VERSION "HNNBNNNYNNNNNNNNNNNNNNNNNNNNNNNNNNNNNNNNNN/4/%%%/4/'%**4NNN///"

NS_ :

BS_:

BU_: BAP_Tester Booster_AMP DSP_SKODA Gateway_PQ35 Gateway_PQ46 GSM_Pager Kompassmodul MDI Radio_2DIN Radio_Modul Radio_SKODA Rearview RNS_300_NF RNS_MFD2 RNS_midline SDARS_Tuner Sprachbedienung Standheizung Tastatur Telematik_Basis TV_hybrid UHV_High UHV_low UHV_NAR UHV_Premium UHV_UMTS

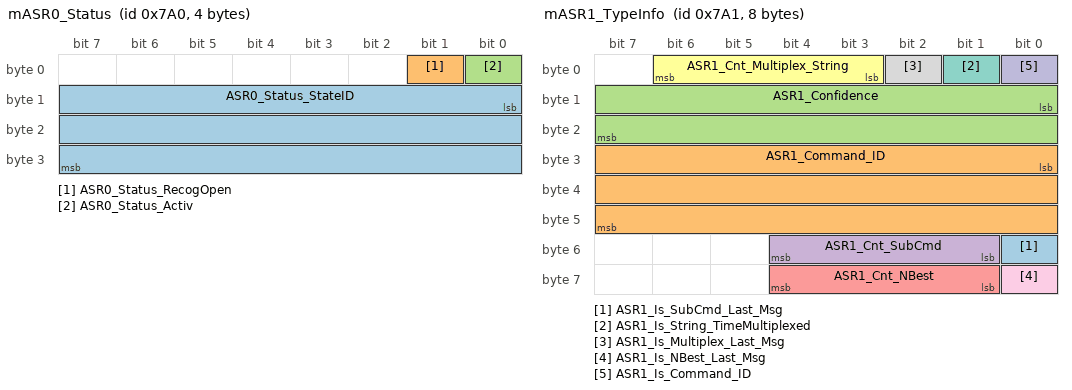
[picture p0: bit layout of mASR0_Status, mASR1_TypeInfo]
BO_ 1952 mASR0_Status: 4 UHV_NAR
 SG_ ASR0_Status_StateID : 8|24@1+ (1,8) [0|0] "" Vector__XXX
 SG_ ASR0_Status_RecogOpen : 1|1@1+ (1,0) [0|1] "" Vector__XXX
 SG_ ASR0_Status_Activ : 0|1@1+ (1,0) [0|1] "" Vector__XXX

BO_ 1953 mASR1_TypeInfo: 8 UHV_NAR
 SG_ ASR1_Is_SubCmd_Last_Msg : 48|1@1+ (1,0) [0|0] "" Vector__XXX
 SG_ ASR1_Command_ID : 24|24@1+ (1,0) [0|0] "" Vector__XXX
 SG_ ASR1_Confidence : 8|16@1+ (1,0) [0|10000] "" Vector__XXX
 SG_ ASR1_Cnt_SubCmd : 49|4@1+ (1,0) [0|15] "" Vector__XXX
 SG_ ASR1_Cnt_NBest : 57|4@1+ (1,0) [0|15] "" Vector__XXX
 SG_ ASR1_Cnt_Multiplex_String : 3|4@1+ (1,0) [0|1] "" Vector__XXX
 SG_ ASR1_Is_String_TimeMultiplexed : 1|1@1+ (1,0) [0|1] "" Vector__XXX
 SG_ ASR1_Is_Multiplex_Last_Msg : 2|1@1+ (1,0) [0|1] "" Vector__XXX
 SG_ ASR1_Is_NBest_Last_Msg : 56|1@1+ (1,0) [0|1] "" Vector__XXX
 SG_ ASR1_Is_Command_ID : 0|1@1+ (1,0) [0|1] "" Vector__XXX

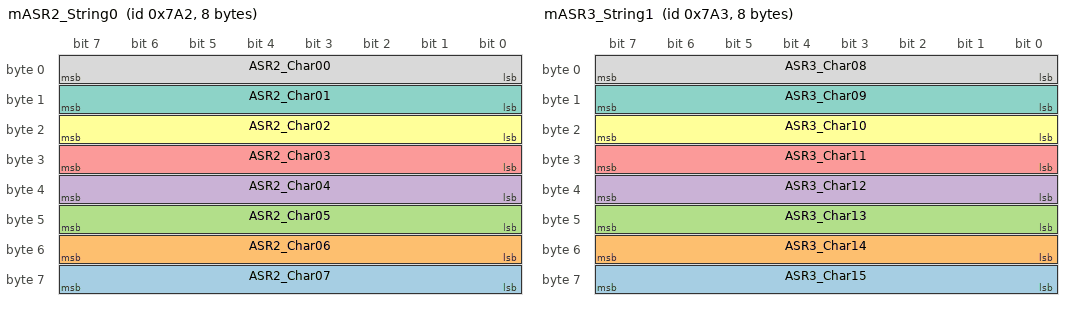
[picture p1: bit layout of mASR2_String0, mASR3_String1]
BO_ 1954 mASR2_String0: 8 UHV_NAR
 SG_ ASR2_Char07 : 56|8@1+ (1,0) [0|0] "" Vector__XXX
 SG_ ASR2_Char06 : 48|8@1+ (1,0) [0|0] "" Vector__XXX
 SG_ ASR2_Char05 : 40|8@1+ (1,0) [0|0] "" Vector__XXX
 SG_ ASR2_Char04 : 32|8@1+ (1,0) [0|0] "" Vector__XXX
 SG_ ASR2_Char03 : 24|8@1+ (1,0) [0|0] "" Vector__XXX
 SG_ ASR2_Char02 : 16|8@1+ (1,0) [0|0] "" Vector__XXX
 SG_ ASR2_Char01 : 8|8@1+ (1,0) [0|0] "" Vector__XXX
 SG_ ASR2_Char00 : 0|8@1+ (1,0) [0|0] "" Vector__XXX

BO_ 1955 mASR3_String1: 8 UHV_NAR
 SG_ ASR3_Char15 : 56|8@1+ (1,0) [0|0] "" Vector__XXX
 SG_ ASR3_Char14 : 48|8@1+ (1,0) [0|0] "" Vector__XXX
 SG_ ASR3_Char13 : 40|8@1+ (1,0) [0|0] "" Vector__XXX
 SG_ ASR3_Char12 : 32|8@1+ (1,0) [0|0] "" Vector__XXX
 SG_ ASR3_Char11 : 24|8@1+ (1,0) [0|0] "" Vector__XXX
 SG_ ASR3_Char10 : 16|8@1+ (1,0) [0|0] "" Vector__XXX
 SG_ ASR3_Char09 : 8|8@1+ (1,0) [0|0] "" Vector__XXX
 SG_ ASR3_Char08 : 0|8@1+ (1,0) [0|0] "" Vector__XXX

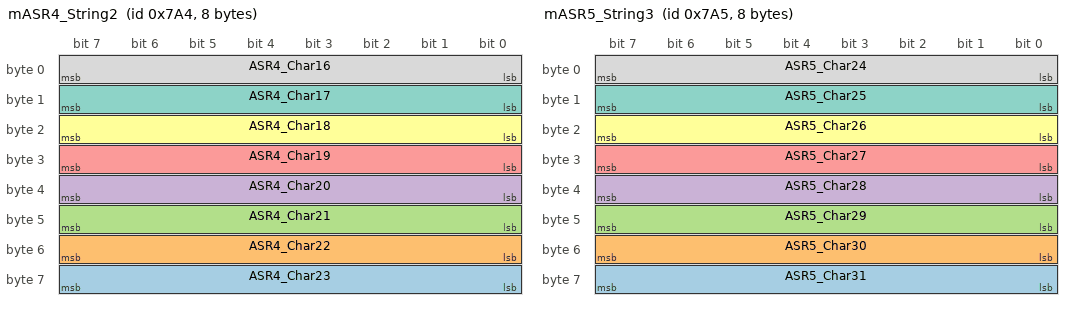
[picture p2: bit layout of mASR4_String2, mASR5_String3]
BO_ 1956 mASR4_String2: 8 UHV_NAR
 SG_ ASR4_Char23 : 56|8@1+ (1,0) [0|0] "" Vector__XXX
 SG_ ASR4_Char22 : 48|8@1+ (1,0) [0|0] "" Vector__XXX
 SG_ ASR4_Char21 : 40|8@1+ (1,0) [0|0] "" Vector__XXX
 SG_ ASR4_Char20 : 32|8@1+ (1,0) [0|0] "" Vector__XXX
 SG_ ASR4_Char19 : 24|8@1+ (1,0) [0|0] "" Vector__XXX
 SG_ ASR4_Char18 : 16|8@1+ (1,0) [0|0] "" Vector__XXX
 SG_ ASR4_Char17 : 8|8@1+ (1,0) [0|0] "" Vector__XXX
 SG_ ASR4_Char16 : 0|8@1+ (1,0) [0|0] "" Vector__XXX

BO_ 1957 mASR5_String3: 8 UHV_NAR
 SG_ ASR5_Char31 : 56|8@1+ (1,0) [0|0] "" Vector__XXX
 SG_ ASR5_Char30 : 48|8@1+ (1,0) [0|0] "" Vector__XXX
 SG_ ASR5_Char29 : 40|8@1+ (1,0) [0|0] "" Vector__XXX
 SG_ ASR5_Char28 : 32|8@1+ (1,0) [0|0] "" Vector__XXX
 SG_ ASR5_Char27 : 24|8@1+ (1,0) [0|0] "" Vector__XXX
 SG_ ASR5_Char26 : 16|8@1+ (1,0) [0|0] "" Vector__XXX
 SG_ ASR5_Char25 : 8|8@1+ (1,0) [0|0] "" Vector__XXX
 SG_ ASR5_Char24 : 0|8@1+ (1,0) [0|0] "" Vector__XXX

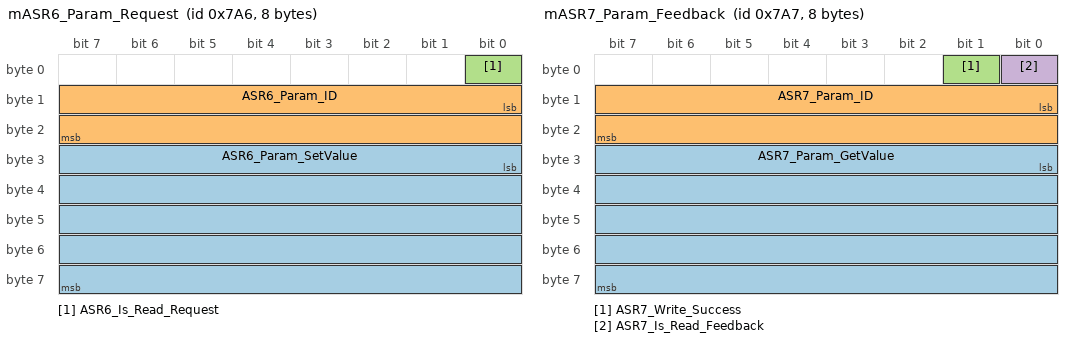
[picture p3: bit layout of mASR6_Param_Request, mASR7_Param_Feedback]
BO_ 1958 mASR6_Param_Request: 8 Vector__XXX
 SG_ ASR6_Param_SetValue : 24|40@1+ (1,0) [0|0] ""  UHV_NAR
 SG_ ASR6_Param_ID : 8|16@1+ (1,0) [0|0] ""  UHV_NAR
 SG_ ASR6_Is_Read_Request : 0|1@1+ (1,0) [0|1] ""  UHV_NAR

BO_ 1959 mASR7_Param_Feedback: 8 Vector__XXX
 SG_ ASR7_Param_GetValue : 24|40@1+ (1,0) [0|0] ""  UHV_NAR
 SG_ ASR7_Param_ID : 8|16@1+ (1,0) [0|0] ""  UHV_NAR
 SG_ ASR7_Write_Success : 1|1@1+ (1,0) [0|1] ""  UHV_NAR
 SG_ ASR7_Is_Read_Feedback : 0|1@1+ (1,0) [0|1] ""  UHV_NAR

BO_ 1658 BAP_Anzeige_02: 8 Radio_Modul
 SG_ BAP_Data_Anzeige_02 : 0|16@1+ (1,0) [0|65535] ""  Gateway_PQ35,Gateway_PQ46

BO_ 1753 BAP_Anzeige_RV: 8 Vector__XXX
 SG_ BAP_Data_Anzeige_RV : 0|16@1+ (1,0) [0|65535] ""  Gateway_PQ35,Gateway_PQ46

BO_ 1737 BAP_ASG_02: 8 Gateway_PQ35
 SG_ BAP_Data_ASG_02 : 0|16@1+ (1,0) [0|65535] ""  Standheizung

BO_ 1735 BAP_ASG_03: 8 Radio_Modul
 SG_ BAP_Data_ASG_03 : 0|16@1+ (1,0) [0|65535] ""  Booster_AMP,TV_hybrid,UHV_High,UHV_NAR,UHV_Premium,UHV_UMTS

BO_ 1738 BAP_ASG_04: 8 Radio_Modul
 SG_ BAP_Data_ASG_04 : 0|16@1+ (1,0) [0|65535] ""  Rearview

BO_ 1739 BAP_ASG_05: 8 Radio_Modul
 SG_ BAP_Data_ASG_05 : 0|16@1+ (1,0) [0|65535] ""  Gateway_PQ35,Gateway_PQ46

BO_ 1734 BAP_ASG_06: 8 Radio_Modul
 SG_ BAP_Data_ASG_06 : 0|16@1+ (1,0) [0|65535] ""  MDI,UHV_High,UHV_NAR,UHV_Premium,UHV_UMTS

BO_ 1660 BAP_ASG_07: 8 Gateway_PQ35
 SG_ BAP_Data_ASG_07 : 0|16@1+ (1,0) [0|65535] ""  Kompassmodul,Radio_2DIN,Radio_Modul,RNS_300_NF,RNS_midline,UHV_High,UHV_NAR,UHV_Premium,UHV_UMTS

BO_ 1733 BAP_ASG_08: 8 Radio_Modul
 SG_ BAP_Data_ASG_08 : 0|16@1+ (1,0) [0|65535] ""  Booster_AMP

BO_ 1774 BAP_ASG_09: 8 RNS_midline
 SG_ BAP_Data_ASG_09 : 0|16@1+ (1,0) [0|65535] ""  Gateway_PQ35,Gateway_PQ46

BO_ 1644 BAP_AUDIO: 8 Radio_2DIN
 SG_ BAP_Data_AUDIO : 0|16@1+ (1,0) [0|65535] ""  Gateway_PQ35,Gateway_PQ46

BO_ 1768 BAP_BC: 8 Gateway_PQ35
 SG_ BAP_Data_BC : 0|16@1+ (1,0) [0|65535] ""  RNS_midline

BO_ 1755 BAP_Clima: 8 Gateway_PQ35
 SG_ BAP_Data_Clima : 0|16@1+ (1,0) [0|65535] ""  Radio_Modul,RNS_300_NF,RNS_midline

BO_ 1750 BAP_Debug_Cmd: 8 BAP_Tester
 SG_ BAP_Data_Debug_Cmd : 0|16@1+ (1,0) [0|65535] ""  Booster_AMP,Kompassmodul,MDI,Radio_2DIN,Radio_Modul,Rearview,RNS_300_NF,RNS_midline,Standheizung,TV_hybrid,UHV_High,UHV_NAR,UHV_Premium,UHV_UMTS

BO_ 1751 BAP_Debug_Data: 7 Booster_AMP
 SG_ BAP_Debug_Data : 0|56@1+ (1,0) [0|4294967295] ""  BAP_Tester

BO_ 1752 BAP_DSP: 8 Booster_AMP
 SG_ BAP_Data_DSP : 0|16@1+ (1,0) [0|65535] ""  Radio_Modul,RNS_300_NF,RNS_midline

BO_ 1657 BAP_HYB: 8 Gateway_PQ35
 SG_ BAP_Data_HYB : 0|16@1+ (1,0) [0|65535] ""  RNS_midline

BO_ 1596 BAP_MDI: 8 MDI
 SG_ BAP_Data_MDI : 0|16@1+ (1,0) [0|65535] ""  Radio_Modul,RNS_300_NF,RNS_midline

BO_ 1580 BAP_MDI_02: 8 UHV_NAR
 SG_ BAP_Data_MDI_02 : 0|16@1+ (1,0) [0|65535] ""  Radio_Modul,RNS_300_NF,RNS_midline

BO_ 1661 BAP_NAVI: 8 Kompassmodul
 SG_ BAP_Data_NAVI : 0|16@1+ (1,0) [0|65535] ""  Gateway_PQ35,Gateway_PQ46

BO_ 1754 BAP_OPS: 8 Gateway_PQ35
 SG_ BAP_Data_OPS : 0|16@1+ (1,0) [0|65535] ""  Radio_Modul,RNS_300_NF,RNS_midline

BO_ 1756 BAP_RV: 8 Gateway_PQ35
 SG_ BAP_Data_Rearview : 0|16@1+ (1,0) [0|65535] ""  Radio_Modul,RNS_300_NF,RNS_midline

BO_ 1646 BAP_SHZ: 8 Standheizung
 SG_ BAP_Data_SHZ : 0|16@1+ (1,0) [0|65535] ""  Gateway_PQ35,Gateway_PQ46

BO_ 1746 BAP_Telefon_01: 8 UHV_High
 SG_ BAP_Data_Telefon_1 : 0|16@1+ (1,0) [0|65535] ""  Radio_Modul,RNS_300_NF,RNS_midline

BO_ 1749 BAP_Telefon_02: 8 UHV_High
 SG_ BAP_Data_Telefon_2 : 0|16@1+ (1,0) [0|65535] ""  Radio_Modul,RNS_300_NF,RNS_midline

BO_ 1595 BAP_Telefon_03: 8 UHV_High
 SG_ BAP_Data_Telefon_3 : 0|16@1+ (1,0) [0|65535] ""  Radio_Modul,RNS_300_NF,RNS_midline

BO_ 1647 BAP_Telefon_04: 8 UHV_High
 SG_ BAP_Data_Telefon_4 : 0|16@1+ (1,0) [0|65535] ""  Gateway_PQ35,Gateway_PQ46

BO_ 1747 BAP_TV_Tuner: 8 TV_hybrid
 SG_ BAP_Data_TV_Tuner : 0|16@1+ (1,0) [0|65535] ""  RNS_midline

BO_ 1903 ISO_AMP_Req: 8 Gateway_PQ35
 SG_ ISO_AMP_Req_Data : 0|64@1+ (1,0) [0|4294967295] ""  Booster_AMP

BO_ 2009 ISO_AMP_Resp: 8 Booster_AMP
 SG_ ISO_AMP_Resp_Data : 0|64@1+ (1,0) [0|4294967295] ""  Gateway_PQ35,Gateway_PQ46

BO_ 1792 ISO_Funktionaler_Req_All: 8 Gateway_PQ35
 SG_ ISO_ALL_01_Req_Data : 0|64@1+ (1,0) [0|4294967295] ""  Booster_AMP,Radio_Modul,RNS_300_NF,UHV_NAR,UHV_UMTS

BO_ 1907 ISO_Info_El_Req: 8 Gateway_PQ35
 SG_ ISO_Info_El_Req_Data : 0|64@1+ (1,0) [0|4294967295] "" Vector__XXX

BO_ 2013 ISO_Info_El_Resp: 8 Vector__XXX
 SG_ ISO_Info_El_Resp_Data : 0|64@1+ (1,0) [0|4294967295] ""  Gateway_PQ35,Gateway_PQ46

BO_ 1902 ISO_MDI_Req: 8 Gateway_PQ35
 SG_ ISO_MDI_Req_Data : 0|64@1+ (1,0) [0|4294967295] "" Vector__XXX

BO_ 2008 ISO_MDI_Resp: 8 Vector__XXX
 SG_ ISO_MDI_Resp_Data : 0|64@1+ (1,0) [0|4294967295] ""  Gateway_PQ35,Gateway_PQ46

BO_ 1900 ISO_Navi_Req: 8 Gateway_PQ35
 SG_ ISO_Navi_Req_Data : 0|64@1+ (1,0) [0|4294967295] ""  RNS_300_NF

BO_ 2006 ISO_Navi_Resp: 8 RNS_300_NF
 SG_ ISO_Navi_Resp_Data : 0|64@1+ (1,0) [0|4294967295] ""  Gateway_PQ35,Gateway_PQ46

BO_ 1816 ISO_Radio_Req: 8 Gateway_PQ35
 SG_ ISO_Radio_Req_Data : 0|64@1+ (1,0) [0|4294967295] ""  Radio_Modul

BO_ 1922 ISO_Radio_Resp: 8 Radio_Modul
 SG_ ISO_Radio_Resp_Data : 0|64@1+ (1,0) [0|4294967295] ""  Gateway_PQ35,Gateway_PQ46

BO_ 1899 ISO_Telefon_Req: 8 Gateway_PQ35
 SG_ ISO_Telefon_Req_Data : 0|64@1+ (1,0) [0|4294967295] ""  UHV_NAR,UHV_UMTS

BO_ 2005 ISO_Telefon_Resp: 8 UHV_NAR
 SG_ ISO_Telefon_Resp_Data : 0|64@1+ (1,0) [0|4294967295] ""  Gateway_PQ35,Gateway_PQ46

BO_ 1901 ISO_TV_Tuner_Req: 8 Gateway_PQ35
 SG_ ISO_TV_Tuner_Req_Data : 0|64@1+ (1,0) [0|4294967295] "" Vector__XXX

BO_ 2007 ISO_TV_Tuner_Resp: 8 Vector__XXX
 SG_ ISO_TV_Tuner_Resp_Data : 0|64@1+ (1,0) [0|4294967295] ""  Gateway_PQ35,Gateway_PQ46

BO_ 337 mAirbag_1: 4 Gateway_PQ35
 SG_ AB1_FrontCrash : 0|1@1+ (1,0) [0|1] ""  Telematik_Basis,UHV_NAR,UHV_UMTS
 SG_ AB1_HeckCrash : 1|1@1+ (1,0) [0|1] ""  Telematik_Basis,UHV_NAR,UHV_UMTS
 SG_ AB1_Crash_FT : 2|1@1+ (1,0) [0|1] ""  Telematik_Basis,UHV_NAR,UHV_UMTS
 SG_ AB1_Crash_BT : 3|1@1+ (1,0) [0|1] ""  Telematik_Basis,UHV_NAR,UHV_UMTS
 SG_ AB1_Rollover : 4|1@1+ (1,0) [0|1] ""  Telematik_Basis,UHV_NAR,UHV_UMTS
 SG_ AB1_CrashStaerke : 5|3@1+ (1,0) [0|7] ""  Standheizung,Telematik_Basis,UHV_NAR,UHV_UMTS
 SG_ AB1_AirbagLampe_ein : 8|1@1+ (1,0) [0|1] "" Vector__XXX
 SG_ AB1_Airbag_deaktiviert : 9|1@1+ (1,0) [0|1] "" Vector__XXX
 SG_ AB1_Beif_Airbag_deaktiviert : 10|1@1+ (1,0) [0|1] "" Vector__XXX
 SG_ AB1_Systemfehler : 11|1@1+ (1,0) [0|1] "" Vector__XXX
 SG_ AB1_Fa_Gurt : 12|2@1+ (1,0) [0|3] "" Vector__XXX
 SG_ AB1_Bf_Gurt : 14|2@1+ (1,0) [0|3] "" Vector__XXX
 SG_ AB1_Diagnose : 16|1@1+ (1,0) [0|1] "" Vector__XXX
 SG_ AB1_Stellglied : 17|1@1+ (1,0) [0|1] "" Vector__XXX
 SG_ AB1_BF_Anschnall : 18|1@1+ (1,0) [0|1] "" Vector__XXX
 SG_ AB1_KD_Fehler : 19|1@1+ (1,0) [0|1] "" Vector__XXX
 SG_ AB1_MessageZaehler : 20|4@1+ (1,0) [0|15] ""  Telematik_Basis
 SG_ AB1_Pruefsumme : 24|8@1+ (1,0) [0|255] ""  Telematik_Basis

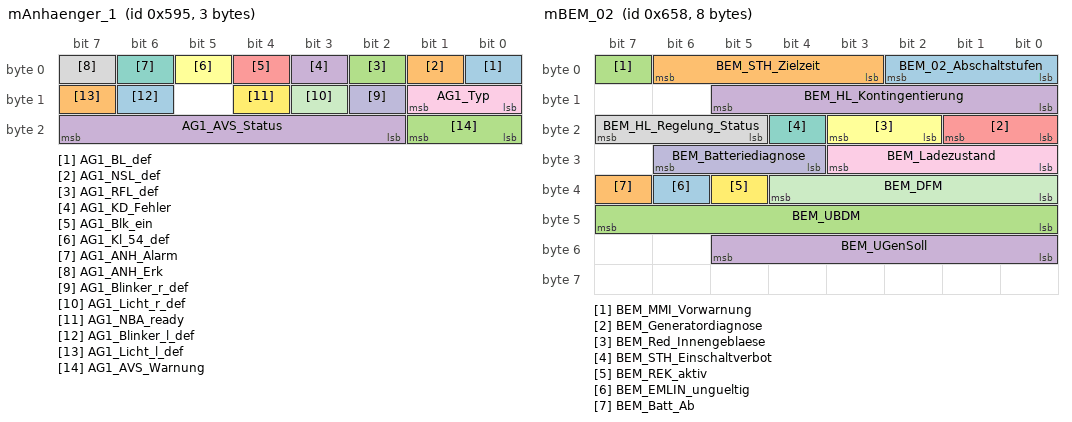
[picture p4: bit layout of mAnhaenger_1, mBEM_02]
BO_ 1429 mAnhaenger_1: 3 Gateway_PQ35
 SG_ AG1_BL_def : 0|1@1+ (1,0) [0|1] "" Vector__XXX
 SG_ AG1_NSL_def : 1|1@1+ (1,0) [0|1] "" Vector__XXX
 SG_ AG1_RFL_def : 2|1@1+ (1,0) [0|1] "" Vector__XXX
 SG_ AG1_KD_Fehler : 3|1@1+ (1,0) [0|1] "" Vector__XXX
 SG_ AG1_Blk_ein : 4|1@1+ (1,0) [0|1] "" Vector__XXX
 SG_ AG1_Kl_54_def : 5|1@1+ (1,0) [0|1] "" Vector__XXX
 SG_ AG1_ANH_Alarm : 6|1@1+ (1,0) [0|1] "" Vector__XXX
 SG_ AG1_ANH_Erk : 7|1@1+ (1,0) [0|1] ""  Rearview
 SG_ AG1_Typ : 8|2@1+ (1,0) [0|3] "" Vector__XXX
 SG_ AG1_Blinker_r_def : 10|1@1+ (1,0) [0|1] "" Vector__XXX
 SG_ AG1_Licht_r_def : 11|1@1+ (1,0) [0|1] "" Vector__XXX
 SG_ AG1_NBA_ready : 12|1@1+ (1,0) [0|1] "" Vector__XXX
 SG_ AG1_Blinker_l_def : 14|1@1+ (1,0) [0|1] "" Vector__XXX
 SG_ AG1_Licht_l_def : 15|1@1+ (1,0) [0|1] "" Vector__XXX
 SG_ AG1_AVS_Warnung : 16|2@1+ (1,0) [0|3] "" Vector__XXX
 SG_ AG1_AVS_Status : 18|6@1+ (1,0) [0|63] "" Vector__XXX

BO_ 1624 mBEM_02: 8 Gateway_PQ35
 SG_ BEM_02_Abschaltstufen : 0|3@1+ (1,0) [0|7] "" Vector__XXX
 SG_ BEM_STH_Zielzeit : 3|4@1+ (5,0) [0|60] "Unit_Minut" Vector__XXX
 SG_ BEM_MMI_Vorwarnung : 7|1@1+ (1,0) [0|1] "" Vector__XXX
 SG_ BEM_HL_Kontingentierung : 8|6@1+ (50,-1000) [-1000|1000] "Unit_Watt" Vector__XXX
 SG_ BEM_Generatordiagnose : 16|2@1+ (1,0) [0|3] "" Vector__XXX
 SG_ BEM_Red_Innengeblaese : 18|2@1+ (1,0) [0|3] "" Vector__XXX
 SG_ BEM_STH_Einschaltverbot : 20|1@1+ (1,0) [0|1] "" Vector__XXX
 SG_ BEM_HL_Regelung_Status : 21|3@1+ (1,0) [0|7] "" Vector__XXX
 SG_ BEM_Ladezustand : 24|4@1+ (10,0) [0|100] "Unit_PerCent" Vector__XXX
 SG_ BEM_Batteriediagnose : 28|3@1+ (1,0) [0|7] "" Vector__XXX
 SG_ BEM_DFM : 32|5@1+ (3.225,0.025) [0.025|100] "Unit_PerCent" Vector__XXX
 SG_ BEM_REK_aktiv : 37|1@1+ (1,0) [0|1] "" Vector__XXX
 SG_ BEM_EMLIN_ungueltig : 38|1@1+ (1,0) [0|1] "" Vector__XXX
 SG_ BEM_Batt_Ab : 39|1@1+ (1,0) [0|1] "" Vector__XXX
 SG_ BEM_UBDM : 40|8@1+ (0.05,5) [5|17.7] "Unit_Volt" Vector__XXX
 SG_ BEM_UGenSoll : 48|6@1+ (0.1,10.6) [10.6|16.8] "Unit_Volt" Vector__XXX

BO_ 1461 mBremse_10: 8 Gateway_PQ35
 SG_ B10_Checksumme : 0|8@1+ (1,0) [0|255] ""  RNS_300_NF
 SG_ B10_Zaehler : 8|4@1+ (1,0) [0|15] ""  RNS_300_NF
 SG_ B10_QB_Wegimp_VL : 12|1@1+ (1,0) [0|1] ""  RNS_300_NF
 SG_ B10_QB_Wegimp_VR : 13|1@1+ (1,0) [0|1] ""  RNS_300_NF
 SG_ B10_QB_Wegimp_HL : 14|1@1+ (1,0) [0|1] ""  RNS_300_NF
 SG_ B10_QB_Wegimp_HR : 15|1@1+ (1,0) [0|1] ""  RNS_300_NF
 SG_ B10_Wegimp_VL : 16|10@1+ (1,0) [0|1000] ""  RNS_300_NF
 SG_ B10_Wegimp_VR : 26|10@1+ (1,0) [0|1000] ""  RNS_300_NF
 SG_ B10_Wegimp_HL : 36|10@1+ (1,0) [0|1000] ""  RNS_300_NF
 SG_ B10_Wegimp_HR : 46|10@1+ (1,0) [0|1000] ""  RNS_300_NF
 SG_ B10_QB_Fahrtr_VL : 56|1@1+ (1,0) [0|1] ""  RNS_300_NF
 SG_ B10_QB_Fahrtr_VR : 57|1@1+ (1,0) [0|1] ""  RNS_300_NF
 SG_ B10_QB_Fahrtr_HL : 58|1@1+ (1,0) [0|1] ""  RNS_300_NF
 SG_ B10_QB_Fahrtr_HR : 59|1@1+ (1,0) [0|1] ""  RNS_300_NF
 SG_ B10_Fahrtr_VL : 60|1@1+ (1,0) [0|1] ""  RNS_300_NF
 SG_ B10_Fahrtr_VR : 61|1@1+ (1,0) [0|1] ""  RNS_300_NF
 SG_ B10_Fahrtr_HL : 62|1@1+ (1,0) [0|1] ""  RNS_300_NF
 SG_ B10_Fahrtr_HR : 63|1@1+ (1,0) [0|1] ""  RNS_300_NF

BO_ 1393 mBSG_2: 6 Gateway_PQ35
 SG_ BS2_U_BATT : 0|8@1+ (0.05,5) [5|17.7] "Unit_Volt"  GSM_Pager,Telematik_Basis
 SG_ BS2_Heckscheibe_aus : 8|1@1+ (1,0) [0|1] "" Vector__XXX
 SG_ BS2_Frontscheibe_aus : 9|1@1+ (1,0) [0|1] "" Vector__XXX
 SG_ BS2_Aussenspiegel_aus : 10|1@1+ (1,0) [0|1] "" Vector__XXX
 SG_ BS2_Sitzheizung_aus : 11|1@1+ (1,0) [0|1] "" Vector__XXX
 SG_ BS2_aus_Lenkradheizung : 12|1@1+ (1,0) [0|1] "" Vector__XXX
 SG_ BS2_aus_Wischwasserhzg : 13|1@1+ (1,0) [0|1] "" Vector__XXX
 SG_ BS2_aus_Sitzlueftung : 14|1@1+ (1,0) [0|1] "" Vector__XXX
 SG_ BS2_Klimaanlage_aus : 15|1@1+ (1,0) [0|1] "" Vector__XXX
 SG_ BS2_U_Start_BATT : 16|8@1+ (0.05,5) [5|17.7] "Unit_Volt" Vector__XXX
 SG_ BS2_Lastman_aktiv : 24|1@1+ (1,0) [0|1] "" Vector__XXX
 SG_ BS2_Verbr_ab_aktiv : 25|1@1+ (1,0) [0|1] "" Vector__XXX
 SG_ BS2_Notstart : 26|1@1+ (1,0) [0|1] "" Vector__XXX
 SG_ BS2_aus_Sitzhzg_H : 27|1@1+ (1,0) [0|1] "" Vector__XXX
 SG_ BS2_aus_Steckdosen : 28|1@1+ (1,0) [0|1] "" Vector__XXX
 SG_ BS2_aus_Zusatz_Verbr : 29|1@1+ (1,0) [0|1] "" Vector__XXX
 SG_ BS2_aus_Infotainment : 30|1@1+ (1,0) [0|1] ""  Booster_AMP,DSP_SKODA,Radio_2DIN,Radio_Modul,Radio_SKODA,RNS_300_NF,RNS_midline,UHV_low,UHV_NAR,UHV_Premium,UHV_UMTS
 SG_ BS2_Wake_Up_ACAN : 31|1@1+ (1,0) [0|1] "" Vector__XXX
 SG_ BS2_aus_PTC_Clima : 32|3@1+ (25,0) [0|100] "Unit_PerCent" Vector__XXX
 SG_ BS2_KlimaLeistRed : 35|2@1+ (1,0) [0|3] ""  Standheizung
 SG_ BS2_red_Heckscheibe : 37|1@1+ (1,0) [0|1] "" Vector__XXX
 SG_ BS2_aus_Ablage_Wischer : 38|1@1+ (1,0) [0|1] "" Vector__XXX
 SG_ BS2_aus_Innen_Bel : 39|1@1+ (1,0) [0|1] "" Vector__XXX
 SG_ BS2_Warn_Steckdosen : 40|1@1+ (1,0) [0|1] "" Vector__XXX
 SG_ BS2_Warn_Infotainment : 41|1@1+ (1,0) [0|1] ""  Booster_AMP,DSP_SKODA,Radio_2DIN,Radio_Modul,Radio_SKODA,RNS_300_NF,RNS_midline,Telematik_Basis,UHV_low,UHV_NAR,UHV_Premium,UHV_UMTS
 SG_ BS2_Warn_Zusatz : 42|1@1+ (1,0) [0|1] ""  Telematik_Basis
 SG_ BS2_Weckursache_ACAN : 43|2@1+ (1,0) [0|3] "" Vector__XXX
 SG_ BS2_VB_2_Battarie : 45|1@1+ (1,0) [0|1] ""  Standheizung
 SG_ BS2_Zust_Start_Ltg : 46|1@1+ (1,0) [0|1] "" Vector__XXX
 SG_ BS2_Mess_Start_Ltg : 47|1@1+ (1,0) [0|1] "" Vector__XXX

BO_ 1397 mBSG_3: 4 Gateway_PQ35
 SG_ BS3_Klemme_S : 0|1@1+ (1,0) [0|1] ""  Booster_AMP,DSP_SKODA,GSM_Pager,Kompassmodul,MDI,Radio_2DIN,Radio_Modul,Radio_SKODA,Rearview,RNS_300_NF,RNS_MFD2,RNS_midline,SDARS_Tuner,Sprachbedienung,Standheizung,Tastatur,Telematik_Basis,TV_hybrid,UHV_High,UHV_low,UHV_NAR,UHV_Premium,UHV_UMTS
 SG_ BS3_Klemme_15 : 1|1@1+ (1,0) [0|1] ""  Booster_AMP,DSP_SKODA,GSM_Pager,Kompassmodul,MDI,Radio_2DIN,Radio_Modul,Radio_SKODA,Rearview,RNS_300_NF,RNS_MFD2,RNS_midline,SDARS_Tuner,Sprachbedienung,Standheizung,Tastatur,Telematik_Basis,TV_hybrid,UHV_High,UHV_low,UHV_NAR,UHV_Premium,UHV_UMTS
 SG_ BS3_Klemme_X : 2|1@1+ (1,0) [0|1] ""  Radio_Modul,Standheizung,Telematik_Basis
 SG_ BS3_Klemme_50 : 3|1@1+ (1,0) [0|1] ""  Radio_2DIN,Radio_Modul,Standheizung,Telematik_Basis
 SG_ BS3_Klemme_P : 4|1@1+ (1,0) [0|1] ""  Telematik_Basis
 SG_ BS3_2_Drehzahl : 5|1@1+ (1,0) [0|1] "" Vector__XXX
 SG_ BS3_Klemme_15_Motorraum : 6|1@1+ (1,0) [0|1] "" Vector__XXX
 SG_ BS3_Ladekontrollampe : 7|1@1+ (1,0) [0|1] ""  GSM_Pager
 SG_ BS3_Drehzahlanhebung : 8|1@1+ (1,0) [0|1] "" Vector__XXX
 SG_ BS3_Bordnetzbatt : 9|2@1+ (1,0) [0|3] ""  Standheizung,Telematik_Basis
 SG_ BS3_Starterbatt : 11|2@1+ (1,0) [0|3] "" Vector__XXX
 SG_ BS3_KD_Fehler : 13|1@1+ (1,0) [0|1] "" Vector__XXX
 SG_ BS3_LWR_Fehler : 14|1@1+ (1,0) [0|1] "" Vector__XXX
 SG_ BS3_Haubenkontakt : 15|1@1+ (1,0) [0|1] "" Vector__XXX
 SG_ BS3_Coming_Home : 16|1@1+ (1,0) [0|1] "" Vector__XXX
 SG_ BS3_Leaving_Home : 17|1@1+ (1,0) [0|1] "" Vector__XXX
 SG_ BS3_K_Luefter_ein : 18|1@1+ (1,0) [0|1] "" Vector__XXX
 SG_ BS3_Ab_Batterie : 19|1@1+ (1,0) [0|1] "" Vector__XXX
 SG_ BS3_VP_Taste : 20|1@1+ (1,0) [0|1] "" Vector__XXX
 SG_ BS3_Verglasung_zu : 21|1@1+ (1,0) [0|1] "" Vector__XXX
 SG_ BS3_PDC_Taster : 22|1@1+ (1,0) [0|1] "" Vector__XXX
 SG_ BS3_IRUE_Taster : 23|1@1+ (1,0) [0|1] "" Vector__XXX
 SG_ BS3_VB_Coming_Home : 24|1@1+ (1,0) [0|1] "" Vector__XXX
 SG_ BS3_VB_Tagesfahrlicht : 25|1@1+ (1,0) [0|1] "" Vector__XXX
 SG_ BS3_VB_Fussraumleuchten : 26|1@1+ (1,0) [0|1] "" Vector__XXX
 SG_ BS3_LED_Heckscheibe : 27|1@1+ (1,0) [0|1] ""  Kompassmodul,Radio_SKODA
 SG_ BS3_LED_Frontscheibe : 28|1@1+ (1,0) [0|1] ""  Kompassmodul,Radio_SKODA
 SG_ BS3_LED_Sitze : 29|1@1+ (1,0) [0|1] "" Vector__XXX
 SG_ BS3_LED_Aussenspiegel : 30|1@1+ (1,0) [0|1] "" Vector__XXX
 SG_ BS3_Starterlaubnis : 31|1@1+ (1,0) [0|1] "" Vector__XXX

BO_ 1136 mBSG_Kombi: 8 Gateway_PQ35
 SG_ BSK_Blk_links : 0|1@1+ (1,0) [0|1] "" Vector__XXX
 SG_ BSK_Blk_rechts : 1|1@1+ (1,0) [0|1] "" Vector__XXX
 SG_ BSK_Anhaenger : 2|1@1+ (1,0) [0|1] "" Vector__XXX
 SG_ BSK_Warnblinker : 3|1@1+ (1,0) [0|1] "" Vector__XXX
 SG_ BSK_DWA_Akku : 4|1@1+ (1,0) [0|1] "" Vector__XXX
 SG_ BSK_Rueckfahrlicht : 5|1@1+ (1,0) [0|1] ""  Radio_Modul,RNS_300_NF,RNS_MFD2
 SG_ BSK_Sammelfehler_AKI : 6|1@1+ (1,0) [0|1] "" Vector__XXX
 SG_ BSK_Ladekontrollampe : 7|1@1+ (1,0) [0|1] "" Vector__XXX
 SG_ BSK_FT_geoeffnet : 8|1@1+ (1,0) [0|1] ""  Radio_Modul,RNS_300_NF,RNS_MFD2,RNS_midline
 SG_ BSK_BT_geoeffnet : 9|1@1+ (1,0) [0|1] ""  Radio_Modul
 SG_ BSK_HL_geoeffnet : 10|1@1+ (1,0) [0|1] ""  Radio_Modul
 SG_ BSK_HR_geoeffnet : 11|1@1+ (1,0) [0|1] ""  Radio_Modul
 SG_ BSK_MH_geoeffnet : 12|1@1+ (1,0) [0|1] "" Vector__XXX
 SG_ BSK_HD_Hauptraste : 13|1@1+ (1,0) [0|1] ""  Rearview
 SG_ BSK_HD_Vorraste : 14|1@1+ (1,0) [0|1] "" Vector__XXX
 SG_ BSK_Unterspannung : 15|1@1+ (1,0) [0|1] "" Vector__XXX
 SG_ BSK_Display : 16|7@1+ (1,0) [0|100] "Unit_PerCent" Vector__XXX
 SG_ BSK_Display_def : 23|1@1+ (1,0) [0|1] "" Vector__XXX
 SG_ BSK_Klemme_58t : 24|7@1+ (1,0) [0|100] "Unit_PerCent" Vector__XXX
 SG_ BSK_Klemme_58t_def : 31|1@1+ (1,0) [0|1] "" Vector__XXX
 SG_ BSK_Interlock : 32|1@1+ (1,0) [0|1] "" Vector__XXX
 SG_ BSK_Buzzer : 33|1@1+ (1,0) [0|1] "" Vector__XXX
 SG_ BSK_Ruecks_HL_verriegelt : 34|1@1+ (1,0) [0|1] "" Vector__XXX
 SG_ BSK_Ruecks_HR_verriegelt : 35|1@1+ (1,0) [0|1] "" Vector__XXX
 SG_ BSK_Def_Lampe : 36|1@1+ (1,0) [0|1] "" Vector__XXX
 SG_ BSK_NSL_LED_Pfad : 37|1@1+ (1,0) [0|1] "" Vector__XXX
 SG_ BSK_AFL_defekt : 38|1@1+ (1,0) [0|1] "" Vector__XXX
 SG_ BSK_BSG_defekt : 39|1@1+ (1,0) [0|1] "" Vector__XXX
 SG_ BSK_Standlicht : 40|1@1+ (1,0) [0|1] "" Vector__XXX
 SG_ BSK_Parklicht_links : 41|1@1+ (1,0) [0|1] "" Vector__XXX
 SG_ BSK_Parklicht_rechts : 42|1@1+ (1,0) [0|1] "" Vector__XXX
 SG_ BSK_Abblendlicht : 43|1@1+ (1,0) [0|1] "" Vector__XXX
 SG_ BSK_Nebellicht : 44|1@1+ (1,0) [0|1] "" Vector__XXX
 SG_ BSK_Heckscheibenhzg : 45|1@1+ (1,0) [0|1] "" Vector__XXX
 SG_ BSK_Tankklappe : 46|1@1+ (1,0) [0|1] "" Vector__XXX
 SG_ BSK_FFB_Bat : 47|1@1+ (1,0) [0|1] "" Vector__XXX
 SG_ BSK_FLA_Soft_LED : 48|1@1+ (1,0) [0|1] "" Vector__XXX
 SG_ BSK_FLA_Sensor_blockiert : 49|1@1+ (1,0) [0|1] "" Vector__XXX
 SG_ BSK_FLA_Defekt : 50|1@1+ (1,0) [0|1] "" Vector__XXX
 SG_ BCM_Remotestart_Betrieb : 55|1@1+ (1,0) [0|1] ""  MDI,RNS_300_NF,RNS_midline,UHV_NAR
 SG_ BSK_Ruhespannung : 56|5@1+ (0.1,10.5) [10.6|13.5] "Unit_Volt" Vector__XXX
 SG_ BSK_Nebelschlusslicht : 61|1@1+ (1,0) [0|1] "" Vector__XXX
 SG_ BSK_Fernlicht : 62|1@1+ (1,0) [0|1] "" Vector__XXX
 SG_ BSK_Tagfahrlicht : 63|1@1+ (1,0) [0|1] "" Vector__XXX

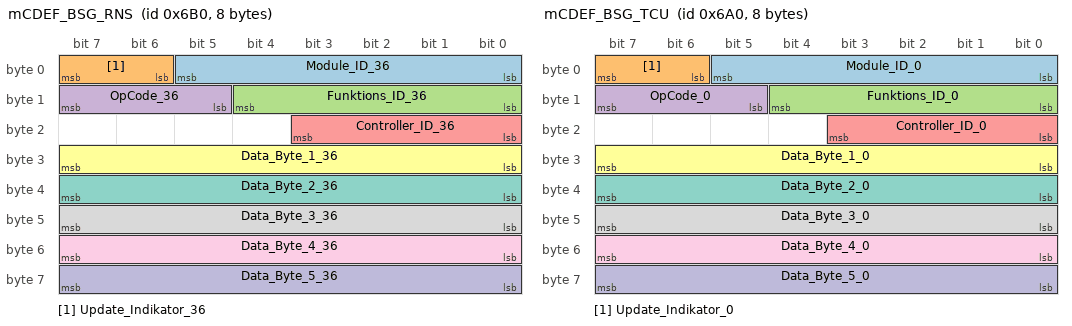
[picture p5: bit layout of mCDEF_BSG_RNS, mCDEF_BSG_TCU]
BO_ 1712 mCDEF_BSG_RNS: 8 Gateway_PQ35
 SG_ Module_ID_36 : 0|6@1+ (1,0) [0|63] "" Vector__XXX
 SG_ Update_Indikator_36 : 6|2@1+ (1,0) [0|3] "" Vector__XXX
 SG_ Funktions_ID_36 : 8|5@1+ (1,0) [0|31] "" Vector__XXX
 SG_ OpCode_36 : 13|3@1+ (1,0) [0|7] "" Vector__XXX
 SG_ Controller_ID_36 : 16|4@1+ (1,0) [0|15] "" Vector__XXX
 SG_ Data_Byte_1_36 : 24|8@1+ (1,0) [0|255] "" Vector__XXX
 SG_ Data_Byte_2_36 : 32|8@1+ (1,0) [0|255] "" Vector__XXX
 SG_ Data_Byte_3_36 : 40|8@1+ (1,0) [0|255] "" Vector__XXX
 SG_ Data_Byte_4_36 : 48|8@1+ (1,0) [0|255] "" Vector__XXX
 SG_ Data_Byte_5_36 : 56|8@1+ (1,0) [0|255] "" Vector__XXX

BO_ 1696 mCDEF_BSG_TCU: 8 Gateway_PQ35
 SG_ Module_ID_0 : 0|6@1+ (1,0) [0|63] "" Vector__XXX
 SG_ Update_Indikator_0 : 6|2@1+ (1,0) [0|3] "" Vector__XXX
 SG_ Funktions_ID_0 : 8|5@1+ (1,0) [0|31] "" Vector__XXX
 SG_ OpCode_0 : 13|3@1+ (1,0) [0|7] "" Vector__XXX
 SG_ Controller_ID_0 : 16|4@1+ (1,0) [0|15] "" Vector__XXX
 SG_ Data_Byte_1_0 : 24|8@1+ (1,0) [0|255] "" Vector__XXX
 SG_ Data_Byte_2_0 : 32|8@1+ (1,0) [0|255] "" Vector__XXX
 SG_ Data_Byte_3_0 : 40|8@1+ (1,0) [0|255] "" Vector__XXX
 SG_ Data_Byte_4_0 : 48|8@1+ (1,0) [0|255] "" Vector__XXX
 SG_ Data_Byte_5_0 : 56|8@1+ (1,0) [0|255] "" Vector__XXX

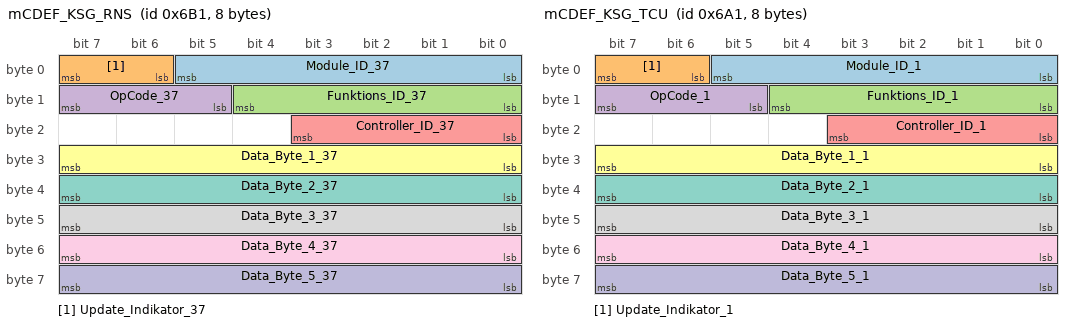
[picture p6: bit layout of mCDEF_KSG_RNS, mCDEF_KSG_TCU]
BO_ 1713 mCDEF_KSG_RNS: 8 Gateway_PQ35
 SG_ Module_ID_37 : 0|6@1+ (1,0) [0|63] "" Vector__XXX
 SG_ Update_Indikator_37 : 6|2@1+ (1,0) [0|3] "" Vector__XXX
 SG_ Funktions_ID_37 : 8|5@1+ (1,0) [0|31] "" Vector__XXX
 SG_ OpCode_37 : 13|3@1+ (1,0) [0|7] "" Vector__XXX
 SG_ Controller_ID_37 : 16|4@1+ (1,0) [0|15] "" Vector__XXX
 SG_ Data_Byte_1_37 : 24|8@1+ (1,0) [0|255] "" Vector__XXX
 SG_ Data_Byte_2_37 : 32|8@1+ (1,0) [0|255] "" Vector__XXX
 SG_ Data_Byte_3_37 : 40|8@1+ (1,0) [0|255] "" Vector__XXX
 SG_ Data_Byte_4_37 : 48|8@1+ (1,0) [0|255] "" Vector__XXX
 SG_ Data_Byte_5_37 : 56|8@1+ (1,0) [0|255] "" Vector__XXX

BO_ 1697 mCDEF_KSG_TCU: 8 Gateway_PQ35
 SG_ Module_ID_1 : 0|6@1+ (1,0) [0|63] "" Vector__XXX
 SG_ Update_Indikator_1 : 6|2@1+ (1,0) [0|3] "" Vector__XXX
 SG_ Funktions_ID_1 : 8|5@1+ (1,0) [0|31] "" Vector__XXX
 SG_ OpCode_1 : 13|3@1+ (1,0) [0|7] "" Vector__XXX
 SG_ Controller_ID_1 : 16|4@1+ (1,0) [0|15] "" Vector__XXX
 SG_ Data_Byte_1_1 : 24|8@1+ (1,0) [0|255] "" Vector__XXX
 SG_ Data_Byte_2_1 : 32|8@1+ (1,0) [0|255] "" Vector__XXX
 SG_ Data_Byte_3_1 : 40|8@1+ (1,0) [0|255] "" Vector__XXX
 SG_ Data_Byte_4_1 : 48|8@1+ (1,0) [0|255] "" Vector__XXX
 SG_ Data_Byte_5_1 : 56|8@1+ (1,0) [0|255] "" Vector__XXX

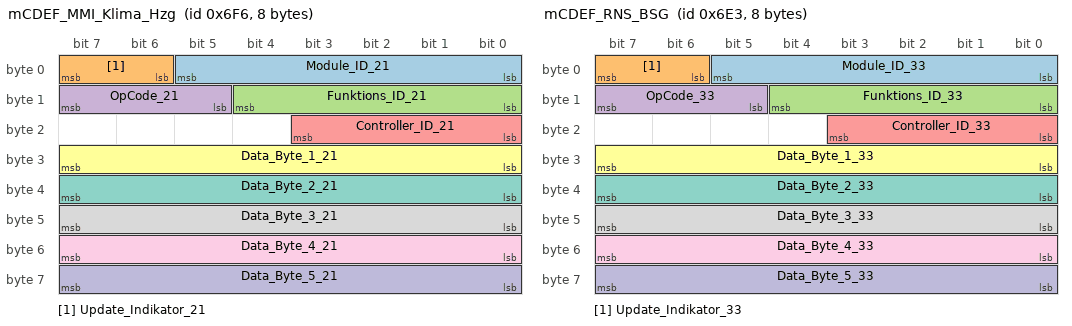
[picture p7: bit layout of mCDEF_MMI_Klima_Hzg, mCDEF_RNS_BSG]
BO_ 1782 mCDEF_MMI_Klima_Hzg: 8 Gateway_PQ35
 SG_ Module_ID_21 : 0|6@1+ (1,0) [0|63] "" Vector__XXX
 SG_ Update_Indikator_21 : 6|2@1+ (1,0) [0|3] "" Vector__XXX
 SG_ Funktions_ID_21 : 8|5@1+ (1,0) [0|31] "" Vector__XXX
 SG_ OpCode_21 : 13|3@1+ (1,0) [0|7] "" Vector__XXX
 SG_ Controller_ID_21 : 16|4@1+ (1,0) [0|15] "" Vector__XXX
 SG_ Data_Byte_1_21 : 24|8@1+ (1,0) [0|255] "" Vector__XXX
 SG_ Data_Byte_2_21 : 32|8@1+ (1,0) [0|255] "" Vector__XXX
 SG_ Data_Byte_3_21 : 40|8@1+ (1,0) [0|255] "" Vector__XXX
 SG_ Data_Byte_4_21 : 48|8@1+ (1,0) [0|255] "" Vector__XXX
 SG_ Data_Byte_5_21 : 56|8@1+ (1,0) [0|255] "" Vector__XXX

BO_ 1763 mCDEF_RNS_BSG: 8 Vector__XXX
 SG_ Module_ID_33 : 0|6@1+ (1,0) [0|63] ""  Gateway_PQ35,Gateway_PQ46
 SG_ Update_Indikator_33 : 6|2@1+ (1,0) [0|3] ""  Gateway_PQ35,Gateway_PQ46
 SG_ Funktions_ID_33 : 8|5@1+ (1,0) [0|31] ""  Gateway_PQ35,Gateway_PQ46
 SG_ OpCode_33 : 13|3@1+ (1,0) [0|7] ""  Gateway_PQ35,Gateway_PQ46
 SG_ Controller_ID_33 : 16|4@1+ (1,0) [0|15] ""  Gateway_PQ35,Gateway_PQ46
 SG_ Data_Byte_1_33 : 24|8@1+ (1,0) [0|255] ""  Gateway_PQ35,Gateway_PQ46
 SG_ Data_Byte_2_33 : 32|8@1+ (1,0) [0|255] ""  Gateway_PQ35,Gateway_PQ46
 SG_ Data_Byte_3_33 : 40|8@1+ (1,0) [0|255] ""  Gateway_PQ35,Gateway_PQ46
 SG_ Data_Byte_4_33 : 48|8@1+ (1,0) [0|255] ""  Gateway_PQ35,Gateway_PQ46
 SG_ Data_Byte_5_33 : 56|8@1+ (1,0) [0|255] ""  Gateway_PQ35,Gateway_PQ46

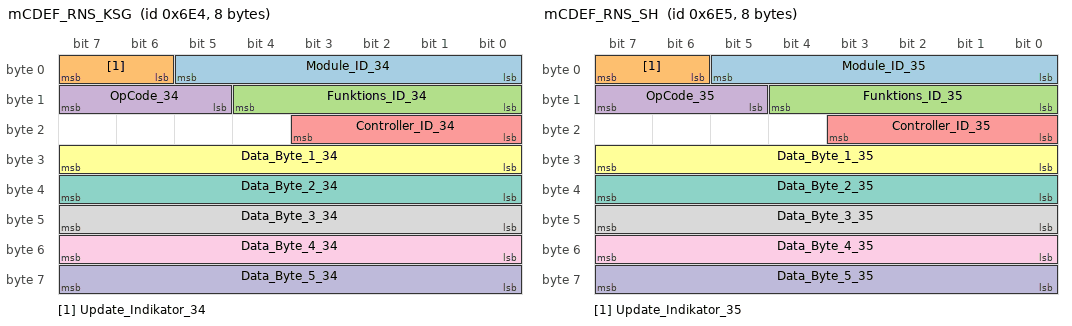
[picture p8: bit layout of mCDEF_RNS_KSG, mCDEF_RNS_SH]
BO_ 1764 mCDEF_RNS_KSG: 8 Vector__XXX
 SG_ Module_ID_34 : 0|6@1+ (1,0) [0|63] ""  Gateway_PQ35,Gateway_PQ46
 SG_ Update_Indikator_34 : 6|2@1+ (1,0) [0|3] ""  Gateway_PQ35,Gateway_PQ46
 SG_ Funktions_ID_34 : 8|5@1+ (1,0) [0|31] ""  Gateway_PQ35,Gateway_PQ46
 SG_ OpCode_34 : 13|3@1+ (1,0) [0|7] ""  Gateway_PQ35,Gateway_PQ46
 SG_ Controller_ID_34 : 16|4@1+ (1,0) [0|15] ""  Gateway_PQ35,Gateway_PQ46
 SG_ Data_Byte_1_34 : 24|8@1+ (1,0) [0|255] ""  Gateway_PQ35,Gateway_PQ46
 SG_ Data_Byte_2_34 : 32|8@1+ (1,0) [0|255] ""  Gateway_PQ35,Gateway_PQ46
 SG_ Data_Byte_3_34 : 40|8@1+ (1,0) [0|255] ""  Gateway_PQ35,Gateway_PQ46
 SG_ Data_Byte_4_34 : 48|8@1+ (1,0) [0|255] ""  Gateway_PQ35,Gateway_PQ46
 SG_ Data_Byte_5_34 : 56|8@1+ (1,0) [0|255] ""  Gateway_PQ35,Gateway_PQ46

BO_ 1765 mCDEF_RNS_SH: 8 Vector__XXX
 SG_ Module_ID_35 : 0|6@1+ (1,0) [0|63] ""  Gateway_PQ35,Gateway_PQ46,Standheizung
 SG_ Update_Indikator_35 : 6|2@1+ (1,0) [0|3] ""  Gateway_PQ35,Gateway_PQ46,Standheizung
 SG_ Funktions_ID_35 : 8|5@1+ (1,0) [0|31] ""  Gateway_PQ35,Gateway_PQ46,Standheizung
 SG_ OpCode_35 : 13|3@1+ (1,0) [0|7] ""  Gateway_PQ35,Gateway_PQ46,Standheizung
 SG_ Controller_ID_35 : 16|4@1+ (1,0) [0|15] ""  Gateway_PQ35,Gateway_PQ46,Standheizung
 SG_ Data_Byte_1_35 : 24|8@1+ (1,0) [0|255] ""  Gateway_PQ35,Gateway_PQ46,Standheizung
 SG_ Data_Byte_2_35 : 32|8@1+ (1,0) [0|255] ""  Gateway_PQ35,Gateway_PQ46,Standheizung
 SG_ Data_Byte_3_35 : 40|8@1+ (1,0) [0|255] ""  Gateway_PQ35,Gateway_PQ46,Standheizung
 SG_ Data_Byte_4_35 : 48|8@1+ (1,0) [0|255] ""  Gateway_PQ35,Gateway_PQ46,Standheizung
 SG_ Data_Byte_5_35 : 56|8@1+ (1,0) [0|255] ""  Gateway_PQ35,Gateway_PQ46,Standheizung

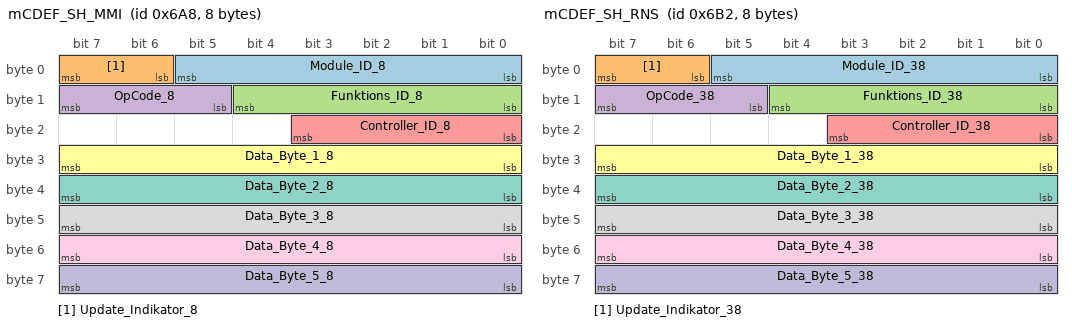
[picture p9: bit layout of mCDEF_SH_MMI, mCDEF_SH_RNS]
BO_ 1704 mCDEF_SH_MMI: 8 Standheizung
 SG_ Module_ID_8 : 0|6@1+ (1,0) [0|63] ""  Gateway_PQ35,Gateway_PQ46
 SG_ Update_Indikator_8 : 6|2@1+ (1,0) [0|3] ""  Gateway_PQ35,Gateway_PQ46
 SG_ Funktions_ID_8 : 8|5@1+ (1,0) [0|31] ""  Gateway_PQ35,Gateway_PQ46
 SG_ OpCode_8 : 13|3@1+ (1,0) [0|7] ""  Gateway_PQ35,Gateway_PQ46
 SG_ Controller_ID_8 : 16|4@1+ (1,0) [0|15] ""  Gateway_PQ35,Gateway_PQ46
 SG_ Data_Byte_1_8 : 24|8@1+ (1,0) [0|255] ""  Gateway_PQ35,Gateway_PQ46
 SG_ Data_Byte_2_8 : 32|8@1+ (1,0) [0|255] ""  Gateway_PQ35,Gateway_PQ46
 SG_ Data_Byte_3_8 : 40|8@1+ (1,0) [0|255] ""  Gateway_PQ35,Gateway_PQ46
 SG_ Data_Byte_4_8 : 48|8@1+ (1,0) [0|255] ""  Gateway_PQ35,Gateway_PQ46
 SG_ Data_Byte_5_8 : 56|8@1+ (1,0) [0|255] ""  Gateway_PQ35,Gateway_PQ46

BO_ 1714 mCDEF_SH_RNS: 8 Gateway_PQ35
 SG_ Module_ID_38 : 0|6@1+ (1,0) [0|63] "" Vector__XXX
 SG_ Update_Indikator_38 : 6|2@1+ (1,0) [0|3] "" Vector__XXX
 SG_ Funktions_ID_38 : 8|5@1+ (1,0) [0|31] "" Vector__XXX
 SG_ OpCode_38 : 13|3@1+ (1,0) [0|7] "" Vector__XXX
 SG_ Controller_ID_38 : 16|4@1+ (1,0) [0|15] "" Vector__XXX
 SG_ Data_Byte_1_38 : 24|8@1+ (1,0) [0|255] "" Vector__XXX
 SG_ Data_Byte_2_38 : 32|8@1+ (1,0) [0|255] "" Vector__XXX
 SG_ Data_Byte_3_38 : 40|8@1+ (1,0) [0|255] "" Vector__XXX
 SG_ Data_Byte_4_38 : 48|8@1+ (1,0) [0|255] "" Vector__XXX
 SG_ Data_Byte_5_38 : 56|8@1+ (1,0) [0|255] "" Vector__XXX

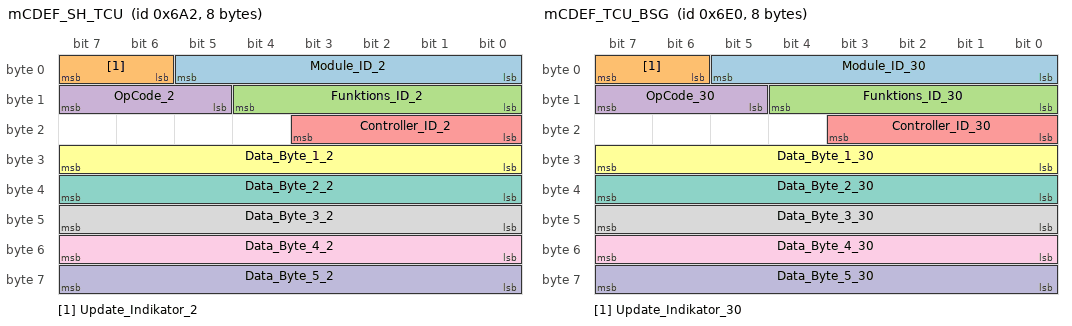
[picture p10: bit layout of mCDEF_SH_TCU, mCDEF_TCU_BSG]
BO_ 1698 mCDEF_SH_TCU: 8 Gateway_PQ35
 SG_ Module_ID_2 : 0|6@1+ (1,0) [0|63] "" Vector__XXX
 SG_ Update_Indikator_2 : 6|2@1+ (1,0) [0|3] "" Vector__XXX
 SG_ Funktions_ID_2 : 8|5@1+ (1,0) [0|31] "" Vector__XXX
 SG_ OpCode_2 : 13|3@1+ (1,0) [0|7] "" Vector__XXX
 SG_ Controller_ID_2 : 16|4@1+ (1,0) [0|15] "" Vector__XXX
 SG_ Data_Byte_1_2 : 24|8@1+ (1,0) [0|255] "" Vector__XXX
 SG_ Data_Byte_2_2 : 32|8@1+ (1,0) [0|255] "" Vector__XXX
 SG_ Data_Byte_3_2 : 40|8@1+ (1,0) [0|255] "" Vector__XXX
 SG_ Data_Byte_4_2 : 48|8@1+ (1,0) [0|255] "" Vector__XXX
 SG_ Data_Byte_5_2 : 56|8@1+ (1,0) [0|255] "" Vector__XXX

BO_ 1760 mCDEF_TCU_BSG: 8 Vector__XXX
 SG_ Module_ID_30 : 0|6@1+ (1,0) [0|63] ""  Gateway_PQ35,Gateway_PQ46
 SG_ Update_Indikator_30 : 6|2@1+ (1,0) [0|3] ""  Gateway_PQ35,Gateway_PQ46
 SG_ Funktions_ID_30 : 8|5@1+ (1,0) [0|31] ""  Gateway_PQ35,Gateway_PQ46
 SG_ OpCode_30 : 13|3@1+ (1,0) [0|7] ""  Gateway_PQ35,Gateway_PQ46
 SG_ Controller_ID_30 : 16|4@1+ (1,0) [0|15] ""  Gateway_PQ35,Gateway_PQ46
 SG_ Data_Byte_1_30 : 24|8@1+ (1,0) [0|255] ""  Gateway_PQ35,Gateway_PQ46
 SG_ Data_Byte_2_30 : 32|8@1+ (1,0) [0|255] ""  Gateway_PQ35,Gateway_PQ46
 SG_ Data_Byte_3_30 : 40|8@1+ (1,0) [0|255] ""  Gateway_PQ35,Gateway_PQ46
 SG_ Data_Byte_4_30 : 48|8@1+ (1,0) [0|255] ""  Gateway_PQ35,Gateway_PQ46
 SG_ Data_Byte_5_30 : 56|8@1+ (1,0) [0|255] ""  Gateway_PQ35,Gateway_PQ46

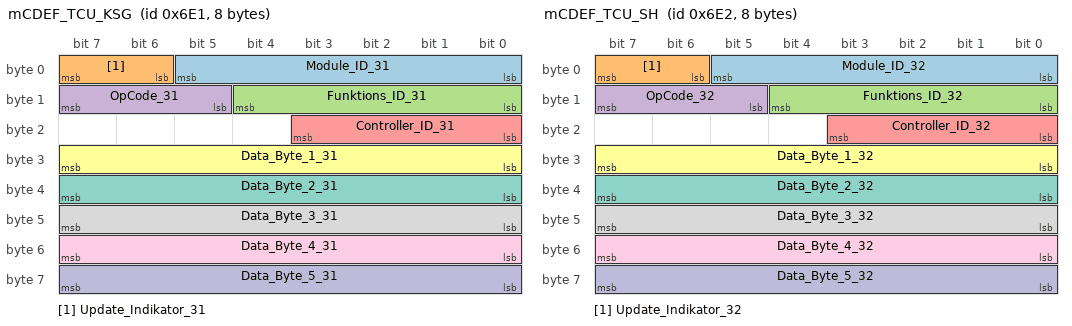
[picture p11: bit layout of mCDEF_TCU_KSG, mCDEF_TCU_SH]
BO_ 1761 mCDEF_TCU_KSG: 8 Vector__XXX
 SG_ Module_ID_31 : 0|6@1+ (1,0) [0|63] ""  Gateway_PQ35,Gateway_PQ46
 SG_ Update_Indikator_31 : 6|2@1+ (1,0) [0|3] ""  Gateway_PQ35,Gateway_PQ46
 SG_ Funktions_ID_31 : 8|5@1+ (1,0) [0|31] ""  Gateway_PQ35,Gateway_PQ46
 SG_ OpCode_31 : 13|3@1+ (1,0) [0|7] ""  Gateway_PQ35,Gateway_PQ46
 SG_ Controller_ID_31 : 16|4@1+ (1,0) [0|15] ""  Gateway_PQ35,Gateway_PQ46
 SG_ Data_Byte_1_31 : 24|8@1+ (1,0) [0|255] ""  Gateway_PQ35,Gateway_PQ46
 SG_ Data_Byte_2_31 : 32|8@1+ (1,0) [0|255] ""  Gateway_PQ35,Gateway_PQ46
 SG_ Data_Byte_3_31 : 40|8@1+ (1,0) [0|255] ""  Gateway_PQ35,Gateway_PQ46
 SG_ Data_Byte_4_31 : 48|8@1+ (1,0) [0|255] ""  Gateway_PQ35,Gateway_PQ46
 SG_ Data_Byte_5_31 : 56|8@1+ (1,0) [0|255] ""  Gateway_PQ35,Gateway_PQ46

BO_ 1762 mCDEF_TCU_SH: 8 Vector__XXX
 SG_ Module_ID_32 : 0|6@1+ (1,0) [0|63] ""  Gateway_PQ35,Gateway_PQ46,Standheizung
 SG_ Update_Indikator_32 : 6|2@1+ (1,0) [0|3] ""  Gateway_PQ35,Gateway_PQ46,Standheizung
 SG_ Funktions_ID_32 : 8|5@1+ (1,0) [0|31] ""  Gateway_PQ35,Gateway_PQ46,Standheizung
 SG_ OpCode_32 : 13|3@1+ (1,0) [0|7] ""  Gateway_PQ35,Gateway_PQ46,Standheizung
 SG_ Controller_ID_32 : 16|4@1+ (1,0) [0|15] ""  Gateway_PQ35,Gateway_PQ46,Standheizung
 SG_ Data_Byte_1_32 : 24|8@1+ (1,0) [0|255] ""  Gateway_PQ35,Gateway_PQ46,Standheizung
 SG_ Data_Byte_2_32 : 32|8@1+ (1,0) [0|255] ""  Gateway_PQ35,Gateway_PQ46,Standheizung
 SG_ Data_Byte_3_32 : 40|8@1+ (1,0) [0|255] ""  Gateway_PQ35,Gateway_PQ46,Standheizung
 SG_ Data_Byte_4_32 : 48|8@1+ (1,0) [0|255] ""  Gateway_PQ35,Gateway_PQ46,Standheizung
 SG_ Data_Byte_5_32 : 56|8@1+ (1,0) [0|255] ""  Gateway_PQ35,Gateway_PQ46,Standheizung

BO_ 993 mClima_1: 8 Gateway_PQ35
 SG_ CL1_Drehzahlanhebung : 0|1@1+ (1,0) [0|1] ""  Standheizung
 SG_ CL1_Zuheizer : 1|1@1+ (1,0) [0|1] ""  Standheizung
 SG_ CL1_HzgHeckscheibe : 2|1@1+ (1,0) [0|1] "" Vector__XXX
 SG_ CL1_HzgFrontscheibe : 3|1@1+ (1,0) [0|1] "" Vector__XXX
 SG_ CL1_Kompressor : 4|1@1+ (1,0) [0|1] "" Vector__XXX
 SG_ CL1_Heizung_aus : 5|1@1+ (1,0) [0|1] ""  Standheizung
 SG_ CL1_Kompressormoment_alt : 6|1@1+ (1,0) [0|1] "" Vector__XXX
 SG_ CL1_Kaeltemitteldruck_alt : 7|1@1+ (1,0) [0|1] "" Vector__XXX
 SG_ CL1_AussenTemp : 8|8@1+ (0.5,-50) [-50|77] "Unit_DegreCelsi"  Standheizung
 SG_ CL1_KaeltemittelDruck : 16|8@1+ (0.2,0) [0|50.8] "Unit_Bar" Vector__XXX
 SG_ CL1_Last_Kompressor : 24|8@1+ (0.25,0) [0|63.5] "Unit_NewtoMeter" Vector__XXX
 SG_ CL1_Geblaeselast : 32|8@1+ (0.4,0) [0|100] "Unit_PerCent" Vector__XXX
 SG_ CL1_Strg_Kluefter : 40|8@1+ (0.4,0) [0|100] "Unit_PerCent" Vector__XXX
 SG_ CL1_Temp_in_F : 48|1@1+ (1,0) [0|1] "" Vector__XXX
 SG_ CL1_AC_Schalter : 49|1@1+ (1,0) [0|1] "" Vector__XXX
 SG_ CL1_WAPU_Zuschaltung : 50|1@1+ (1,0) [0|1] "" Vector__XXX
 SG_ CL1_Restwaerme : 51|1@1+ (1,0) [0|1] ""  Standheizung
 SG_ CL1_PTC_Clima : 52|3@1+ (25,0) [0|100] "Unit_PerCent" Vector__XXX
 SG_ CL1_KD_Fehler : 55|1@1+ (1,0) [0|1] "" Vector__XXX
 SG_ KL_Thermomanagement : 56|2@1+ (1,0) [0|3] "" Vector__XXX

BO_TX_BU_ 1658 : Radio_Modul,RNS_300_NF,RNS_midline;
BO_TX_BU_ 1737 : Gateway_PQ35,Gateway_PQ46;
BO_TX_BU_ 1735 : Radio_Modul,RNS_300_NF,RNS_midline;
BO_TX_BU_ 1738 : Radio_Modul,RNS_300_NF,RNS_midline;
BO_TX_BU_ 1739 : Radio_Modul,RNS_300_NF,RNS_midline;
BO_TX_BU_ 1734 : Radio_Modul,RNS_300_NF,RNS_midline;
BO_TX_BU_ 1660 : Gateway_PQ35,Gateway_PQ46;
BO_TX_BU_ 1733 : Radio_Modul,RNS_300_NF;
BO_TX_BU_ 1644 : Radio_2DIN,Radio_Modul,RNS_300_NF,RNS_midline;
BO_TX_BU_ 1768 : Gateway_PQ35,Gateway_PQ46;
BO_TX_BU_ 1755 : Gateway_PQ35,Gateway_PQ46;
BO_TX_BU_ 1751 : Booster_AMP,Kompassmodul,MDI,Radio_2DIN,Radio_Modul,Rearview,RNS_300_NF,RNS_midline,Standheizung,TV_hybrid,UHV_High,UHV_NAR,UHV_Premium,UHV_UMTS;
BO_TX_BU_ 1657 : Gateway_PQ35,Gateway_PQ46;
BO_TX_BU_ 1580 : UHV_NAR,UHV_UMTS;
BO_TX_BU_ 1661 : Kompassmodul,RNS_300_NF,RNS_midline;
BO_TX_BU_ 1754 : Gateway_PQ35,Gateway_PQ46;
BO_TX_BU_ 1756 : Gateway_PQ35,Gateway_PQ46,Rearview;
BO_TX_BU_ 1746 : UHV_High,UHV_NAR,UHV_Premium,UHV_UMTS;
BO_TX_BU_ 1749 : UHV_High,UHV_NAR,UHV_Premium,UHV_UMTS;
BO_TX_BU_ 1595 : UHV_High,UHV_NAR,UHV_Premium,UHV_UMTS;
BO_TX_BU_ 1647 : UHV_High,UHV_NAR,UHV_Premium,UHV_UMTS;
BO_TX_BU_ 1903 : Gateway_PQ35,Gateway_PQ46;
BO_TX_BU_ 1792 : Gateway_PQ35,Gateway_PQ46;
BO_TX_BU_ 1907 : Gateway_PQ35,Gateway_PQ46;
BO_TX_BU_ 1902 : Gateway_PQ35,Gateway_PQ46;
BO_TX_BU_ 1900 : Gateway_PQ35,Gateway_PQ46;
BO_TX_BU_ 1816 : Gateway_PQ35,Gateway_PQ46;
BO_TX_BU_ 1899 : Gateway_PQ35,Gateway_PQ46;
BO_TX_BU_ 2005 : UHV_NAR,UHV_UMTS;
BO_TX_BU_ 1901 : Gateway_PQ35,Gateway_PQ46;
BO_TX_BU_ 337 : Gateway_PQ35,Gateway_PQ46;
BO_TX_BU_ 1429 : Gateway_PQ35,Gateway_PQ46;
BO_TX_BU_ 1624 : Gateway_PQ35,Gateway_PQ46;
BO_TX_BU_ 1461 : Gateway_PQ35,Gateway_PQ46;
BO_TX_BU_ 1393 : Gateway_PQ35,Gateway_PQ46;
BO_TX_BU_ 1397 : Gateway_PQ35,Gateway_PQ46;
BO_TX_BU_ 1136 : Gateway_PQ35,Gateway_PQ46;
BO_TX_BU_ 1712 : Gateway_PQ35,Gateway_PQ46;
BO_TX_BU_ 1696 : Gateway_PQ35,Gateway_PQ46;
BO_TX_BU_ 1713 : Gateway_PQ35,Gateway_PQ46;
BO_TX_BU_ 1697 : Gateway_PQ35,Gateway_PQ46;
BO_TX_BU_ 1782 : Gateway_PQ35,Gateway_PQ46;
BO_TX_BU_ 1714 : Gateway_PQ35,Gateway_PQ46,Standheizung;
BO_TX_BU_ 1698 : Gateway_PQ35,Gateway_PQ46,Standheizung;
BO_TX_BU_ 993 : Gateway_PQ35,Gateway_PQ46;

CM_ "Generated by BusNet PQ (Produktiv) 6.6.4  © 2008 Sulzer GmbH";
CM_ BU_ Booster_AMP "PQ35_46";
CM_ BU_ DSP_SKODA "PQ35_46";
CM_ BU_ Gateway_PQ35 "PQ35";
CM_ BU_ Gateway_PQ46 "PQ46";
CM_ BU_ GSM_Pager "PQ35_46";
CM_ BU_ Kompassmodul "PQ35_46";
CM_ BU_ MDI "PQ35_46";
CM_ BU_ Radio_2DIN "PQ35_46";
CM_ BU_ Radio_Modul "PQ35_46";
CM_ BU_ Radio_SKODA "PQ35_46";
CM_ BU_ Rearview "PQ35_46";
CM_ BU_ RNS_300_NF "PQ35_46";
CM_ BU_ RNS_MFD2 "PQ35_46";
CM_ BU_ RNS_midline "PQ35_46";
CM_ BU_ SDARS_Tuner "PQ35_46";
CM_ BU_ Sprachbedienung "PQ35_46";
CM_ BU_ Standheizung "PQ35_46";
CM_ BU_ Tastatur "PQ35_46";
CM_ BU_ Telematik_Basis "PQ35_46";
CM_ BU_ TV_hybrid "PQ35_46";
CM_ BU_ UHV_High "PQ35_46";
CM_ BU_ UHV_low "PQ35_46";
CM_ BU_ UHV_NAR "PQ35_46";
CM_ BU_ UHV_Premium "PQ35_46";
CM_ BU_ UHV_UMTS "PQ35_46";
CM_ SG_ 1952 ASR0_Status_StateID "ASR0_Status_StateID should reflect the actual state of the ASR-System";
CM_ SG_ 1952 ASR0_Status_RecogOpen "ASR0_Status_RecogOpen = 0 --> The Recognizer is not opened, i. e. no utterance will be recorded or recognized
ASR0_Status_RecogOpen = 1 --> The Recognizer is opened, i. e. the user should now speak an utterance";
CM_ SG_ 1952 ASR0_Status_Activ "ASR0_Status_Activ = 0 --> ASR-System is NOT activ at all
ASR0_Status_Activ = 1 --> ASR-System is activ, either playing a feedback, recognizing or processing";
CM_ SG_ 1953 ASR1_Command_ID "Unique Command-ID to map static utterances for recognition.
This Command-ID should be State-Dependent";
CM_ SG_ 1953 ASR1_Confidence "Recognized Confidence Value
0 -10000 = 0% - 100%
This value is set for the current Command-ID / String-ID";
CM_ SG_ 1953 ASR1_Cnt_SubCmd "Counter for current Sub-Command
# = current Sub-Command starting with 0";
CM_ SG_ 1953 ASR1_Cnt_NBest "Counter for current N-Best-List entries.
#==0 --> decided command
# > 0 --> Counter = N of the '-N-Best-List'";
CM_ SG_ 1953 ASR1_Cnt_Multiplex_String "ASR1_Cnt_Multiplex_String = 0 --> Length of String-ID < 32 Byte [UTF-8 coded]
ASR1_Cnt_Multiplex_String = 1 --> Length of String-ID > 32 Byte [UTF-8 coded],String divided into partitions of 32 Byte
Only valid, if ASR1_Is_Command_ID == 0 ";
CM_ SG_ 1953 ASR1_Is_String_TimeMultiplexed "Valid if ASR1_Command_ID == 0
ASR1_Is_String_TimeMultiplexed == 0 --> If String-ID < 32 Byte
ASR1_Is_String_TimeMultiplexed == 1 --> If String-ID > 32 Byte, String-ID should be devided into parts of 32 Bytes";
CM_ SG_ 1953 ASR1_Is_Multiplex_Last_Msg "Independet of  (ASR1_Cnt_Multiplex_String) -Value  (ASR1_Is_Multiplex_Last_Msg) should indicate that no further characters will follow.
ASR1_Is_Multiplex_Last_Msg ==1 --> UTF-8 Coding can now be done";
CM_ SG_ 1953 ASR1_Is_NBest_Last_Msg "ASR1_Is_NBest_Last_Msg == 0 --> More entries for the N-Best-List will follow
ASR1_Is_NBest_Last_Msg == 1 --> Complete N-Best-List received";
CM_ SG_ 1953 ASR1_Is_Command_ID "ASR1_Is_Command_ID == 0 --> String-ID will be used
ASR1_Is_Command_ID == 1 --> Command-ID will be used, CAN-IDs 0x7A2- 0x7A5 will not be set";
CM_ SG_ 1958 ASR6_Param_SetValue "Value to be set into the ASR-System";
CM_ SG_ 1958 ASR6_Param_ID "Param_ID depending on current project
A mapping table should be available";
CM_ SG_ 1958 ASR6_Is_Read_Request "ASR6_Is_Read_Request == 0 --> Request to write the Param_ID with Param_SetValue
ASR6_Is_Read_Request == 1 --> Request to get the Param_ID (Param_SetValue will be ignored)";
CM_ SG_ 1959 ASR7_Param_GetValue "Current value for requested Param_ID";
CM_ SG_ 1959 ASR7_Param_ID "Param_ID depending on current project
A mapping table should be available";
CM_ SG_ 1959 ASR7_Write_Success "ASR7_Write_Success == 0; Error for writing the requested value for Param_ID; not valid if ASR7_Is_Read_Feedback==1
ASR7_Write_Success == 1; Writing was successfully done (Acknowledge)";
CM_ SG_ 1959 ASR7_Is_Read_Feedback "ASR7_Is_Read_Feedback == 0 --> Request was to write a value; ASR7_Param_GetValue not valid
ASR7_Is_Read_Feedback == 1 --> Request was to read a value; ASR7_Param_GetValue should be set (ASR7_Write_Success can be ignored)";
CM_ SG_ 1658 BAP_Data_Anzeige_02 "ASG: RNS, Radio => FSG: OPS, HYB";
CM_ SG_ 1753 BAP_Data_Anzeige_RV "FSG: Rearview => ASG: RNS, Radio";
CM_ SG_ 1737 BAP_Data_ASG_02 "ASG: KBI => FSG: SHZ, Charisma";
CM_ SG_ 1735 BAP_Data_ASG_03 "ASG: RNS, Radio => FSG: Tel, TV, DSP";
CM_ SG_ 1738 BAP_Data_ASG_04 "ASG: RNS, Radio => FSG: RSE, Rearview";
CM_ SG_ 1739 BAP_Data_ASG_05 "ASG: RNS, Radio => FSG: Clima";
CM_ SG_ 1734 BAP_Data_ASG_06 "ASG: RNS, Radio => FSG: Tel., MDI";
CM_ SG_ 1660 BAP_Data_ASG_07 "ASG: KBI => FSG: Telefon, Navi, Audio";
CM_ SG_ 1733 BAP_Data_ASG_08 "ASG: RNS, Radio => FSG: DSP";
CM_ SG_ 1774 BAP_Data_ASG_09 "ASG: RMC, RNS => FSG: KBI";
CM_ SG_ 1644 BAP_Data_AUDIO "FSG: Radio, Navi => ASG: KBI";
CM_ SG_ 1768 BAP_Data_BC "FSG: KBI => ASG: RMC, RNS";
CM_ SG_ 1755 BAP_Data_Clima "FSG: Clima => ASG: RNS, Radio";
CM_ SG_ 1750 BAP_Data_Debug_Cmd "BAP Debug Cmd";
CM_ SG_ 1751 BAP_Debug_Data "BAP Debug Data";
CM_ SG_ 1752 BAP_Data_DSP "FSG: AMP => ASG: RNS, Radio";
CM_ SG_ 1596 BAP_Data_MDI "FSG: MDI => ASG: RNS, Radio";
CM_ SG_ 1580 BAP_Data_MDI_02 "FSG: UHV => ASG: RNS, Radio";
CM_ SG_ 1661 BAP_Data_NAVI "FSG: RNS, Kompass => ASG: KBI";
CM_ SG_ 1754 BAP_Data_OPS "FSG: OPS => ASG: RNS, Radio, KBI";
CM_ SG_ 1756 BAP_Data_Rearview "FSG: Rearview => ASG: RNS, Radio";
CM_ SG_ 1646 BAP_Data_SHZ "FSG: Standheizung => ASG: KBI";
CM_ SG_ 1746 BAP_Data_Telefon_1 "FSG: Tel. => ASG: Radio, Navi";
CM_ SG_ 1749 BAP_Data_Telefon_2 "FSG: Tel. => ASG: Radio, Navi";
CM_ SG_ 1595 BAP_Data_Telefon_3 "FSG: Tel. => ASG: Radio, Navi";
CM_ SG_ 1647 BAP_Data_Telefon_4 "FSG: Tel. => ASG: KBI";
CM_ SG_ 1747 BAP_Data_TV_Tuner "FSG: TV-Tuner => ASG: RNS";
CM_ SG_ 1903 ISO_AMP_Req_Data "ISO Request Kanal";
CM_ SG_ 2009 ISO_AMP_Resp_Data "ISO Response Kanal";
CM_ SG_ 1792 ISO_ALL_01_Req_Data "ISO Request Kanal";
CM_ SG_ 1907 ISO_Info_El_Req_Data "ISO Request Kanal";
CM_ SG_ 2013 ISO_Info_El_Resp_Data "ISO Response Kanal";
CM_ SG_ 1902 ISO_MDI_Req_Data "ISO Request Kanal";
CM_ SG_ 2008 ISO_MDI_Resp_Data "ISO Response Kanal";
CM_ SG_ 1900 ISO_Navi_Req_Data "ISO Request Kanal";
CM_ SG_ 2006 ISO_Navi_Resp_Data "ISO Response Kanal";
CM_ SG_ 1816 ISO_Radio_Req_Data "ISO Request Kanal";
CM_ SG_ 1922 ISO_Radio_Resp_Data "ISO Response Kanal";
CM_ SG_ 1899 ISO_Telefon_Req_Data "ISO Request Kanal";
CM_ SG_ 2005 ISO_Telefon_Resp_Data "ISO Response Kanal";
CM_ SG_ 1901 ISO_TV_Tuner_Req_Data "ISO Request Kanal";
CM_ SG_ 2007 ISO_TV_Tuner_Resp_Data "ISO Response Kanal";
CM_ BO_ 337 "CAN-Komfort CAN-Infotainment";
CM_ SG_ 337 AB1_FrontCrash "Bit wird bei Überschreitung der Gurtstraffer, US-Schwelle und RDW-Schwelle gesetzt
Front-Crash";
CM_ SG_ 337 AB1_HeckCrash "wird für neu anlaufende Projekte umgesetzt: AB8.4, Audi8/VW8
Heck-Crash";
CM_ SG_ 337 AB1_Crash_FT "z. Zt. Nur in Verbindung mit Crash-Intensität 100b (Kraftstoffpumpenabsch.) verwendet
Seiten-Crash Fahrer";
CM_ SG_ 337 AB1_Crash_BT "z. Zt. Nur in Verbindung mit Crash-Intensität 100b (Kraftstoffpumpenabsch.) verwendet
Seiten-Crash Beifahrer";
CM_ SG_ 337 AB1_Rollover "wird im B6 Cabrio und New Beetle Cabrio, Touareg GP und VW465 bedient
Rollover";
CM_ SG_ 337 AB1_CrashStaerke "Die folgende Auswertung ist bei VW geplant: ; >= 001: ZV auf, Innenlicht u. Warnblinker ein ; >= 010: Notruf ausgelöst ; >= 100: Kraftstoffabschaltung (mit RDW-Schwelle aktiviert, d.h.Bit 7 = 1); ; Information bleibt bei jeder Schwellwert-überschreitung f";
CM_ SG_ 337 AB1_AirbagLampe_ein "Sicherheitswarnlampe im Kombi wird vom Airbag-SG angesteuert; Zustand der Lampe wird auf dem CAN-Bus ausgegeben (auch Blinkinformation)
Airbag-Lampe";
CM_ SG_ 337 AB1_Airbag_deaktiviert "Airbag oder Gurtstraffer wurden per Anpassung deaktiviert: Aktualisierung erst nach Selbsttest
Airbag deaktiviert";
CM_ SG_ 337 AB1_Beif_Airbag_deaktiviert "Als Option vorgehalten, Beifahrerairbag wurden per Schlüsselschalter oder Insassenerkennung deaktiviert
Beifahrerairbag deaktiviert";
CM_ SG_ 337 AB1_Systemfehler "Warnlampe (Byte 2, Bit 0) wird dauernd angeschaltet
Airbag-Systemfehler";
CM_ SG_ 337 AB1_Fa_Gurt "über Schalter im Gurtschloss
Gurtschlossabfrage Fahrer";
CM_ SG_ 337 AB1_Bf_Gurt "über Schalter im Gurtschloss
Gurtschlossabfrage Beifahrer";
CM_ SG_ 337 AB1_Diagnose "Bei Diagnose über UDS nicht mehr bedient
Airbag in Diagnose";
CM_ SG_ 337 AB1_Stellglied "zur Unterdrückung einer Notrufauslösung
Airbag im Stellgliedtest";
CM_ SG_ 337 AB1_BF_Anschnall "im Kombi wird eine Gurtwarnung für den Beifahrer ausgelöst (z. B. Beifahrersitz belegt, Gurt nicht angelegt)
Gurtwarnung Beifahrer";
CM_ SG_ 337 AB1_KD_Fehler "Bei gesetztem Bit ist mindestens ein Kundendienstfehler eingetragen";
CM_ SG_ 337 AB1_MessageZaehler "überlaufender Botschaftszähler zur Lebenderkennung";
CM_ SG_ 337 AB1_Pruefsumme "Prüfsumme, Definition im CAN Lastenheft";
CM_ SG_ 1429 AG1_BL_def "1 = Anhaenger Bremslicht defekt
Anhaenger Bremslicht defekt (s. Gateway_Komfort_1)";
CM_ SG_ 1429 AG1_NSL_def "1 = Anhaenger Nebelschlusslicht defekt";
CM_ SG_ 1429 AG1_RFL_def "1 = Rueckfahrlicht Anhaenger defekt";
CM_ SG_ 1429 AG1_KD_Fehler "1 = mindestens ein Kundendienstfehler ist eingetragen";
CM_ SG_ 1429 AG1_Blk_ein "1 = Anhaenger Blinker ein, Blinkmodus";
CM_ SG_ 1429 AG1_Kl_54_def "Vorhalt, z. Zt. Immer 0 senden
Anhaenger Klemme 54 defekt";
CM_ SG_ 1429 AG1_ANH_Alarm "Vorhalt, z.Zt. Immer 0 senden
Anhaengerueberwachung Alarm ausgeloest";
CM_ SG_ 1429 AG1_ANH_Erk "1 = Anhaenger erkannt
Anhaenger erkannt (Gateway Komfort 1)";
CM_ SG_ 1429 AG1_Typ "0 = AAG wie B6 (D1, ...), nicht schwenkbar
1 = Anhaengevorrichtung elektrisch schwenkbar
2 = n.n.
3 = n.n.
Typ des Anhaengeranschlussgeraetes";
CM_ SG_ 1429 AG1_Blinker_r_def "1 = Anhaengerblinklicht rechts defekt";
CM_ SG_ 1429 AG1_Licht_r_def "1 = Anhaengerschlusslicht links defekt";
CM_ SG_ 1429 AG1_NBA_ready "n.n.";
CM_ SG_ 1429 AG1_Blinker_l_def "1 = Anhaengerblinklicht links defekt";
CM_ SG_ 1429 AG1_Licht_l_def "1 = Anhaengerschlusslicht links defekt";
CM_ SG_ 1429 AG1_AVS_Warnung "0 = AVS (Anhaengevorrichtung schwenkbar) i.O.
1 = AVS nicht i.O.
2 = AVS nicht i.O. sofort Anhalten und Problem beheben
3 = Zustand nicht ermittelbar, unbekannt
Warnmeldungen vor nicht nutzbarem Zustand der Schwenkbaren Anhaengervorrichtung!
Das drit";
CM_ SG_ 1429 AG1_AVS_Status "AVS-Status:
0 = Eingefahren
1 = Ausgefahren
2 = Ausfahren
3 = Einfahren
4 = Ausfahren Ueberdrueckt bzw. Manuell
5 = Einfahren Ueberdrueckt bzw. Manuell
6 = Keine Endstellung aber Stillstand und Initialisiert
7 = Keine Endstellung aber Stillstand u";
CM_ SG_ 1624 BEM_02_Abschaltstufen "Abschaltstufen des Ruhestrommanagements (Initialisierungswert aus EEprom)
0 = Stufe 0 (keine Einschraenkungen)
1 = Stufe 1
2 = Stufe 2
3 = Stufe 3";
CM_ SG_ 1624 BEM_STH_Zielzeit "Maximal mögliche Zeit für den Standheizungsbetrieb, um die Startfähigkeit nicht zu gefährden";
CM_ SG_ 1624 BEM_MMI_Vorwarnung "Anzeige Vorwarnung MMI-Abschaltung (Initialisierungswert aus EEprom)";
CM_ SG_ 1624 BEM_HL_Kontingentierung "Leistungskontingente für Heizsysteme";
CM_ SG_ 1624 BEM_Generatordiagnose "Ansteuerung Generatorwarnleuchte im Kombi
0 = keine Anzeige
1 = Ladekontrollanzeige ein (Vorhalt)
2 = rotes Batteriesymbol und Text (Generator defekt)
3 = nicht belegt";
CM_ SG_ 1624 BEM_Red_Innengeblaese "Reduzierung Innengebläse
0 = keine Reduzierung
1 = Reduzierung Stufe 1
2 = Reduzierung Stufe 2
3 = Reduzierung Stufe 2 und Abschaltung Kompressor";
CM_ SG_ 1624 BEM_STH_Einschaltverbot "Einschränkung Standheizung/-lüftung durch BEM: Setzt der BEM das Bit, dann darf die Standheizung nicht mehr einschalten
(Die Standheizung muss aber nicht abschalten, sondern darf weiterbrennen);(Initialisierungswert aus EEprom)
0 = volle Verfuegbarkeit ";
CM_ SG_ 1624 BEM_HL_Regelung_Status "Status Regelung Heizleistung
0 = HL Regelung inaktiv (vor und waehrend Motorstart)
1 = HL Regelung Stufe 1
2 = HL Regelung Stufe 2
3 = HL Regelung Stufe 3
4 = Verbrauchernotabschaltung (VNA)
7 = Default";
CM_ SG_ 1624 BEM_Ladezustand "Anzeige des SOC in Balkendarstellung";
CM_ SG_ 1624 BEM_Batteriediagnose "Anzeige von Textwarnungen
0 = keine Anzeige
1 = nicht belegt
2 = nicht belegt
3 = gelbes Batteriesymbol und Text";
CM_ SG_ 1624 BEM_DFM "Generatorauslastungsgrad, vom Generator über LIN an das Gateway gesandt. Das Motorsteuergerät regelt auf dieses Signal die PTC, das Energiemanagement im BSG/BCM kalkuliert die Bordnetzauslastung";
CM_ SG_ 1624 BEM_REK_aktiv "Rekuperationsfreigabe vom Energiemanagement
0x0 = keine Rekuperationsfreigabe
0x1 = Rekuperationsfreigabe";
CM_ SG_ 1624 BEM_EMLIN_ungueltig "Energie-Lin-Signale sind ungültig vom Slave Batteriedatenmodul oder Generator
0 = Signale gültig
1 = Signale ungültig";
CM_ SG_ 1624 BEM_Batt_Ab "Batterieverbindungskontrolle:
0 = Batterie am Bordnetz
1 = Batterie ab erkannt";
CM_ SG_ 1624 BEM_UBDM "Batteriespannung, gemessen vom Batteriedatenmodul";
CM_ SG_ 1624 BEM_UGenSoll "Sollspannungsvorgabe an den Generator, beinhaltet temperaturoptimierte Batterieladung und Rekuperation";
CM_ SG_ 1461 B10_Checksumme "Prüfsumme, Definition im CAN-Lastenheft";
CM_ SG_ 1461 B10_Zaehler "Überlaufender Botschaftszähler, zur Lebenderkennung";
CM_ SG_ 1461 B10_QB_Wegimp_VL "Definition nach CAN-Lastenheft
Qualifizierungsbit Wegimpulse VL";
CM_ SG_ 1461 B10_QB_Wegimp_VR "Definition nach CAN-Lastenheft
Qualifizierungsbit Wegimpulse VR";
CM_ SG_ 1461 B10_QB_Wegimp_HL "Definition nach CAN-Lastenheft
Qualifizierungsbit Wegimpulse HL";
CM_ SG_ 1461 B10_QB_Wegimp_HR "Definition nach CAN-Lastenheft
Qualifizierungsbit Wegimpulse HR";
CM_ SG_ 1461 B10_Wegimp_VL "Anzahl der Wegimpulse Vorderrad links (steigende und fallende Flanke)
Zähler läuft grundsätzlich vorwärts, auch bei Rückwärtsfahrt";
CM_ SG_ 1461 B10_Wegimp_VR "Anzahl der Wegimpulse Vorderrad rechts (steigende und fallende Flanke)
Zähler läuft grundsätzlich vorwärts, auch bei Rückwärtsfahrt";
CM_ SG_ 1461 B10_Wegimp_HL "Anzahl der Wegimpulse Vorderrad links (steigende und fallende Flanke)
Zähler läuft grundsätzlich vorwärts, auch bei Rückwärtsfahrt";
CM_ SG_ 1461 B10_Wegimp_HR "Anzahl der Wegimpulse Vorderrad links (steigende und fallende Flanke)
Zähler läuft grundsätzlich vorwärts, auch bei Rückwärtsfahrt";
CM_ SG_ 1461 B10_QB_Fahrtr_VL "Definition nach CAN-Lastenheft
Qualifizierungsbit Fahrtrichtung VL";
CM_ SG_ 1461 B10_QB_Fahrtr_VR "Definition nach CAN-Lastenheft
Qualifizierungsbit Fahrtrichtung VR";
CM_ SG_ 1461 B10_QB_Fahrtr_HL "Definition nach CAN-Lastenheft
Qualifizierungsbit Fahrtrichtung HL";
CM_ SG_ 1461 B10_QB_Fahrtr_HR "Definition nach CAN-Lastenheft
Qualifizierungsbit Fahrtrichtung HR";
CM_ SG_ 1461 B10_Fahrtr_VL "Fahrtrichtungserkennung Vorderrad links";
CM_ SG_ 1461 B10_Fahrtr_VR "Fahrtrichtungserkennung Vorderrad rechts";
CM_ SG_ 1461 B10_Fahrtr_HL "Fahrtrichtungserkennung Hinterrad links";
CM_ SG_ 1461 B10_Fahrtr_HR "Fahrtrichtungserkennung Hinterrad rechts";
CM_ SG_ 1393 BS2_U_BATT "FF = Fehler
Bordnetz_Batterie_Spannung (s. BSG_Last)";
CM_ SG_ 1393 BS2_Heckscheibe_aus "1 = Abschalten der Heckscheibenheizung ist gefordert
Heizbare_Heckscheibe abschalten (s. BSG_Last)";
CM_ SG_ 1393 BS2_Frontscheibe_aus "1 = Abschalten der Frontscheibenheizung ist gefordert
Heizbare_Frontscheibe abschalten (s. BSG_Last)";
CM_ SG_ 1393 BS2_Aussenspiegel_aus "1 = Abschalten der Aussenspiegelheizung ist gefordert
Heizbare_Aussenspiegel abschalten (s. BSG_Last)";
CM_ SG_ 1393 BS2_Sitzheizung_aus "1 = Abschalten der Sitzheizung ist gefordert
Heizbare_Sitze abschalten (s. BSG_Last)";
CM_ SG_ 1393 BS2_aus_Lenkradheizung "1 = Abschalten der Lenkradheizung ist gefordert
Lenkradheizung abschalten (s. BSG_Last)";
CM_ SG_ 1393 BS2_aus_Wischwasserhzg "1 = Abschalten der Wischwasserheizung ist gefordert
Wischwasserheizung abschalten (s. BSG_Last)";
CM_ SG_ 1393 BS2_aus_Sitzlueftung "1 = Abschalten der Sitzbelueftung ist gefordert";
CM_ SG_ 1393 BS2_Klimaanlage_aus "1 = Reduzierung der Klimaleistung ist gefordert
Klimaanlage abschalt. / reduzieren (s. BSG_Last)";
CM_ SG_ 1393 BS2_U_Start_BATT "FF = Fehler
Starter_Batterie_Spannung";
CM_ SG_ 1393 BS2_Lastman_aktiv "1 = Lastmanagement ist aktiv";
CM_ SG_ 1393 BS2_Verbr_ab_aktiv "1 = Forderung, dass mindestens ein Verbraucher abgeschaltet werden soll";
CM_ SG_ 1393 BS2_Notstart "1 = Notstart wird durchgefuehrt";
CM_ SG_ 1393 BS2_aus_Sitzhzg_H "1 = Abschalten der Sitzheizung an den hinteren Sitzen gefordert";
CM_ SG_ 1393 BS2_aus_Steckdosen "1 = Abschalten der Steckdosen ist gefordert";
CM_ SG_ 1393 BS2_aus_Zusatz_Verbr "1 = Abschalten eines Zusatzverbrauchers, z.B. Regenschirmtrockner, Kuehlbox, ...";
CM_ SG_ 1393 BS2_aus_Infotainment "1 = Abschalten eines reservierten Verbrauchers (Infotainment) ist gefordert
Infotainmentfunktionalitaet abschalten/reduzieren";
CM_ SG_ 1393 BS2_Wake_Up_ACAN "0 = kein Wake-Up (z.B. KL15-Normalbetrieb)
1 = Anforderung zum Wecken des Antriebs-CAN
Das BSG lernt anhand von MO7_Mot_weckfaehig, ob es das Bit setzen muss.
Wake-Up des Antriebs-CAN";
CM_ SG_ 1393 BS2_aus_PTC_Clima "Abschalten der Zusatzheizelemente PTC der Climaanlage
0 = Kein Abschalten
1= Reduzierung auf 75%
2 = Reduzierung auf 50%
3 = Reduzierung auf 25%
4 = Reduzierung auf 0%";
CM_ SG_ 1393 BS2_KlimaLeistRed "0: keine Leistungsreduzierung
1: Leistungsreduzierung Stufe 1
2: Leistungsreduzierung Stufe 2
3: Leistungsreduzierung Stufe 3
Abschaltbefehl ueber BS2_Klimaanlage_aus.
Leistungsreduzierung Klimaanlage";
CM_ SG_ 1393 BS2_red_Heckscheibe "1 = Leistungsreduzierung der Heckscheibe gefordert, Abschalten siehe BS2_Heckscheibe_aus";
CM_ SG_ 1393 BS2_aus_Ablage_Wischer "Wischerablagenheizung ausschalten";
CM_ SG_ 1393 BS2_aus_Innen_Bel "1 = Abschaltung bzw. Leistungsreduzierung der Innenraum- und Umfeldbeleuchtung";
CM_ SG_ 1393 BS2_Warn_Steckdosen "1 = Steckdosen werden in Kuerze abgeschaltet";
CM_ SG_ 1393 BS2_Warn_Infotainment "1 = Infotainmentteilnehmer werden in Kuerze abgeschaltet";
CM_ SG_ 1393 BS2_Warn_Zusatz "1 = Zusatzverbraucher werden in Kuerze abgeschaltet";
CM_ SG_ 1393 BS2_Weckursache_ACAN "00 = kein_EKP_Vorlauf
01 = reserviert
10 = Weckursache Standheizung
11 = Weckursache Türkontakt
abhaengig von der genannten Weckursache wird eine Kraftstoffpumpen-Vorfoerderung angesteuert.
Wake-Up-Anforderung durch das BSG";
CM_ SG_ 1393 BS2_VB_2_Battarie "Dieses Bit wird am Bandende im BSG codiert und zeigt an, ob eine 2. Batterie (z.B. fuer eine Standheizung) im Fahrzeug verbaut ist.";
CM_ SG_ 1393 BS2_Zust_Start_Ltg "1 = Starterleitung Masseschluss, KL 50 sperren
0 = Starterleitung i.O.
Zustand Starterleitung";
CM_ SG_ 1393 BS2_Mess_Start_Ltg "1 = Prüfung der Starterleitung laeuft, KL 50 sperren
0 = Bit Starterleitung beachten
Messung Starterleitung";
CM_ SG_ 1397 BS3_Klemme_S "1 = S-Kontakt geschlossen, Schluessel steckt
S-Kontakt (Schluessel steckt)";
CM_ SG_ 1397 BS3_Klemme_15 "1 = Klemme 15 Innenraum ist eingeschaltet";
CM_ SG_ 1397 BS3_Klemme_X "1 = Klemme X aktiv
Klemme X öffnet beim Motorstart und ist invers zu Klemme 50.
Bei Fahrzeugen mit Start/Stop-Systemen wird die Klemme X nur beim Erststart ausgeschaltet.";
CM_ SG_ 1397 BS3_Klemme_50 "1 = Klemme 50 ist eingeschaltet
Klemme 50 geschaltet (Starten)";
CM_ SG_ 1397 BS3_Klemme_P "1 = Klemme P ein (Parklicht)";
CM_ SG_ 1397 BS3_2_Drehzahl "1 = Anforderung der Drehzahlanhebung 2 Stufe
Drehzahlanhebung 2. Stufe (s. BSG_Last)";
CM_ SG_ 1397 BS3_Klemme_15_Motorraum "1 = Klemme 15 Motorraum ist eingeschaltet (Klemme 14)";
CM_ SG_ 1397 BS3_Ladekontrollampe "1 = mangelnde Batterieladung
Ladekontrollampe(Klemme L)";
CM_ SG_ 1397 BS3_Drehzahlanhebung "1 = Anforderung der Drehzahlanhebung (bei nur einer Stufe) oder Anhebung auf 1. Stufe (s. Antrieb BSG_Last)";
CM_ SG_ 1397 BS3_Bordnetzbatt "Zeigt den Zustand der Bordnetzbatterie an (00=i.O., 01=kritisch, 10=entladen, 11=Fehler)";
CM_ SG_ 1397 BS3_Starterbatt "Zeigt den Zustand der Starterbatterie an (00=i.O., 01=kritisch, 10=entladen, 11=Fehler)";
CM_ SG_ 1397 BS3_KD_Fehler "1 = mindestens ein Fehler ist im Kundendienstfehlerspeicher eingetragen";
CM_ SG_ 1397 BS3_LWR_Fehler "1 = Fehler in der Leuchtweitenregulierung
0 = i.O.";
CM_ SG_ 1397 BS3_Haubenkontakt "1 = Haube geoeffnet
0 = Haube geschlossen";
CM_ SG_ 1397 BS3_Coming_Home "1 = Coming Home Funktion aktiviert";
CM_ SG_ 1397 BS3_Leaving_Home "1 = Leaving Home Funktion aktiviert";
CM_ SG_ 1397 BS3_K_Luefter_ein "1 = Kuehlerluefer einschalten zur Glaettung der Bordnetzspannung bei defekter Batterie
Kuehlerluefter einschalten (s. BSG_Last)";
CM_ SG_ 1397 BS3_Ab_Batterie "1 = Batterie ab erkannt
0 = Batterie am Bordnetz
Batterie ab Erkennung";
CM_ SG_ 1397 BS3_VP_Taste "1 = Valet Parking Taste betaetigt, Bewertung erfolgt im Empfaenger";
CM_ SG_ 1397 BS3_Verglasung_zu "Befehl zum Verschliessen der Verglasung im Fenster, z.B. bei erkanntem Regen und offenen Fenster/Scheibedach";
CM_ SG_ 1397 BS3_PDC_Taster "1 = Taster betaetigt, Bewertung Ein/Aus erfolgt in der Einparkhilfe";
CM_ SG_ 1397 BS3_IRUE_Taster "1 = Taste IRUE gedrueckt; Bewertung ein/aus erfolgt durch ZKE";
CM_ SG_ 1397 BS3_VB_Coming_Home "1 = ComingHome Funktion im SG vorhanden";
CM_ SG_ 1397 BS3_VB_Tagesfahrlicht "1 = Tagesfahrlicht im SG vorhanden";
CM_ SG_ 1397 BS3_VB_Fussraumleuchten "1 = Dimmung Fussraumleuchten implementiert";
CM_ SG_ 1397 BS3_LED_Heckscheibe "1 = Heizbare Heckscheibe angesteuert";
CM_ SG_ 1397 BS3_LED_Frontscheibe "1 = Heizbare Frontscheibe angesteuert";
CM_ SG_ 1397 BS3_LED_Sitze "1 = Heizbare Sitze angesteuert";
CM_ SG_ 1397 BS3_LED_Aussenspiegel "1 = Heizbare Aussenspiegel angesteuert";
CM_ SG_ 1397 BS3_Starterlaubnis "Bit wird gesetzt, wenn der Start vom Bordnetz-SG bei folgenden Begebenheiten erlaubt wird:
- PN-verriegelt, - Interlock (Kupplung bei Handschalter-Fzg.) betaetigt (Kupplungschalter tief)
Als Reaktion auf deises Bit zeigt das Kessy Texte im Kombi an.
St";
CM_ SG_ 1136 BSK_Blk_links "1 = Kontrollampe Blinker links ein
0 = Kontrollampe Blinker links aus
Ansteuerung Blinkerkontrollampe links";
CM_ SG_ 1136 BSK_Blk_rechts "1 = Kontrollampe Blinker rechts ein
0 = Kontrollampe Blinker rechts aus
Ansteuerung Blinkerkontrollampe rechts";
CM_ SG_ 1136 BSK_Anhaenger "1 = Anhaengerbetrieb
dynamisch mit Blinken ein / aus (Zusatzinfo)
Anhaengerblinklampe ein";
CM_ SG_ 1136 BSK_Warnblinker "1 = solange Warnblinken aktiviert ist
0 = kein Warnblinken aktiv
Statische Anzeige Warnblinklicht ist eingeschaltet";
CM_ SG_ 1136 BSK_DWA_Akku "Kontrollampe DWA-Akku leer";
CM_ SG_ 1136 BSK_Rueckfahrlicht "1 = Rueckfahrlicht ein";
CM_ SG_ 1136 BSK_Sammelfehler_AKI "1 = Kundendienstfehlereintrag in mind. einem SG am Antriebs-, Kombi-, Komfort- oder Infotainment-CAN
0 = kein Kundendienstfehlereintrag in einem SG am Antriebs-, Kombi-, Komfort- oder Infotainment-CAN
Sammelfehlermeldung";
CM_ SG_ 1136 BSK_Ladekontrollampe "1 = mangelnde Batterieladung
Ladekontrollampe(Klemme L)";
CM_ SG_ 1136 BSK_FT_geoeffnet "Status der Drehfalle Fahrertuer";
CM_ SG_ 1136 BSK_BT_geoeffnet "Status der Drehfalle Beifahrertuer";
CM_ SG_ 1136 BSK_HL_geoeffnet "Status der Drehfalle Tuer hinten links";
CM_ SG_ 1136 BSK_HR_geoeffnet "Status der Drehfalle Tuer hinten rechts";
CM_ SG_ 1136 BSK_MH_geoeffnet "1 = Haube geoeffnet
0 = Haube geschlossen";
CM_ SG_ 1136 BSK_HD_Hauptraste "Status der Heckdeckel-Hauptraste";
CM_ SG_ 1136 BSK_HD_Vorraste "Status der Heckdeckel-Vorraste";
CM_ SG_ 1136 BSK_Unterspannung "Unterspannung, Signale nicht mehr alle o.k.";
CM_ SG_ 1136 BSK_Display "7F = Fehlerwert, kein Ersatzwert; (100 % entspricht maximaler Beleuchtungsstaerke)
Displaydimmung; Tastverhaeltnis";
CM_ SG_ 1136 BSK_Display_def "1 = Fehler, bzw. nicht verfuegbar
Klemme 58d n.i.O";
CM_ SG_ 1136 BSK_Klemme_58t "7F = Fehlerwert
Vor- & nachlaufende Suchbeleuchtung Timergesteuert";
CM_ SG_ 1136 BSK_Klemme_58t_def "1 = Fehler, bzw. nicht verfuegbar
Defekt-Bit für die vor- & nachlaufende Suchbeleuchtung Timergesteuert";
CM_ SG_ 1136 BSK_Interlock "Lampe mit der die Aufforderung an den Fahrer weitergegeben wird, dass dieser zum Start die Kupplung treten soll.
Interlock Lampe";
CM_ SG_ 1136 BSK_Buzzer "In Fahrzeugen mit separaten Tagfahrleuchten kann durch eine Bedienfolge von Blinker links (deaktivieren) / Blinker rechts (aktivieren), Lichthupe ein und Kl.15 ein das Tagfahrlicht aktiviert oder deaktiviert werden. Als Quittierung für diese Aktivierung/D";
CM_ SG_ 1136 BSK_Ruecks_HL_verriegelt "Statusmeldung, 0 = Lehne verriegelt; 1 = Lehne nicht verriegelt
Status Verriegelungszustand Ruecksitzlehne links";
CM_ SG_ 1136 BSK_Ruecks_HR_verriegelt "Statusmeldung, 0 = Lehne verriegelt; 1 = Lehne nicht verriegelt
Status Verriegelungszustand Ruecksitzlehne rechts";
CM_ SG_ 1136 BSK_Def_Lampe "1 = Ausfall mindestens einer Gluehlampe (Fehlertext im Kombi durch DDP)
Ausfall einer Gluehlampe erkannt (Anzeige im Kombi)";
CM_ SG_ 1136 BSK_NSL_LED_Pfad "0 = NSL-Kontrollampe wird ueber Draht angesteuert
1 = NSL-Kontrollampe im Kombi wird ueber CAN angesteuert
Signalpfad Kontrolllampe Nebelschlusslicht";
CM_ SG_ 1136 BSK_AFL_defekt "0 = Automatisches Fahrlicht (AFL) i.o.
1 = Fehler im Automatischen Fahrlicht";
CM_ SG_ 1136 BSK_BSG_defekt "1 = Fehler im BSG für eine sicherheitsrelevante Funktion erkannt
0 = alle sicherheitsrelevanten Funktionen im BSG o.K.
Vorhalt fuer eine Anzeige im Kombi";
CM_ SG_ 1136 BSK_Standlicht "1 = Parklicht links eingeshaltet (BCM_PQ25: Schalterinformation)
Vorsicht Sleep-Mode!
Kl58, Standlicht ein";
CM_ SG_ 1136 BSK_Parklicht_links "1 = Parklicht links eingeschaltet (BCM_PQ25: Schalterinformation)
Parklicht links ein";
CM_ SG_ 1136 BSK_Parklicht_rechts "1 = Parklicht rehts eingeschaltet (BCM_PQ25: Schalterinformation)
Parklicht rechts ein";
CM_ SG_ 1136 BSK_Abblendlicht "Statusmeldungen fuer Anzeige im Kombi
Kl56b Abblendlicht ein";
CM_ SG_ 1136 BSK_Nebellicht "1 = Nebelscheinwerfer eingeschaltet
Kl83a Nebellicht ein";
CM_ SG_ 1136 BSK_Heckscheibenhzg "Zustand der Ansteuerung Heckscheibenheizung wird zur Anzeige im Kombi gemeldet.";
CM_ SG_ 1136 BSK_Tankklappe "Es wird ein Text 'Tankklappe offen' oder das CAR-Outline Symbol im Kombi angezeigt. Die rechte Schiebetuer geht in den lokalen 'E-KiSi-Modus', solange die Tankklappe geoeffnet ist.";
CM_ SG_ 1136 BSK_FFB_Bat "Textanzeige Batteriestatus FFB";
CM_ SG_ 1136 BSK_FLA_Soft_LED "1 = FLA aktiv, Anzeige im Kombi (Soft-LED)";
CM_ SG_ 1136 BSK_FLA_Sensor_blockiert "FLA Sensor blockiert
Sichtbeeinträchtigung CMOS-Kamera";
CM_ SG_ 1136 BSK_FLA_Defekt "1 = FLA defekt";
CM_ SG_ 1136 BSK_Ruhespannung "Im Transportmodus wird die Batterieruhespannung im Kombi an der Position der Gesamtwegstrecke zur Anzeige gebracht.";
CM_ SG_ 1136 BSK_Nebelschlusslicht "1 = Nebelschlusslicht eingeschaltet
Kl83b Nebelschlussleuchte ein";
CM_ SG_ 1136 BSK_Fernlicht "1 = Licht ein
Kl56a Fernlicht ein";
CM_ SG_ 1136 BSK_Tagfahrlicht "1 = Tagesfahrlicht ist eingeschaltet";
CM_ SG_ 1712 Module_ID_36 "Bordnetz-SG";
CM_ SG_ 1712 Data_Byte_1_36 "Festlegung der Datenbytes siehe CAN Data Exchange Function Datenfestlegung
Datenbyte 1";
CM_ SG_ 1712 Data_Byte_2_36 "Festlegung der Datenbytes siehe CAN Data Exchange Function Datenfestlegung
Datenbyte 2";
CM_ SG_ 1712 Data_Byte_3_36 "Festlegung der Datenbytes siehe CAN Data Exchange Function Datenfestlegung
Datenbyte 3";
CM_ SG_ 1712 Data_Byte_4_36 "Festlegung der Datenbytes siehe CAN Data Exchange Function Datenfestlegung
Datenbyte 4";
CM_ SG_ 1712 Data_Byte_5_36 "Festlegung der Datenbytes siehe CAN Data Exchange Function Datenfestlegung
Datenbyte 5";
CM_ SG_ 1696 Module_ID_0 "Regen-Lichtsensor, AFL";
CM_ SG_ 1696 Data_Byte_1_0 "Festlegung der Datenbytes siehe CAN Data Exchange Function Datenfestlegung
Datenbyte 1";
CM_ SG_ 1696 Data_Byte_2_0 "Festlegung der Datenbytes siehe CAN Data Exchange Function Datenfestlegung
Datenbyte 2";
CM_ SG_ 1696 Data_Byte_3_0 "Festlegung der Datenbytes siehe CAN Data Exchange Function Datenfestlegung
Datenbyte 3";
CM_ SG_ 1696 Data_Byte_4_0 "Festlegung der Datenbytes siehe CAN Data Exchange Function Datenfestlegung
Datenbyte 4";
CM_ SG_ 1696 Data_Byte_5_0 "Festlegung der Datenbytes siehe CAN Data Exchange Function Datenfestlegung
Datenbyte 5";
CM_ SG_ 1713 Module_ID_37 "Komfort-SG";
CM_ SG_ 1713 Data_Byte_1_37 "Festlegung der Datenbytes siehe CAN Data Exchange Function Datenfestlegung
Datenbyte 1";
CM_ SG_ 1713 Data_Byte_2_37 "Festlegung der Datenbytes siehe CAN Data Exchange Function Datenfestlegung
Datenbyte 2";
CM_ SG_ 1713 Data_Byte_3_37 "Festlegung der Datenbytes siehe CAN Data Exchange Function Datenfestlegung
Datenbyte 3";
CM_ SG_ 1713 Data_Byte_4_37 "Festlegung der Datenbytes siehe CAN Data Exchange Function Datenfestlegung
Datenbyte 4";
CM_ SG_ 1713 Data_Byte_5_37 "Festlegung der Datenbytes siehe CAN Data Exchange Function Datenfestlegung
Datenbyte 5";
CM_ SG_ 1697 Module_ID_1 "Komfort-SG";
CM_ SG_ 1697 Data_Byte_1_1 "Festlegung der Datenbytes siehe CAN Data Exchange Function Datenfestlegung
Datenbyte 1";
CM_ SG_ 1697 Data_Byte_2_1 "Festlegung der Datenbytes siehe CAN Data Exchange Function Datenfestlegung
Datenbyte 2";
CM_ SG_ 1697 Data_Byte_3_1 "Festlegung der Datenbytes siehe CAN Data Exchange Function Datenfestlegung
Datenbyte 3";
CM_ SG_ 1697 Data_Byte_4_1 "Festlegung der Datenbytes siehe CAN Data Exchange Function Datenfestlegung
Datenbyte 4";
CM_ SG_ 1697 Data_Byte_5_1 "Festlegung der Datenbytes siehe CAN Data Exchange Function Datenfestlegung
Datenbyte 5";
CM_ SG_ 1782 Module_ID_21 "Klima";
CM_ SG_ 1782 Data_Byte_1_21 "Festlegung der Datenbytes siehe CAN Data Exchange Function Datenfestlegung
Datenbyte 1";
CM_ SG_ 1782 Data_Byte_2_21 "Festlegung der Datenbytes siehe CAN Data Exchange Function Datenfestlegung
Datenbyte 2";
CM_ SG_ 1782 Data_Byte_3_21 "Festlegung der Datenbytes siehe CAN Data Exchange Function Datenfestlegung
Datenbyte 3";
CM_ SG_ 1782 Data_Byte_4_21 "Festlegung der Datenbytes siehe CAN Data Exchange Function Datenfestlegung
Datenbyte 4";
CM_ SG_ 1782 Data_Byte_5_21 "Festlegung der Datenbytes siehe CAN Data Exchange Function Datenfestlegung
Datenbyte 5";
CM_ SG_ 1763 Module_ID_33 "Bordnetz-SG";
CM_ SG_ 1763 Data_Byte_1_33 "Festlegung der Datenbytes siehe CAN Data Exchange Function Datenfestlegung
Datenbyte 1";
CM_ SG_ 1763 Data_Byte_2_33 "Festlegung der Datenbytes siehe CAN Data Exchange Function Datenfestlegung
Datenbyte 2";
CM_ SG_ 1763 Data_Byte_3_33 "Festlegung der Datenbytes siehe CAN Data Exchange Function Datenfestlegung
Datenbyte 3";
CM_ SG_ 1763 Data_Byte_4_33 "Festlegung der Datenbytes siehe CAN Data Exchange Function Datenfestlegung
Datenbyte 4";
CM_ SG_ 1763 Data_Byte_5_33 "Festlegung der Datenbytes siehe CAN Data Exchange Function Datenfestlegung
Datenbyte 5";
CM_ SG_ 1764 Module_ID_34 "Komfort-SG";
CM_ SG_ 1764 Data_Byte_1_34 "Festlegung der Datenbytes siehe CAN Data Exchange Function Datenfestlegung
Datenbyte 1";
CM_ SG_ 1764 Data_Byte_2_34 "Festlegung der Datenbytes siehe CAN Data Exchange Function Datenfestlegung
Datenbyte 2";
CM_ SG_ 1764 Data_Byte_3_34 "Festlegung der Datenbytes siehe CAN Data Exchange Function Datenfestlegung
Datenbyte 3";
CM_ SG_ 1764 Data_Byte_4_34 "Festlegung der Datenbytes siehe CAN Data Exchange Function Datenfestlegung
Datenbyte 4";
CM_ SG_ 1764 Data_Byte_5_34 "Festlegung der Datenbytes siehe CAN Data Exchange Function Datenfestlegung
Datenbyte 5";
CM_ SG_ 1765 Module_ID_35 "Standheizung-SG";
CM_ SG_ 1765 Data_Byte_1_35 "Festlegung der Datenbytes siehe CAN Data Exchange Function Datenfestlegung
Datenbyte 1";
CM_ SG_ 1765 Data_Byte_2_35 "Festlegung der Datenbytes siehe CAN Data Exchange Function Datenfestlegung
Datenbyte 2";
CM_ SG_ 1765 Data_Byte_3_35 "Festlegung der Datenbytes siehe CAN Data Exchange Function Datenfestlegung
Datenbyte 3";
CM_ SG_ 1765 Data_Byte_4_35 "Festlegung der Datenbytes siehe CAN Data Exchange Function Datenfestlegung
Datenbyte 4";
CM_ SG_ 1765 Data_Byte_5_35 "Festlegung der Datenbytes siehe CAN Data Exchange Function Datenfestlegung
Datenbyte 5";
CM_ SG_ 1704 Module_ID_8 "Standheizung";
CM_ SG_ 1704 Data_Byte_1_8 "Festlegung der Datenbytes siehe CAN Data Exchange Function Datenfestlegung
Datenbyte 1";
CM_ SG_ 1704 Data_Byte_2_8 "Festlegung der Datenbytes siehe CAN Data Exchange Function Datenfestlegung
Datenbyte 2";
CM_ SG_ 1704 Data_Byte_3_8 "Festlegung der Datenbytes siehe CAN Data Exchange Function Datenfestlegung
Datenbyte 3";
CM_ SG_ 1704 Data_Byte_4_8 "Festlegung der Datenbytes siehe CAN Data Exchange Function Datenfestlegung
Datenbyte 4";
CM_ SG_ 1704 Data_Byte_5_8 "Festlegung der Datenbytes siehe CAN Data Exchange Function Datenfestlegung
Datenbyte 5";
CM_ SG_ 1714 Module_ID_38 "Standheizung-SG";
CM_ SG_ 1714 Data_Byte_1_38 "Festlegung der Datenbytes siehe CAN Data Exchange Function Datenfestlegung
Datenbyte 1";
CM_ SG_ 1714 Data_Byte_2_38 "Festlegung der Datenbytes siehe CAN Data Exchange Function Datenfestlegung
Datenbyte 2";
CM_ SG_ 1714 Data_Byte_3_38 "Festlegung der Datenbytes siehe CAN Data Exchange Function Datenfestlegung
Datenbyte 3";
CM_ SG_ 1714 Data_Byte_4_38 "Festlegung der Datenbytes siehe CAN Data Exchange Function Datenfestlegung
Datenbyte 4";
CM_ SG_ 1714 Data_Byte_5_38 "Festlegung der Datenbytes siehe CAN Data Exchange Function Datenfestlegung
Datenbyte 5";
CM_ SG_ 1698 Module_ID_2 "Standheizung";
CM_ SG_ 1698 Data_Byte_1_2 "Festlegung der Datenbytes siehe CAN Data Exchange Function Datenfestlegung
Datenbyte 1";
CM_ SG_ 1698 Data_Byte_2_2 "Festlegung der Datenbytes siehe CAN Data Exchange Function Datenfestlegung
Datenbyte 2";
CM_ SG_ 1698 Data_Byte_3_2 "Festlegung der Datenbytes siehe CAN Data Exchange Function Datenfestlegung
Datenbyte 3";
CM_ SG_ 1698 Data_Byte_4_2 "Festlegung der Datenbytes siehe CAN Data Exchange Function Datenfestlegung
Datenbyte 4";
CM_ SG_ 1698 Data_Byte_5_2 "Festlegung der Datenbytes siehe CAN Data Exchange Function Datenfestlegung
Datenbyte 5";
CM_ SG_ 1760 Module_ID_30 "Bordnetz-SG";
CM_ SG_ 1760 Data_Byte_1_30 "Festlegung der Datenbytes siehe CAN Data Exchange Function Datenfestlegung
Datenbyte 1";
CM_ SG_ 1760 Data_Byte_2_30 "Festlegung der Datenbytes siehe CAN Data Exchange Function Datenfestlegung
Datenbyte 2";
CM_ SG_ 1760 Data_Byte_3_30 "Festlegung der Datenbytes siehe CAN Data Exchange Function Datenfestlegung
Datenbyte 3";
CM_ SG_ 1760 Data_Byte_4_30 "Festlegung der Datenbytes siehe CAN Data Exchange Function Datenfestlegung
Datenbyte 4";
CM_ SG_ 1760 Data_Byte_5_30 "Festlegung der Datenbytes siehe CAN Data Exchange Function Datenfestlegung
Datenbyte 5";
CM_ SG_ 1761 Module_ID_31 "Komfort-SG";
CM_ SG_ 1761 Data_Byte_1_31 "Festlegung der Datenbytes siehe CAN Data Exchange Function Datenfestlegung
Datenbyte 1";
CM_ SG_ 1761 Data_Byte_2_31 "Festlegung der Datenbytes siehe CAN Data Exchange Function Datenfestlegung
Datenbyte 2";
CM_ SG_ 1761 Data_Byte_3_31 "Festlegung der Datenbytes siehe CAN Data Exchange Function Datenfestlegung
Datenbyte 3";
CM_ SG_ 1761 Data_Byte_4_31 "Festlegung der Datenbytes siehe CAN Data Exchange Function Datenfestlegung
Datenbyte 4";
CM_ SG_ 1761 Data_Byte_5_31 "Festlegung der Datenbytes siehe CAN Data Exchange Function Datenfestlegung
Datenbyte 5";
CM_ SG_ 1762 Module_ID_32 "Standheizung";
CM_ SG_ 1762 Data_Byte_1_32 "Festlegung der Datenbytes siehe CAN Data Exchange Function Datenfestlegung
Datenbyte 1";
CM_ SG_ 1762 Data_Byte_2_32 "Festlegung der Datenbytes siehe CAN Data Exchange Function Datenfestlegung
Datenbyte 2";
CM_ SG_ 1762 Data_Byte_3_32 "Festlegung der Datenbytes siehe CAN Data Exchange Function Datenfestlegung
Datenbyte 3";
CM_ SG_ 1762 Data_Byte_4_32 "Festlegung der Datenbytes siehe CAN Data Exchange Function Datenfestlegung
Datenbyte 4";
CM_ SG_ 1762 Data_Byte_5_32 "Festlegung der Datenbytes siehe CAN Data Exchange Function Datenfestlegung
Datenbyte 5";
CM_ BO_ 993 "CAN-Komfort";
CM_ SG_ 993 CL1_Drehzahlanhebung "1 = Drehzahlanhebung, Forderung an den Motor bei zu geringer Kälte- / Heizleistung
Signal fuer Drehzahlanhebung";
CM_ SG_ 993 CL1_Zuheizer "1 = Zuheizerfreigabe
(im Hybrid Anforderung auf Lauf des VM zur Erhöhung der Abwärme für Heizleistung)
Fahrerwunsch Zuheizer";
CM_ SG_ 993 CL1_HzgHeckscheibe "1 = Heckscheibenheizung ein
Hzg Heckscheibe angesteuert (Power)";
CM_ SG_ 993 CL1_HzgFrontscheibe "1 = Frontscheibenheizung ein
Hzg Frontscheibe angesteuert (Power)";
CM_ SG_ 993 CL1_Kompressor "1 = Kompressor ein, Zustand incl. 140ms Vorsteuerung, Info an das MSG: Kompressor EIN, PQ34_lang: Anforderung an das MSG: Kompressor einschalten";
CM_ SG_ 993 CL1_Heizung_aus "1, wenn beide Temperaturklappen auf Kaltanschlag stehen, an MSG um hohe Kühlmitteltemp. zu fahren
Keine Heizleistung gewuenscht";
CM_ SG_ 993 CL1_Kompressormoment_alt "1 = veraltet; Ermittlung des Moments nicht moelich (z.B. keine Drehzahl, kein Kaeltemitteldruck)'
Kompressormoment veraltet";
CM_ SG_ 993 CL1_Kaeltemitteldruck_alt "1 = veraltet; bei Klemme 15 aus
Kaeltemitteldruck veraltet";
CM_ SG_ 993 CL1_AussenTemp "FF = Fehler
Ansauglufttemperatur fuer die Climaanlage
im PQ25 kein Temperatursensor im Wasserkasten
Aussentemperatur ungefiltert Wasserkasten";
CM_ SG_ 993 CL1_KaeltemittelDruck "FF = Fehler
Kaeltemitteldruck";
CM_ SG_ 993 CL1_Last_Kompressor "Verlustmoment der Klimaanlage in Nm
Lastinfo: Kompressorzustand";
CM_ SG_ 993 CL1_Geblaeselast "Lastinfo: Geblaeseansteuerung";
CM_ SG_ 993 CL1_Strg_Kluefter "Ansteuerung des Kuehlerluefters in Prozent";
CM_ SG_ 993 CL1_Temp_in_F "1 = Klimaanlage zeigt die Temperatur in Fahrenheit an, Temp auf dem Bus in °C !!";
CM_ SG_ 993 CL1_AC_Schalter "1 = AC-Schalter gedrueckt
Abbildung des AC-Schalters";
CM_ SG_ 993 CL1_WAPU_Zuschaltung "1 = Wasserpumpe ist nicht zugeschaltet
Ein/ Ausschalten der Wasserpumpe zwecks CO2 Einsparung";
CM_ SG_ 993 CL1_Restwaerme "1 = Restwaermefunktion ist aktiviert, Statusinformation, d.h. Geblaeselast ist vorhanden";
CM_ SG_ 993 CL1_PTC_Clima "0 = PTC Heizung aus
1 = Leistung PTC Heizung <= 25%
2 = Leistung PTC Heizung <= 50%
3 = Leistung PTC Heizung <= 75%
4 = Leistung PTC Heizung <= 100%
Status der Klima PTC Heizung";
CM_ SG_ 993 CL1_KD_Fehler "1 = mindestens 1 Kundendienstfehler ist im Fehlerspeicher eingetragen";
CM_ SG_ 993 KL_Thermomanagement "Stufen des Thermomanagements";
BA_DEF_  "GenNWMApBusSleep" STRING ;
BA_DEF_  "GenNWMApCanNormal" STRING ;
BA_DEF_  "GenNWMApCanOff" STRING ;
BA_DEF_  "GenNWMApCanOn" STRING ;
BA_DEF_  "GenNWMApCanSleep" STRING ;
BA_DEF_  "GenNWMApCanWakeUp" STRING ;
BA_DEF_  "GenNWMGotoMode_Awake" STRING ;
BA_DEF_  "GenNWMGotoMode_BusSleep" STRING ;
BA_DEF_  "GenNWMSleepTime" INT 0 1000000;
BA_DEF_  "GenNWMTalkNM" STRING ;
BA_DEF_  "Manufacturer" STRING ;
BA_DEF_  "NmBaseAddress" HEX 0 2047;
BA_DEF_  "NmMessageCount" INT 1 255;
BA_DEF_  "NmType" STRING ;
BA_DEF_  "VAGTP20_SetupMessageCount" INT 0 255;
BA_DEF_  "VAGTP20_SetupStartAddress" HEX 0 2047;
BA_DEF_  "VersionDay" INT 1 31;
BA_DEF_  "VersionMonth" INT 1 12;
BA_DEF_  "VersionWeek" INT 1 52;
BA_DEF_  "VersionYear" INT 0 99;
BA_DEF_  "VersionNumber" INT 0 65535;
BA_DEF_  "Baudrate" INT 0 1000000;
BA_DEF_  "SamplePointMin" INT 1 100;
BA_DEF_  "SamplePointMax" INT 1 100;
BA_DEF_  "SyncJumpWidthMin" INT 1 4;
BA_DEF_  "SyncJumpWidthMax" INT 1 4;
BA_DEF_ BU_  "GenNodAutoGenDsp" ENUM  "No","Yes";
BA_DEF_ BU_  "GenNodAutoGenSnd" ENUM  "No","Yes";
BA_DEF_ BU_  "GenNodSleepTime" INT 0 1000000;
BA_DEF_ BU_  "ILUsed" ENUM  "No","Yes";
BA_DEF_ BU_  "NmStationAddress" HEX 0 63;
BA_DEF_ BU_  "VAGTP20_TargetAddress" HEX 0 127;
BA_DEF_ BU_  "NodeLayerModules" STRING ;
BA_DEF_ BU_  "NmhNode" ENUM  "No","Yes";
BA_DEF_ BU_  "NmNode" ENUM  "No","Yes";
BA_DEF_ BO_  "GenMsgAutoGenDsp" ENUM  "No","Yes";
BA_DEF_ BO_  "GenMsgAutoGenSnd" ENUM  "No","Yes";
BA_DEF_ BO_  "GenMsgCycleTime" INT 0 65535;
BA_DEF_ BO_  "GenMsgCycleTimeFast" INT 0 65535;
BA_DEF_ BO_  "GenMsgDelayTime" INT 0 100000;
BA_DEF_ BO_  "GenMsgILSupport" ENUM  "No","Yes";
BA_DEF_ BO_  "GenMsgNrOfRepetition" INT 0 100;
BA_DEF_ BO_  "GenMsgSendType" ENUM  "Cyclic","not_used","not_used","not_used","not_used","not_used","not_used","IfActive","NoMsgSendType";
BA_DEF_ BO_  "GenMsgStartDelayTime" INT 0 100000;
BA_DEF_ BO_  "NmMessage" ENUM  "No","Yes";
BA_DEF_ BO_  "NmhMessage" ENUM  "No","Yes";
BA_DEF_ BO_  "VAGTP20_API" HEX 0 255;
BA_DEF_ BO_  "VAGTP20_DynConnection" ENUM  "No","Yes";
BA_DEF_ BO_  "VAGTP20_DynSetup" ENUM  "No","Yes";
BA_DEF_ BO_  "VAGTP20_StatConnection" ENUM  "No","Yes";
BA_DEF_ BO_  "DiagRequest" ENUM  "No","Yes";
BA_DEF_ BO_  "DiagResponse" ENUM  "No","Yes";
BA_DEF_ BO_  "DiagState" ENUM  "No","Yes";
BA_DEF_ SG_  "GenSigAutoGenDsp" ENUM  "No","Yes";
BA_DEF_ SG_  "GenSigAutoGenSnd" ENUM  "No","Yes";
BA_DEF_ SG_  "GenSigEnvVarType" ENUM  "int","float","undef";
BA_DEF_ SG_  "GenSigInactiveValue" INT -2147483648 2147483647;
BA_DEF_ SG_  "GenSigSendType" ENUM  "Cyclic","OnWrite","OnWriteWithRepetition","OnChange","OnChangeWithRepetition","IfActive","IfActiveWithRepetition","NoSigSendType","OnChangeAndIfActive","OnChangeAndIfActiveWithRepetition";
BA_DEF_ SG_  "GenSigStartValue" INT -2147483648 2147483647;
BA_DEF_ SG_  "NWM-WakeupAllowed" ENUM  "No","Yes";
BA_DEF_ SG_  "GenSigFuncType" ENUM  "NoFunction","MsgCounter","CRC-8","XOR","XOR-2","DatedBit","SW-Kl15","CHK","Constant","Protocol";
BA_DEF_ SG_  "GenSigSwitchedByIgnition" ENUM  "No","Yes";
BA_DEF_ SG_  "Fehlerwert" HEX 0 2147483647;
BA_DEF_DEF_  "GenNWMApBusSleep" "";
BA_DEF_DEF_  "GenNWMApCanNormal" "";
BA_DEF_DEF_  "GenNWMApCanOff" "";
BA_DEF_DEF_  "GenNWMApCanOn" "";
BA_DEF_DEF_  "GenNWMApCanSleep" "";
BA_DEF_DEF_  "GenNWMApCanWakeUp" "";
BA_DEF_DEF_  "GenNWMGotoMode_Awake" "";
BA_DEF_DEF_  "GenNWMGotoMode_BusSleep" "";
BA_DEF_DEF_  "GenNWMSleepTime" 0;
BA_DEF_DEF_  "GenNWMTalkNM" "";
BA_DEF_DEF_  "Manufacturer" "";
BA_DEF_DEF_  "NmBaseAddress" 0;
BA_DEF_DEF_  "NmMessageCount" 1;
BA_DEF_DEF_  "NmType" "None";
BA_DEF_DEF_  "VAGTP20_SetupMessageCount" 0;
BA_DEF_DEF_  "VAGTP20_SetupStartAddress" 0;
BA_DEF_DEF_  "VersionDay" 4;
BA_DEF_DEF_  "VersionMonth" 11;
BA_DEF_DEF_  "VersionWeek" 45;
BA_DEF_DEF_  "VersionYear" 8;
BA_DEF_DEF_  "VersionNumber" 0;
BA_DEF_DEF_  "Baudrate" 0;
BA_DEF_DEF_  "SamplePointMin" 1;
BA_DEF_DEF_  "SamplePointMax" 1;
BA_DEF_DEF_  "SyncJumpWidthMin" 1;
BA_DEF_DEF_  "SyncJumpWidthMax" 1;
BA_DEF_DEF_  "GenNodAutoGenDsp" "Yes";
BA_DEF_DEF_  "GenNodAutoGenSnd" "Yes";
BA_DEF_DEF_  "GenNodSleepTime" 0;
BA_DEF_DEF_  "ILUsed" "No";
BA_DEF_DEF_  "NmStationAddress" 0;
BA_DEF_DEF_  "VAGTP20_TargetAddress" 0;
BA_DEF_DEF_  "NodeLayerModules" "";
BA_DEF_DEF_  "NmhNode" "Yes";
BA_DEF_DEF_  "NmNode" "No";
BA_DEF_DEF_  "GenMsgAutoGenDsp" "Yes";
BA_DEF_DEF_  "GenMsgAutoGenSnd" "Yes";
BA_DEF_DEF_  "GenMsgCycleTime" 0;
BA_DEF_DEF_  "GenMsgCycleTimeFast" 0;
BA_DEF_DEF_  "GenMsgDelayTime" 0;
BA_DEF_DEF_  "GenMsgILSupport" "No";
BA_DEF_DEF_  "GenMsgNrOfRepetition" 0;
BA_DEF_DEF_  "GenMsgSendType" "NoMsgSendType";
BA_DEF_DEF_  "GenMsgStartDelayTime" 0;
BA_DEF_DEF_  "NmMessage" "No";
BA_DEF_DEF_  "NmhMessage" "No";
BA_DEF_DEF_  "VAGTP20_API" 0;
BA_DEF_DEF_  "VAGTP20_DynConnection" "No";
BA_DEF_DEF_  "VAGTP20_DynSetup" "No";
BA_DEF_DEF_  "VAGTP20_StatConnection" "No";
BA_DEF_DEF_  "DiagRequest" "No";
BA_DEF_DEF_  "DiagResponse" "No";
BA_DEF_DEF_  "DiagState" "No";
BA_DEF_DEF_  "GenSigAutoGenDsp" "No";
BA_DEF_DEF_  "GenSigAutoGenSnd" "No";
BA_DEF_DEF_  "GenSigEnvVarType" "undef";
BA_DEF_DEF_  "GenSigInactiveValue" 0;
BA_DEF_DEF_  "GenSigSendType" "NoSigSendType";
BA_DEF_DEF_  "GenSigStartValue" 0;
BA_DEF_DEF_  "NWM-WakeupAllowed" "No";
BA_DEF_DEF_  "GenSigFuncType" "NoFunction";
BA_DEF_DEF_  "GenSigSwitchedByIgnition" "No";
BA_DEF_DEF_  "Fehlerwert" 0;
BA_ "GenNWMApBusSleep" "apBusSleep()";
BA_ "GenNWMApCanNormal" "apCanNormal()";
BA_ "GenNWMApCanOff" "apCanOff()";
BA_ "GenNWMApCanOn" "apCanOff()";
BA_ "GenNWMApCanSleep" "apCanSleep()";
BA_ "GenNWMApCanWakeUp" "apCanWakeUp()";
BA_ "GenNWMGotoMode_Awake" "gotoMode_Awake()";
BA_ "GenNWMGotoMode_BusSleep" "gotoMode_Bussleep()";
BA_ "GenNWMSleepTime" 4000;
BA_ "GenNWMTalkNM" "talkNM()";
BA_ "Manufacturer" "VAG";
BA_ "NmBaseAddress" 1024;
BA_ "NmMessageCount" 64;
BA_ "NmType" "VAG-OSEK";
BA_ "VAGTP20_SetupMessageCount" 128;
BA_ "VAGTP20_SetupStartAddress" 512;
BA_ "VersionNumber" 1;
BA_ "Baudrate" 100000;
BA_ "SamplePointMin" 80;
BA_ "SamplePointMax" 84;
BA_ "SyncJumpWidthMin" 3;
BA_ "SyncJumpWidthMax" 4;
BA_ "ILUsed" BU_ BAP_Tester 1;
BA_ "NmhNode" BU_ BAP_Tester 0;
BA_ "GenNodSleepTime" BU_ Booster_AMP 4000;
BA_ "ILUsed" BU_ Booster_AMP 1;
BA_ "NmStationAddress" BU_ Booster_AMP 51;
BA_ "VAGTP20_TargetAddress" BU_ Booster_AMP 83;
BA_ "NodeLayerModules" BU_ Booster_AMP "VAGNM01.DLL";
BA_ "NmhNode" BU_ Booster_AMP 0;
BA_ "NmNode" BU_ Booster_AMP 1;
BA_ "GenNodSleepTime" BU_ DSP_SKODA 4000;
BA_ "ILUsed" BU_ DSP_SKODA 1;
BA_ "NmStationAddress" BU_ DSP_SKODA 51;
BA_ "VAGTP20_TargetAddress" BU_ DSP_SKODA 83;
BA_ "NodeLayerModules" BU_ DSP_SKODA "VAGNM01.DLL";
BA_ "NmhNode" BU_ DSP_SKODA 0;
BA_ "NmNode" BU_ DSP_SKODA 1;
BA_ "GenNodSleepTime" BU_ Gateway_PQ35 4000;
BA_ "ILUsed" BU_ Gateway_PQ35 1;
BA_ "VAGTP20_TargetAddress" BU_ Gateway_PQ35 31;
BA_ "NodeLayerModules" BU_ Gateway_PQ35 "VAGNM01.DLL";
BA_ "NmhNode" BU_ Gateway_PQ35 0;
BA_ "NmNode" BU_ Gateway_PQ35 1;
BA_ "NmStationAddress" BU_ Gateway_PQ35 43;
BA_ "GenNodSleepTime" BU_ Gateway_PQ46 4000;
BA_ "ILUsed" BU_ Gateway_PQ46 1;
BA_ "VAGTP20_TargetAddress" BU_ Gateway_PQ46 31;
BA_ "NodeLayerModules" BU_ Gateway_PQ46 "VAGNM01.DLL";
BA_ "NmhNode" BU_ Gateway_PQ46 0;
BA_ "NmNode" BU_ Gateway_PQ46 1;
BA_ "NmStationAddress" BU_ Gateway_PQ46 43;
BA_ "GenNodSleepTime" BU_ GSM_Pager 4000;
BA_ "ILUsed" BU_ GSM_Pager 1;
BA_ "NmStationAddress" BU_ GSM_Pager 40;
BA_ "VAGTP20_TargetAddress" BU_ GSM_Pager 65;
BA_ "NodeLayerModules" BU_ GSM_Pager "VAGNM01.DLL";
BA_ "NmhNode" BU_ GSM_Pager 0;
BA_ "NmNode" BU_ GSM_Pager 1;
BA_ "GenNodSleepTime" BU_ Kompassmodul 4000;
BA_ "ILUsed" BU_ Kompassmodul 1;
BA_ "NmStationAddress" BU_ Kompassmodul 52;
BA_ "VAGTP20_TargetAddress" BU_ Kompassmodul 64;
BA_ "NodeLayerModules" BU_ Kompassmodul "VAGNM01.DLL";
BA_ "NmhNode" BU_ Kompassmodul 0;
BA_ "NmNode" BU_ Kompassmodul 1;
BA_ "GenNodSleepTime" BU_ MDI 4000;
BA_ "ILUsed" BU_ MDI 1;
BA_ "NmStationAddress" BU_ MDI 53;
BA_ "VAGTP20_TargetAddress" BU_ MDI 84;
BA_ "NodeLayerModules" BU_ MDI "VAGNM01.DLL";
BA_ "NmhNode" BU_ MDI 0;
BA_ "NmNode" BU_ MDI 1;
BA_ "GenNodSleepTime" BU_ Radio_2DIN 4000;
BA_ "ILUsed" BU_ Radio_2DIN 1;
BA_ "NmStationAddress" BU_ Radio_2DIN 57;
BA_ "VAGTP20_TargetAddress" BU_ Radio_2DIN 82;
BA_ "NodeLayerModules" BU_ Radio_2DIN "VAGNM01.DLL";
BA_ "NmhNode" BU_ Radio_2DIN 0;
BA_ "NmNode" BU_ Radio_2DIN 1;
BA_ "GenNodSleepTime" BU_ Radio_Modul 4000;
BA_ "ILUsed" BU_ Radio_Modul 1;
BA_ "NmStationAddress" BU_ Radio_Modul 57;
BA_ "VAGTP20_TargetAddress" BU_ Radio_Modul 82;
BA_ "NodeLayerModules" BU_ Radio_Modul "VAGNM01.DLL";
BA_ "NmhNode" BU_ Radio_Modul 0;
BA_ "NmNode" BU_ Radio_Modul 1;
BA_ "GenNodSleepTime" BU_ Radio_SKODA 4000;
BA_ "ILUsed" BU_ Radio_SKODA 1;
BA_ "NmStationAddress" BU_ Radio_SKODA 57;
BA_ "VAGTP20_TargetAddress" BU_ Radio_SKODA 82;
BA_ "NodeLayerModules" BU_ Radio_SKODA "VAGNM01.DLL";
BA_ "NmhNode" BU_ Radio_SKODA 0;
BA_ "NmNode" BU_ Radio_SKODA 1;
BA_ "GenNodSleepTime" BU_ Rearview 4000;
BA_ "ILUsed" BU_ Rearview 1;
BA_ "NmStationAddress" BU_ Rearview 41;
BA_ "VAGTP20_TargetAddress" BU_ Rearview 73;
BA_ "NodeLayerModules" BU_ Rearview "VAGNM01.DLL";
BA_ "NmhNode" BU_ Rearview 0;
BA_ "NmNode" BU_ Rearview 1;
BA_ "GenNodSleepTime" BU_ RNS_300_NF 4000;
BA_ "ILUsed" BU_ RNS_300_NF 1;
BA_ "NmStationAddress" BU_ RNS_300_NF 54;
BA_ "NodeLayerModules" BU_ RNS_300_NF "VAGNM01.DLL";
BA_ "NmhNode" BU_ RNS_300_NF 0;
BA_ "NmNode" BU_ RNS_300_NF 1;
BA_ "VAGTP20_TargetAddress" BU_ RNS_300_NF 91;
BA_ "GenNodSleepTime" BU_ RNS_MFD2 4000;
BA_ "ILUsed" BU_ RNS_MFD2 1;
BA_ "NmStationAddress" BU_ RNS_MFD2 54;
BA_ "VAGTP20_TargetAddress" BU_ RNS_MFD2 91;
BA_ "NodeLayerModules" BU_ RNS_MFD2 "VAGNM01.DLL";
BA_ "NmhNode" BU_ RNS_MFD2 0;
BA_ "NmNode" BU_ RNS_MFD2 1;
BA_ "GenNodSleepTime" BU_ RNS_midline 4000;
BA_ "ILUsed" BU_ RNS_midline 1;
BA_ "NmStationAddress" BU_ RNS_midline 54;
BA_ "NodeLayerModules" BU_ RNS_midline "VAGNM01.DLL";
BA_ "NmhNode" BU_ RNS_midline 0;
BA_ "NmNode" BU_ RNS_midline 1;
BA_ "GenNodSleepTime" BU_ SDARS_Tuner 4000;
BA_ "ILUsed" BU_ SDARS_Tuner 1;
BA_ "NmStationAddress" BU_ SDARS_Tuner 47;
BA_ "VAGTP20_TargetAddress" BU_ SDARS_Tuner 79;
BA_ "NodeLayerModules" BU_ SDARS_Tuner "VAGNM01.DLL";
BA_ "NmhNode" BU_ SDARS_Tuner 0;
BA_ "NmNode" BU_ SDARS_Tuner 1;
BA_ "GenNodSleepTime" BU_ Sprachbedienung 4000;
BA_ "ILUsed" BU_ Sprachbedienung 1;
BA_ "NmStationAddress" BU_ Sprachbedienung 60;
BA_ "VAGTP20_TargetAddress" BU_ Sprachbedienung 92;
BA_ "NodeLayerModules" BU_ Sprachbedienung "VAGNM01.DLL";
BA_ "NmhNode" BU_ Sprachbedienung 0;
BA_ "NmNode" BU_ Sprachbedienung 1;
BA_ "GenNodSleepTime" BU_ Standheizung 4000;
BA_ "ILUsed" BU_ Standheizung 1;
BA_ "NmStationAddress" BU_ Standheizung 39;
BA_ "VAGTP20_TargetAddress" BU_ Standheizung 47;
BA_ "NodeLayerModules" BU_ Standheizung "VAGNM01.DLL";
BA_ "NmhNode" BU_ Standheizung 0;
BA_ "NmNode" BU_ Standheizung 1;
BA_ "GenNodSleepTime" BU_ Tastatur 4000;
BA_ "ILUsed" BU_ Tastatur 1;
BA_ "NmStationAddress" BU_ Tastatur 38;
BA_ "VAGTP20_TargetAddress" BU_ Tastatur 75;
BA_ "NodeLayerModules" BU_ Tastatur "VAGNM01.DLL";
BA_ "NmhNode" BU_ Tastatur 0;
BA_ "NmNode" BU_ Tastatur 1;
BA_ "GenNodSleepTime" BU_ Telematik_Basis 4000;
BA_ "ILUsed" BU_ Telematik_Basis 1;
BA_ "NmStationAddress" BU_ Telematik_Basis 61;
BA_ "VAGTP20_TargetAddress" BU_ Telematik_Basis 85;
BA_ "NodeLayerModules" BU_ Telematik_Basis "VAGNM01.DLL";
BA_ "NmhNode" BU_ Telematik_Basis 0;
BA_ "NmNode" BU_ Telematik_Basis 1;
BA_ "GenNodSleepTime" BU_ TV_hybrid 4000;
BA_ "ILUsed" BU_ TV_hybrid 1;
BA_ "NmStationAddress" BU_ TV_hybrid 55;
BA_ "VAGTP20_TargetAddress" BU_ TV_hybrid 87;
BA_ "NodeLayerModules" BU_ TV_hybrid "VAGNM01.DLL";
BA_ "NmhNode" BU_ TV_hybrid 0;
BA_ "NmNode" BU_ TV_hybrid 1;
BA_ "GenNodSleepTime" BU_ UHV_High 4000;
BA_ "ILUsed" BU_ UHV_High 1;
BA_ "NmStationAddress" BU_ UHV_High 58;
BA_ "VAGTP20_TargetAddress" BU_ UHV_High 90;
BA_ "NodeLayerModules" BU_ UHV_High "VAGNM01.DLL";
BA_ "NmhNode" BU_ UHV_High 0;
BA_ "NmNode" BU_ UHV_High 1;
BA_ "GenNodSleepTime" BU_ UHV_low 4000;
BA_ "ILUsed" BU_ UHV_low 1;
BA_ "NmStationAddress" BU_ UHV_low 58;
BA_ "VAGTP20_TargetAddress" BU_ UHV_low 90;
BA_ "NodeLayerModules" BU_ UHV_low "VAGNM01.DLL";
BA_ "NmhNode" BU_ UHV_low 0;
BA_ "NmNode" BU_ UHV_low 1;
BA_ "GenNodSleepTime" BU_ UHV_NAR 4000;
BA_ "ILUsed" BU_ UHV_NAR 1;
BA_ "NmStationAddress" BU_ UHV_NAR 58;
BA_ "NodeLayerModules" BU_ UHV_NAR "VAGNM01.DLL";
BA_ "NmhNode" BU_ UHV_NAR 0;
BA_ "NmNode" BU_ UHV_NAR 1;
BA_ "GenNodSleepTime" BU_ UHV_Premium 4000;
BA_ "ILUsed" BU_ UHV_Premium 1;
BA_ "NmStationAddress" BU_ UHV_Premium 58;
BA_ "VAGTP20_TargetAddress" BU_ UHV_Premium 90;
BA_ "NodeLayerModules" BU_ UHV_Premium "VAGNM01.DLL";
BA_ "NmhNode" BU_ UHV_Premium 0;
BA_ "NmNode" BU_ UHV_Premium 1;
BA_ "GenNodSleepTime" BU_ UHV_UMTS 4000;
BA_ "ILUsed" BU_ UHV_UMTS 1;
BA_ "NmStationAddress" BU_ UHV_UMTS 58;
BA_ "NodeLayerModules" BU_ UHV_UMTS "VAGNM01.DLL";
BA_ "NmhNode" BU_ UHV_UMTS 0;
BA_ "NmNode" BU_ UHV_UMTS 1;
BA_ "GenMsgAutoGenDsp" BO_ 1903 0;
BA_ "GenMsgAutoGenSnd" BO_ 1903 0;
BA_ "DiagRequest" BO_ 1903 1;
BA_ "GenMsgAutoGenDsp" BO_ 2009 0;
BA_ "GenMsgAutoGenSnd" BO_ 2009 0;
BA_ "DiagResponse" BO_ 2009 1;
BA_ "GenMsgAutoGenDsp" BO_ 1792 0;
BA_ "GenMsgAutoGenSnd" BO_ 1792 0;
BA_ "DiagState" BO_ 1792 1;
BA_ "GenMsgAutoGenDsp" BO_ 1907 0;
BA_ "GenMsgAutoGenSnd" BO_ 1907 0;
BA_ "DiagRequest" BO_ 1907 1;
BA_ "GenMsgAutoGenDsp" BO_ 2013 0;
BA_ "GenMsgAutoGenSnd" BO_ 2013 0;
BA_ "DiagResponse" BO_ 2013 1;
BA_ "GenMsgAutoGenDsp" BO_ 1902 0;
BA_ "GenMsgAutoGenSnd" BO_ 1902 0;
BA_ "DiagRequest" BO_ 1902 1;
BA_ "GenMsgAutoGenDsp" BO_ 2008 0;
BA_ "GenMsgAutoGenSnd" BO_ 2008 0;
BA_ "DiagResponse" BO_ 2008 1;
BA_ "GenMsgAutoGenDsp" BO_ 1900 0;
BA_ "GenMsgAutoGenSnd" BO_ 1900 0;
BA_ "DiagRequest" BO_ 1900 1;
BA_ "GenMsgAutoGenDsp" BO_ 2006 0;
BA_ "GenMsgAutoGenSnd" BO_ 2006 0;
BA_ "DiagResponse" BO_ 2006 1;
BA_ "GenMsgAutoGenDsp" BO_ 1816 0;
BA_ "GenMsgAutoGenSnd" BO_ 1816 0;
BA_ "DiagRequest" BO_ 1816 1;
BA_ "GenMsgAutoGenDsp" BO_ 1922 0;
BA_ "GenMsgAutoGenSnd" BO_ 1922 0;
BA_ "DiagResponse" BO_ 1922 1;
BA_ "GenMsgAutoGenDsp" BO_ 1899 0;
BA_ "GenMsgAutoGenSnd" BO_ 1899 0;
BA_ "DiagRequest" BO_ 1899 1;
BA_ "GenMsgAutoGenDsp" BO_ 2005 0;
BA_ "GenMsgAutoGenSnd" BO_ 2005 0;
BA_ "DiagResponse" BO_ 2005 1;
BA_ "GenMsgAutoGenDsp" BO_ 1901 0;
BA_ "GenMsgAutoGenSnd" BO_ 1901 0;
BA_ "DiagRequest" BO_ 1901 1;
BA_ "GenMsgAutoGenDsp" BO_ 2007 0;
BA_ "GenMsgAutoGenSnd" BO_ 2007 0;
BA_ "DiagResponse" BO_ 2007 1;
BA_ "GenMsgCycleTime" BO_ 337 100;
BA_ "GenMsgCycleTimeFast" BO_ 337 20;
BA_ "GenMsgILSupport" BO_ 337 1;
BA_ "GenMsgSendType" BO_ 337 0;
BA_ "GenMsgCycleTime" BO_ 1429 800;
BA_ "GenMsgDelayTime" BO_ 1429 80;
BA_ "GenMsgILSupport" BO_ 1429 1;
BA_ "GenMsgSendType" BO_ 1429 0;
BA_ "GenMsgCycleTime" BO_ 1624 100;
BA_ "GenMsgILSupport" BO_ 1624 1;
BA_ "GenMsgSendType" BO_ 1624 0;
BA_ "GenMsgCycleTime" BO_ 1461 200;
BA_ "GenMsgILSupport" BO_ 1461 1;
BA_ "GenMsgSendType" BO_ 1461 0;
BA_ "GenMsgCycleTime" BO_ 1393 500;
BA_ "GenMsgILSupport" BO_ 1393 1;
BA_ "GenMsgSendType" BO_ 1393 0;
BA_ "GenMsgCycleTime" BO_ 1397 200;
BA_ "GenMsgDelayTime" BO_ 1397 20;
BA_ "GenMsgILSupport" BO_ 1397 1;
BA_ "GenMsgSendType" BO_ 1397 0;
BA_ "GenMsgCycleTime" BO_ 1136 50;
BA_ "GenMsgILSupport" BO_ 1136 1;
BA_ "GenMsgSendType" BO_ 1136 0;
BA_ "GenMsgCycleTime" BO_ 1712 50;
BA_ "GenMsgCycleTimeFast" BO_ 1712 50;
BA_ "GenMsgDelayTime" BO_ 1712 50;
BA_ "GenMsgCycleTime" BO_ 1696 50;
BA_ "GenMsgCycleTimeFast" BO_ 1696 50;
BA_ "GenMsgDelayTime" BO_ 1696 50;
BA_ "GenMsgCycleTime" BO_ 1713 50;
BA_ "GenMsgCycleTimeFast" BO_ 1713 50;
BA_ "GenMsgDelayTime" BO_ 1713 50;
BA_ "GenMsgCycleTime" BO_ 1697 50;
BA_ "GenMsgCycleTimeFast" BO_ 1697 50;
BA_ "GenMsgDelayTime" BO_ 1697 50;
BA_ "GenMsgCycleTime" BO_ 1782 50;
BA_ "GenMsgCycleTimeFast" BO_ 1782 50;
BA_ "GenMsgDelayTime" BO_ 1782 50;
BA_ "GenMsgCycleTime" BO_ 1763 50;
BA_ "GenMsgCycleTimeFast" BO_ 1763 50;
BA_ "GenMsgDelayTime" BO_ 1763 50;
BA_ "GenMsgCycleTime" BO_ 1764 50;
BA_ "GenMsgCycleTimeFast" BO_ 1764 50;
BA_ "GenMsgDelayTime" BO_ 1764 50;
BA_ "GenMsgCycleTime" BO_ 1765 50;
BA_ "GenMsgCycleTimeFast" BO_ 1765 50;
BA_ "GenMsgDelayTime" BO_ 1765 50;
BA_ "GenMsgCycleTime" BO_ 1704 50;
BA_ "GenMsgCycleTimeFast" BO_ 1704 50;
BA_ "GenMsgDelayTime" BO_ 1704 50;
BA_ "GenMsgCycleTime" BO_ 1714 50;
BA_ "GenMsgCycleTimeFast" BO_ 1714 50;
BA_ "GenMsgDelayTime" BO_ 1714 50;
BA_ "GenMsgCycleTime" BO_ 1698 50;
BA_ "GenMsgCycleTimeFast" BO_ 1698 50;
BA_ "GenMsgDelayTime" BO_ 1698 50;
BA_ "GenMsgCycleTime" BO_ 1760 50;
BA_ "GenMsgCycleTimeFast" BO_ 1760 50;
BA_ "GenMsgDelayTime" BO_ 1760 50;
BA_ "GenMsgCycleTime" BO_ 1761 50;
BA_ "GenMsgCycleTimeFast" BO_ 1761 50;
BA_ "GenMsgDelayTime" BO_ 1761 50;
BA_ "GenMsgCycleTime" BO_ 1762 50;
BA_ "GenMsgCycleTimeFast" BO_ 1762 50;
BA_ "GenMsgDelayTime" BO_ 1762 50;
BA_ "GenMsgCycleTime" BO_ 993 100;
BA_ "GenMsgDelayTime" BO_ 993 10;
BA_ "GenMsgILSupport" BO_ 993 1;
BA_ "GenMsgSendType" BO_ 993 0;
BA_ "GenSigAutoGenDsp" SG_ 1658 BAP_Data_Anzeige_02 1;
BA_ "GenSigAutoGenSnd" SG_ 1658 BAP_Data_Anzeige_02 1;
BA_ "GenSigSendType" SG_ 1658 BAP_Data_Anzeige_02 3;
BA_ "GenSigAutoGenDsp" SG_ 1753 BAP_Data_Anzeige_RV 1;
BA_ "GenSigAutoGenSnd" SG_ 1753 BAP_Data_Anzeige_RV 1;
BA_ "GenSigSendType" SG_ 1753 BAP_Data_Anzeige_RV 3;
BA_ "GenSigAutoGenDsp" SG_ 1737 BAP_Data_ASG_02 1;
BA_ "GenSigAutoGenSnd" SG_ 1737 BAP_Data_ASG_02 1;
BA_ "GenSigSendType" SG_ 1737 BAP_Data_ASG_02 3;
BA_ "GenSigAutoGenDsp" SG_ 1735 BAP_Data_ASG_03 1;
BA_ "GenSigAutoGenSnd" SG_ 1735 BAP_Data_ASG_03 1;
BA_ "GenSigSendType" SG_ 1735 BAP_Data_ASG_03 3;
BA_ "GenSigAutoGenDsp" SG_ 1738 BAP_Data_ASG_04 1;
BA_ "GenSigAutoGenSnd" SG_ 1738 BAP_Data_ASG_04 1;
BA_ "GenSigSendType" SG_ 1738 BAP_Data_ASG_04 3;
BA_ "GenSigAutoGenDsp" SG_ 1739 BAP_Data_ASG_05 1;
BA_ "GenSigAutoGenSnd" SG_ 1739 BAP_Data_ASG_05 1;
BA_ "GenSigSendType" SG_ 1739 BAP_Data_ASG_05 3;
BA_ "GenSigAutoGenDsp" SG_ 1734 BAP_Data_ASG_06 1;
BA_ "GenSigAutoGenSnd" SG_ 1734 BAP_Data_ASG_06 1;
BA_ "GenSigSendType" SG_ 1734 BAP_Data_ASG_06 3;
BA_ "GenSigAutoGenDsp" SG_ 1660 BAP_Data_ASG_07 1;
BA_ "GenSigAutoGenSnd" SG_ 1660 BAP_Data_ASG_07 1;
BA_ "GenSigSendType" SG_ 1660 BAP_Data_ASG_07 3;
BA_ "GenSigAutoGenDsp" SG_ 1733 BAP_Data_ASG_08 1;
BA_ "GenSigAutoGenSnd" SG_ 1733 BAP_Data_ASG_08 1;
BA_ "GenSigSendType" SG_ 1733 BAP_Data_ASG_08 3;
BA_ "GenSigAutoGenDsp" SG_ 1774 BAP_Data_ASG_09 1;
BA_ "GenSigAutoGenSnd" SG_ 1774 BAP_Data_ASG_09 1;
BA_ "GenSigSendType" SG_ 1774 BAP_Data_ASG_09 3;
BA_ "GenSigAutoGenDsp" SG_ 1644 BAP_Data_AUDIO 1;
BA_ "GenSigAutoGenSnd" SG_ 1644 BAP_Data_AUDIO 1;
BA_ "GenSigSendType" SG_ 1644 BAP_Data_AUDIO 3;
BA_ "GenSigAutoGenDsp" SG_ 1768 BAP_Data_BC 1;
BA_ "GenSigAutoGenSnd" SG_ 1768 BAP_Data_BC 1;
BA_ "GenSigSendType" SG_ 1768 BAP_Data_BC 3;
BA_ "GenSigAutoGenDsp" SG_ 1755 BAP_Data_Clima 1;
BA_ "GenSigAutoGenSnd" SG_ 1755 BAP_Data_Clima 1;
BA_ "GenSigSendType" SG_ 1755 BAP_Data_Clima 3;
BA_ "GenSigAutoGenDsp" SG_ 1750 BAP_Data_Debug_Cmd 1;
BA_ "GenSigAutoGenSnd" SG_ 1750 BAP_Data_Debug_Cmd 1;
BA_ "GenSigSendType" SG_ 1750 BAP_Data_Debug_Cmd 3;
BA_ "GenSigAutoGenDsp" SG_ 1751 BAP_Debug_Data 1;
BA_ "GenSigAutoGenSnd" SG_ 1751 BAP_Debug_Data 1;
BA_ "GenSigSendType" SG_ 1751 BAP_Debug_Data 3;
BA_ "GenSigAutoGenDsp" SG_ 1752 BAP_Data_DSP 1;
BA_ "GenSigAutoGenSnd" SG_ 1752 BAP_Data_DSP 1;
BA_ "GenSigSendType" SG_ 1752 BAP_Data_DSP 3;
BA_ "GenSigAutoGenDsp" SG_ 1657 BAP_Data_HYB 1;
BA_ "GenSigAutoGenSnd" SG_ 1657 BAP_Data_HYB 1;
BA_ "GenSigSendType" SG_ 1657 BAP_Data_HYB 3;
BA_ "GenSigAutoGenDsp" SG_ 1596 BAP_Data_MDI 1;
BA_ "GenSigAutoGenSnd" SG_ 1596 BAP_Data_MDI 1;
BA_ "GenSigSendType" SG_ 1596 BAP_Data_MDI 3;
BA_ "GenSigAutoGenDsp" SG_ 1580 BAP_Data_MDI_02 1;
BA_ "GenSigAutoGenSnd" SG_ 1580 BAP_Data_MDI_02 1;
BA_ "GenSigSendType" SG_ 1580 BAP_Data_MDI_02 3;
BA_ "GenSigAutoGenDsp" SG_ 1661 BAP_Data_NAVI 1;
BA_ "GenSigAutoGenSnd" SG_ 1661 BAP_Data_NAVI 1;
BA_ "GenSigSendType" SG_ 1661 BAP_Data_NAVI 3;
BA_ "GenSigAutoGenDsp" SG_ 1754 BAP_Data_OPS 1;
BA_ "GenSigAutoGenSnd" SG_ 1754 BAP_Data_OPS 1;
BA_ "GenSigSendType" SG_ 1754 BAP_Data_OPS 3;
BA_ "GenSigSwitchedByIgnition" SG_ 1754 BAP_Data_OPS 1;
BA_ "GenSigAutoGenDsp" SG_ 1756 BAP_Data_Rearview 1;
BA_ "GenSigAutoGenSnd" SG_ 1756 BAP_Data_Rearview 1;
BA_ "GenSigSendType" SG_ 1756 BAP_Data_Rearview 3;
BA_ "GenSigAutoGenDsp" SG_ 1646 BAP_Data_SHZ 1;
BA_ "GenSigAutoGenSnd" SG_ 1646 BAP_Data_SHZ 1;
BA_ "GenSigSendType" SG_ 1646 BAP_Data_SHZ 3;
BA_ "GenSigAutoGenDsp" SG_ 1746 BAP_Data_Telefon_1 1;
BA_ "GenSigAutoGenSnd" SG_ 1746 BAP_Data_Telefon_1 1;
BA_ "GenSigSendType" SG_ 1746 BAP_Data_Telefon_1 3;
BA_ "GenSigAutoGenDsp" SG_ 1749 BAP_Data_Telefon_2 1;
BA_ "GenSigAutoGenSnd" SG_ 1749 BAP_Data_Telefon_2 1;
BA_ "GenSigSendType" SG_ 1749 BAP_Data_Telefon_2 3;
BA_ "GenSigAutoGenDsp" SG_ 1595 BAP_Data_Telefon_3 1;
BA_ "GenSigAutoGenSnd" SG_ 1595 BAP_Data_Telefon_3 1;
BA_ "GenSigSendType" SG_ 1595 BAP_Data_Telefon_3 3;
BA_ "GenSigAutoGenDsp" SG_ 1647 BAP_Data_Telefon_4 1;
BA_ "GenSigAutoGenSnd" SG_ 1647 BAP_Data_Telefon_4 1;
BA_ "GenSigSendType" SG_ 1647 BAP_Data_Telefon_4 3;
BA_ "GenSigAutoGenDsp" SG_ 1747 BAP_Data_TV_Tuner 1;
BA_ "GenSigAutoGenSnd" SG_ 1747 BAP_Data_TV_Tuner 1;
BA_ "GenSigSendType" SG_ 1747 BAP_Data_TV_Tuner 3;
BA_ "GenSigAutoGenDsp" SG_ 1903 ISO_AMP_Req_Data 1;
BA_ "GenSigAutoGenSnd" SG_ 1903 ISO_AMP_Req_Data 1;
BA_ "GenSigSendType" SG_ 1903 ISO_AMP_Req_Data 3;
BA_ "GenSigAutoGenDsp" SG_ 2009 ISO_AMP_Resp_Data 1;
BA_ "GenSigAutoGenSnd" SG_ 2009 ISO_AMP_Resp_Data 1;
BA_ "GenSigSendType" SG_ 2009 ISO_AMP_Resp_Data 3;
BA_ "GenSigAutoGenDsp" SG_ 1792 ISO_ALL_01_Req_Data 1;
BA_ "GenSigAutoGenSnd" SG_ 1792 ISO_ALL_01_Req_Data 1;
BA_ "GenSigSendType" SG_ 1792 ISO_ALL_01_Req_Data 3;
BA_ "GenSigAutoGenDsp" SG_ 1907 ISO_Info_El_Req_Data 1;
BA_ "GenSigAutoGenSnd" SG_ 1907 ISO_Info_El_Req_Data 1;
BA_ "GenSigSendType" SG_ 1907 ISO_Info_El_Req_Data 3;
BA_ "GenSigAutoGenDsp" SG_ 2013 ISO_Info_El_Resp_Data 1;
BA_ "GenSigAutoGenSnd" SG_ 2013 ISO_Info_El_Resp_Data 1;
BA_ "GenSigSendType" SG_ 2013 ISO_Info_El_Resp_Data 3;
BA_ "GenSigAutoGenDsp" SG_ 1902 ISO_MDI_Req_Data 1;
BA_ "GenSigAutoGenSnd" SG_ 1902 ISO_MDI_Req_Data 1;
BA_ "GenSigSendType" SG_ 1902 ISO_MDI_Req_Data 3;
BA_ "GenSigAutoGenDsp" SG_ 2008 ISO_MDI_Resp_Data 1;
BA_ "GenSigAutoGenSnd" SG_ 2008 ISO_MDI_Resp_Data 1;
BA_ "GenSigSendType" SG_ 2008 ISO_MDI_Resp_Data 3;
BA_ "GenSigAutoGenDsp" SG_ 1900 ISO_Navi_Req_Data 1;
BA_ "GenSigAutoGenSnd" SG_ 1900 ISO_Navi_Req_Data 1;
BA_ "GenSigSendType" SG_ 1900 ISO_Navi_Req_Data 3;
BA_ "GenSigAutoGenDsp" SG_ 2006 ISO_Navi_Resp_Data 1;
BA_ "GenSigAutoGenSnd" SG_ 2006 ISO_Navi_Resp_Data 1;
BA_ "GenSigSendType" SG_ 2006 ISO_Navi_Resp_Data 3;
BA_ "GenSigAutoGenDsp" SG_ 1816 ISO_Radio_Req_Data 1;
BA_ "GenSigAutoGenSnd" SG_ 1816 ISO_Radio_Req_Data 1;
BA_ "GenSigSendType" SG_ 1816 ISO_Radio_Req_Data 3;
BA_ "GenSigAutoGenDsp" SG_ 1922 ISO_Radio_Resp_Data 1;
BA_ "GenSigAutoGenSnd" SG_ 1922 ISO_Radio_Resp_Data 1;
BA_ "GenSigSendType" SG_ 1922 ISO_Radio_Resp_Data 3;
BA_ "GenSigAutoGenDsp" SG_ 1899 ISO_Telefon_Req_Data 1;
BA_ "GenSigAutoGenSnd" SG_ 1899 ISO_Telefon_Req_Data 1;
BA_ "GenSigSendType" SG_ 1899 ISO_Telefon_Req_Data 3;
BA_ "GenSigAutoGenDsp" SG_ 2005 ISO_Telefon_Resp_Data 1;
BA_ "GenSigAutoGenSnd" SG_ 2005 ISO_Telefon_Resp_Data 1;
BA_ "GenSigSendType" SG_ 2005 ISO_Telefon_Resp_Data 3;
BA_ "GenSigAutoGenDsp" SG_ 1901 ISO_TV_Tuner_Req_Data 1;
BA_ "GenSigAutoGenSnd" SG_ 1901 ISO_TV_Tuner_Req_Data 1;
BA_ "GenSigSendType" SG_ 1901 ISO_TV_Tuner_Req_Data 3;
BA_ "GenSigAutoGenDsp" SG_ 2007 ISO_TV_Tuner_Resp_Data 1;
BA_ "GenSigAutoGenSnd" SG_ 2007 ISO_TV_Tuner_Resp_Data 1;
BA_ "GenSigSendType" SG_ 2007 ISO_TV_Tuner_Resp_Data 3;
BA_ "GenSigAutoGenDsp" SG_ 337 AB1_FrontCrash 1;
BA_ "GenSigAutoGenSnd" SG_ 337 AB1_FrontCrash 1;
BA_ "GenSigSendType" SG_ 337 AB1_FrontCrash 3;
BA_ "GenSigSwitchedByIgnition" SG_ 337 AB1_FrontCrash 1;
BA_ "GenSigAutoGenDsp" SG_ 337 AB1_HeckCrash 1;
BA_ "GenSigAutoGenSnd" SG_ 337 AB1_HeckCrash 1;
BA_ "GenSigSendType" SG_ 337 AB1_HeckCrash 3;
BA_ "GenSigSwitchedByIgnition" SG_ 337 AB1_HeckCrash 1;
BA_ "GenSigAutoGenDsp" SG_ 337 AB1_Crash_FT 1;
BA_ "GenSigAutoGenSnd" SG_ 337 AB1_Crash_FT 1;
BA_ "GenSigSendType" SG_ 337 AB1_Crash_FT 3;
BA_ "GenSigSwitchedByIgnition" SG_ 337 AB1_Crash_FT 1;
BA_ "GenSigAutoGenDsp" SG_ 337 AB1_Crash_BT 1;
BA_ "GenSigAutoGenSnd" SG_ 337 AB1_Crash_BT 1;
BA_ "GenSigSendType" SG_ 337 AB1_Crash_BT 3;
BA_ "GenSigSwitchedByIgnition" SG_ 337 AB1_Crash_BT 1;
BA_ "GenSigAutoGenDsp" SG_ 337 AB1_Rollover 1;
BA_ "GenSigAutoGenSnd" SG_ 337 AB1_Rollover 1;
BA_ "GenSigSendType" SG_ 337 AB1_Rollover 3;
BA_ "GenSigSwitchedByIgnition" SG_ 337 AB1_Rollover 1;
BA_ "GenSigAutoGenDsp" SG_ 337 AB1_CrashStaerke 1;
BA_ "GenSigAutoGenSnd" SG_ 337 AB1_CrashStaerke 1;
BA_ "GenSigSendType" SG_ 337 AB1_CrashStaerke 5;
BA_ "GenSigSwitchedByIgnition" SG_ 337 AB1_CrashStaerke 1;
BA_ "GenSigAutoGenDsp" SG_ 337 AB1_AirbagLampe_ein 1;
BA_ "GenSigAutoGenSnd" SG_ 337 AB1_AirbagLampe_ein 1;
BA_ "GenSigSendType" SG_ 337 AB1_AirbagLampe_ein 0;
BA_ "GenSigStartValue" SG_ 337 AB1_AirbagLampe_ein 1;
BA_ "GenSigSwitchedByIgnition" SG_ 337 AB1_AirbagLampe_ein 1;
BA_ "GenSigAutoGenDsp" SG_ 337 AB1_Airbag_deaktiviert 1;
BA_ "GenSigAutoGenSnd" SG_ 337 AB1_Airbag_deaktiviert 1;
BA_ "GenSigSendType" SG_ 337 AB1_Airbag_deaktiviert 0;
BA_ "GenSigSwitchedByIgnition" SG_ 337 AB1_Airbag_deaktiviert 1;
BA_ "GenSigAutoGenDsp" SG_ 337 AB1_Beif_Airbag_deaktiviert 1;
BA_ "GenSigAutoGenSnd" SG_ 337 AB1_Beif_Airbag_deaktiviert 1;
BA_ "GenSigSendType" SG_ 337 AB1_Beif_Airbag_deaktiviert 0;
BA_ "GenSigStartValue" SG_ 337 AB1_Beif_Airbag_deaktiviert 1;
BA_ "GenSigSwitchedByIgnition" SG_ 337 AB1_Beif_Airbag_deaktiviert 1;
BA_ "GenSigAutoGenDsp" SG_ 337 AB1_Systemfehler 1;
BA_ "GenSigAutoGenSnd" SG_ 337 AB1_Systemfehler 1;
BA_ "GenSigSendType" SG_ 337 AB1_Systemfehler 0;
BA_ "GenSigSwitchedByIgnition" SG_ 337 AB1_Systemfehler 1;
BA_ "GenSigAutoGenDsp" SG_ 337 AB1_Fa_Gurt 1;
BA_ "GenSigAutoGenSnd" SG_ 337 AB1_Fa_Gurt 1;
BA_ "GenSigSendType" SG_ 337 AB1_Fa_Gurt 0;
BA_ "GenSigSwitchedByIgnition" SG_ 337 AB1_Fa_Gurt 1;
BA_ "Fehlerwert" SG_ 337 AB1_Fa_Gurt 1;
BA_ "GenSigAutoGenDsp" SG_ 337 AB1_Bf_Gurt 1;
BA_ "GenSigAutoGenSnd" SG_ 337 AB1_Bf_Gurt 1;
BA_ "GenSigSendType" SG_ 337 AB1_Bf_Gurt 0;
BA_ "GenSigSwitchedByIgnition" SG_ 337 AB1_Bf_Gurt 1;
BA_ "Fehlerwert" SG_ 337 AB1_Bf_Gurt 1;
BA_ "GenSigAutoGenDsp" SG_ 337 AB1_Diagnose 1;
BA_ "GenSigAutoGenSnd" SG_ 337 AB1_Diagnose 1;
BA_ "GenSigSendType" SG_ 337 AB1_Diagnose 0;
BA_ "GenSigSwitchedByIgnition" SG_ 337 AB1_Diagnose 1;
BA_ "GenSigAutoGenDsp" SG_ 337 AB1_Stellglied 1;
BA_ "GenSigAutoGenSnd" SG_ 337 AB1_Stellglied 1;
BA_ "GenSigSendType" SG_ 337 AB1_Stellglied 0;
BA_ "GenSigSwitchedByIgnition" SG_ 337 AB1_Stellglied 1;
BA_ "GenSigAutoGenDsp" SG_ 337 AB1_BF_Anschnall 1;
BA_ "GenSigAutoGenSnd" SG_ 337 AB1_BF_Anschnall 1;
BA_ "GenSigSendType" SG_ 337 AB1_BF_Anschnall 0;
BA_ "GenSigSwitchedByIgnition" SG_ 337 AB1_BF_Anschnall 1;
BA_ "GenSigAutoGenDsp" SG_ 337 AB1_KD_Fehler 1;
BA_ "GenSigAutoGenSnd" SG_ 337 AB1_KD_Fehler 1;
BA_ "GenSigSendType" SG_ 337 AB1_KD_Fehler 0;
BA_ "GenSigSwitchedByIgnition" SG_ 337 AB1_KD_Fehler 1;
BA_ "GenSigAutoGenDsp" SG_ 337 AB1_MessageZaehler 1;
BA_ "GenSigAutoGenSnd" SG_ 337 AB1_MessageZaehler 1;
BA_ "GenSigSendType" SG_ 337 AB1_MessageZaehler 0;
BA_ "GenSigFuncType" SG_ 337 AB1_MessageZaehler 1;
BA_ "GenSigSwitchedByIgnition" SG_ 337 AB1_MessageZaehler 1;
BA_ "GenSigAutoGenDsp" SG_ 337 AB1_Pruefsumme 1;
BA_ "GenSigAutoGenSnd" SG_ 337 AB1_Pruefsumme 1;
BA_ "GenSigSendType" SG_ 337 AB1_Pruefsumme 0;
BA_ "GenSigFuncType" SG_ 337 AB1_Pruefsumme 4;
BA_ "GenSigSwitchedByIgnition" SG_ 337 AB1_Pruefsumme 1;
BA_ "GenSigAutoGenDsp" SG_ 1429 AG1_BL_def 1;
BA_ "GenSigAutoGenSnd" SG_ 1429 AG1_BL_def 1;
BA_ "GenSigSendType" SG_ 1429 AG1_BL_def 3;
BA_ "GenSigAutoGenDsp" SG_ 1429 AG1_NSL_def 1;
BA_ "GenSigAutoGenSnd" SG_ 1429 AG1_NSL_def 1;
BA_ "GenSigSendType" SG_ 1429 AG1_NSL_def 3;
BA_ "GenSigAutoGenDsp" SG_ 1429 AG1_RFL_def 1;
BA_ "GenSigAutoGenSnd" SG_ 1429 AG1_RFL_def 1;
BA_ "GenSigSendType" SG_ 1429 AG1_RFL_def 3;
BA_ "GenSigAutoGenDsp" SG_ 1429 AG1_KD_Fehler 1;
BA_ "GenSigAutoGenSnd" SG_ 1429 AG1_KD_Fehler 1;
BA_ "GenSigSendType" SG_ 1429 AG1_KD_Fehler 3;
BA_ "GenSigAutoGenDsp" SG_ 1429 AG1_Blk_ein 1;
BA_ "GenSigAutoGenSnd" SG_ 1429 AG1_Blk_ein 1;
BA_ "GenSigSendType" SG_ 1429 AG1_Blk_ein 3;
BA_ "GenSigAutoGenDsp" SG_ 1429 AG1_Kl_54_def 1;
BA_ "GenSigAutoGenSnd" SG_ 1429 AG1_Kl_54_def 1;
BA_ "GenSigSendType" SG_ 1429 AG1_Kl_54_def 3;
BA_ "GenSigAutoGenDsp" SG_ 1429 AG1_ANH_Alarm 1;
BA_ "GenSigAutoGenSnd" SG_ 1429 AG1_ANH_Alarm 1;
BA_ "GenSigSendType" SG_ 1429 AG1_ANH_Alarm 3;
BA_ "GenSigAutoGenDsp" SG_ 1429 AG1_ANH_Erk 1;
BA_ "GenSigAutoGenSnd" SG_ 1429 AG1_ANH_Erk 1;
BA_ "GenSigSendType" SG_ 1429 AG1_ANH_Erk 3;
BA_ "GenSigAutoGenDsp" SG_ 1429 AG1_Typ 1;
BA_ "GenSigAutoGenSnd" SG_ 1429 AG1_Typ 1;
BA_ "GenSigSendType" SG_ 1429 AG1_Typ 3;
BA_ "GenSigAutoGenDsp" SG_ 1429 AG1_Blinker_r_def 1;
BA_ "GenSigAutoGenSnd" SG_ 1429 AG1_Blinker_r_def 1;
BA_ "GenSigSendType" SG_ 1429 AG1_Blinker_r_def 3;
BA_ "GenSigAutoGenDsp" SG_ 1429 AG1_Licht_r_def 1;
BA_ "GenSigAutoGenSnd" SG_ 1429 AG1_Licht_r_def 1;
BA_ "GenSigSendType" SG_ 1429 AG1_Licht_r_def 3;
BA_ "GenSigAutoGenDsp" SG_ 1429 AG1_NBA_ready 1;
BA_ "GenSigAutoGenSnd" SG_ 1429 AG1_NBA_ready 1;
BA_ "GenSigSendType" SG_ 1429 AG1_NBA_ready 3;
BA_ "GenSigAutoGenDsp" SG_ 1429 AG1_Blinker_l_def 1;
BA_ "GenSigAutoGenSnd" SG_ 1429 AG1_Blinker_l_def 1;
BA_ "GenSigSendType" SG_ 1429 AG1_Blinker_l_def 3;
BA_ "GenSigAutoGenDsp" SG_ 1429 AG1_Licht_l_def 1;
BA_ "GenSigAutoGenSnd" SG_ 1429 AG1_Licht_l_def 1;
BA_ "GenSigSendType" SG_ 1429 AG1_Licht_l_def 3;
BA_ "GenSigAutoGenDsp" SG_ 1429 AG1_AVS_Warnung 1;
BA_ "GenSigAutoGenSnd" SG_ 1429 AG1_AVS_Warnung 1;
BA_ "GenSigSendType" SG_ 1429 AG1_AVS_Warnung 3;
BA_ "GenSigAutoGenDsp" SG_ 1429 AG1_AVS_Status 1;
BA_ "GenSigAutoGenSnd" SG_ 1429 AG1_AVS_Status 1;
BA_ "GenSigSendType" SG_ 1429 AG1_AVS_Status 3;
BA_ "GenSigStartValue" SG_ 1429 AG1_AVS_Status 32;
BA_ "GenSigAutoGenDsp" SG_ 1624 BEM_02_Abschaltstufen 1;
BA_ "GenSigAutoGenSnd" SG_ 1624 BEM_02_Abschaltstufen 1;
BA_ "GenSigSendType" SG_ 1624 BEM_02_Abschaltstufen 0;
BA_ "GenSigAutoGenDsp" SG_ 1624 BEM_STH_Zielzeit 1;
BA_ "GenSigAutoGenSnd" SG_ 1624 BEM_STH_Zielzeit 1;
BA_ "GenSigSendType" SG_ 1624 BEM_STH_Zielzeit 0;
BA_ "GenSigStartValue" SG_ 1624 BEM_STH_Zielzeit 14;
BA_ "Fehlerwert" SG_ 1624 BEM_STH_Zielzeit 15;
BA_ "GenSigAutoGenDsp" SG_ 1624 BEM_MMI_Vorwarnung 1;
BA_ "GenSigAutoGenSnd" SG_ 1624 BEM_MMI_Vorwarnung 1;
BA_ "GenSigSendType" SG_ 1624 BEM_MMI_Vorwarnung 0;
BA_ "GenSigAutoGenDsp" SG_ 1624 BEM_HL_Kontingentierung 1;
BA_ "GenSigAutoGenSnd" SG_ 1624 BEM_HL_Kontingentierung 1;
BA_ "GenSigSendType" SG_ 1624 BEM_HL_Kontingentierung 0;
BA_ "GenSigAutoGenDsp" SG_ 1624 BEM_Generatordiagnose 1;
BA_ "GenSigAutoGenSnd" SG_ 1624 BEM_Generatordiagnose 1;
BA_ "GenSigSendType" SG_ 1624 BEM_Generatordiagnose 0;
BA_ "GenSigAutoGenDsp" SG_ 1624 BEM_Red_Innengeblaese 1;
BA_ "GenSigAutoGenSnd" SG_ 1624 BEM_Red_Innengeblaese 1;
BA_ "GenSigSendType" SG_ 1624 BEM_Red_Innengeblaese 0;
BA_ "GenSigAutoGenDsp" SG_ 1624 BEM_STH_Einschaltverbot 1;
BA_ "GenSigAutoGenSnd" SG_ 1624 BEM_STH_Einschaltverbot 1;
BA_ "GenSigSendType" SG_ 1624 BEM_STH_Einschaltverbot 0;
BA_ "GenSigAutoGenDsp" SG_ 1624 BEM_HL_Regelung_Status 1;
BA_ "GenSigAutoGenSnd" SG_ 1624 BEM_HL_Regelung_Status 1;
BA_ "GenSigSendType" SG_ 1624 BEM_HL_Regelung_Status 0;
BA_ "GenSigAutoGenDsp" SG_ 1624 BEM_Ladezustand 1;
BA_ "GenSigAutoGenSnd" SG_ 1624 BEM_Ladezustand 1;
BA_ "GenSigSendType" SG_ 1624 BEM_Ladezustand 0;
BA_ "GenSigStartValue" SG_ 1624 BEM_Ladezustand 14;
BA_ "Fehlerwert" SG_ 1624 BEM_Ladezustand 15;
BA_ "GenSigAutoGenDsp" SG_ 1624 BEM_Batteriediagnose 1;
BA_ "GenSigAutoGenSnd" SG_ 1624 BEM_Batteriediagnose 1;
BA_ "GenSigSendType" SG_ 1624 BEM_Batteriediagnose 0;
BA_ "GenSigAutoGenDsp" SG_ 1624 BEM_DFM 1;
BA_ "GenSigAutoGenSnd" SG_ 1624 BEM_DFM 1;
BA_ "GenSigSendType" SG_ 1624 BEM_DFM 0;
BA_ "GenSigAutoGenDsp" SG_ 1624 BEM_REK_aktiv 1;
BA_ "GenSigAutoGenSnd" SG_ 1624 BEM_REK_aktiv 1;
BA_ "GenSigSendType" SG_ 1624 BEM_REK_aktiv 0;
BA_ "GenSigAutoGenDsp" SG_ 1624 BEM_EMLIN_ungueltig 1;
BA_ "GenSigAutoGenSnd" SG_ 1624 BEM_EMLIN_ungueltig 1;
BA_ "GenSigSendType" SG_ 1624 BEM_EMLIN_ungueltig 0;
BA_ "GenSigStartValue" SG_ 1624 BEM_EMLIN_ungueltig 1;
BA_ "GenSigAutoGenDsp" SG_ 1624 BEM_Batt_Ab 1;
BA_ "GenSigAutoGenSnd" SG_ 1624 BEM_Batt_Ab 1;
BA_ "GenSigSendType" SG_ 1624 BEM_Batt_Ab 0;
BA_ "GenSigAutoGenDsp" SG_ 1624 BEM_UBDM 1;
BA_ "GenSigAutoGenSnd" SG_ 1624 BEM_UBDM 1;
BA_ "GenSigSendType" SG_ 1624 BEM_UBDM 0;
BA_ "GenSigAutoGenDsp" SG_ 1624 BEM_UGenSoll 1;
BA_ "GenSigAutoGenSnd" SG_ 1624 BEM_UGenSoll 1;
BA_ "GenSigSendType" SG_ 1624 BEM_UGenSoll 0;
BA_ "Fehlerwert" SG_ 1624 BEM_UGenSoll 63;
BA_ "GenSigAutoGenDsp" SG_ 1461 B10_Checksumme 1;
BA_ "GenSigAutoGenSnd" SG_ 1461 B10_Checksumme 1;
BA_ "GenSigSendType" SG_ 1461 B10_Checksumme 0;
BA_ "GenSigFuncType" SG_ 1461 B10_Checksumme 4;
BA_ "GenSigAutoGenDsp" SG_ 1461 B10_Zaehler 1;
BA_ "GenSigAutoGenSnd" SG_ 1461 B10_Zaehler 1;
BA_ "GenSigSendType" SG_ 1461 B10_Zaehler 0;
BA_ "GenSigFuncType" SG_ 1461 B10_Zaehler 1;
BA_ "GenSigAutoGenDsp" SG_ 1461 B10_QB_Wegimp_VL 1;
BA_ "GenSigAutoGenSnd" SG_ 1461 B10_QB_Wegimp_VL 1;
BA_ "GenSigSendType" SG_ 1461 B10_QB_Wegimp_VL 0;
BA_ "GenSigStartValue" SG_ 1461 B10_QB_Wegimp_VL 1;
BA_ "GenSigAutoGenDsp" SG_ 1461 B10_QB_Wegimp_VR 1;
BA_ "GenSigAutoGenSnd" SG_ 1461 B10_QB_Wegimp_VR 1;
BA_ "GenSigSendType" SG_ 1461 B10_QB_Wegimp_VR 0;
BA_ "GenSigStartValue" SG_ 1461 B10_QB_Wegimp_VR 1;
BA_ "GenSigAutoGenDsp" SG_ 1461 B10_QB_Wegimp_HL 1;
BA_ "GenSigAutoGenSnd" SG_ 1461 B10_QB_Wegimp_HL 1;
BA_ "GenSigSendType" SG_ 1461 B10_QB_Wegimp_HL 0;
BA_ "GenSigStartValue" SG_ 1461 B10_QB_Wegimp_HL 1;
BA_ "GenSigAutoGenDsp" SG_ 1461 B10_QB_Wegimp_HR 1;
BA_ "GenSigAutoGenSnd" SG_ 1461 B10_QB_Wegimp_HR 1;
BA_ "GenSigSendType" SG_ 1461 B10_QB_Wegimp_HR 0;
BA_ "GenSigStartValue" SG_ 1461 B10_QB_Wegimp_HR 1;
BA_ "GenSigAutoGenDsp" SG_ 1461 B10_Wegimp_VL 1;
BA_ "GenSigAutoGenSnd" SG_ 1461 B10_Wegimp_VL 1;
BA_ "GenSigSendType" SG_ 1461 B10_Wegimp_VL 0;
BA_ "GenSigStartValue" SG_ 1461 B10_Wegimp_VL 1021;
BA_ "GenSigAutoGenDsp" SG_ 1461 B10_Wegimp_VR 1;
BA_ "GenSigAutoGenSnd" SG_ 1461 B10_Wegimp_VR 1;
BA_ "GenSigSendType" SG_ 1461 B10_Wegimp_VR 0;
BA_ "GenSigStartValue" SG_ 1461 B10_Wegimp_VR 1021;
BA_ "GenSigAutoGenDsp" SG_ 1461 B10_Wegimp_HL 1;
BA_ "GenSigAutoGenSnd" SG_ 1461 B10_Wegimp_HL 1;
BA_ "GenSigSendType" SG_ 1461 B10_Wegimp_HL 0;
BA_ "GenSigStartValue" SG_ 1461 B10_Wegimp_HL 1021;
BA_ "GenSigAutoGenDsp" SG_ 1461 B10_Wegimp_HR 1;
BA_ "GenSigAutoGenSnd" SG_ 1461 B10_Wegimp_HR 1;
BA_ "GenSigSendType" SG_ 1461 B10_Wegimp_HR 0;
BA_ "GenSigStartValue" SG_ 1461 B10_Wegimp_HR 1021;
BA_ "GenSigAutoGenDsp" SG_ 1461 B10_QB_Fahrtr_VL 1;
BA_ "GenSigAutoGenSnd" SG_ 1461 B10_QB_Fahrtr_VL 1;
BA_ "GenSigSendType" SG_ 1461 B10_QB_Fahrtr_VL 0;
BA_ "GenSigStartValue" SG_ 1461 B10_QB_Fahrtr_VL 1;
BA_ "GenSigAutoGenDsp" SG_ 1461 B10_QB_Fahrtr_VR 1;
BA_ "GenSigAutoGenSnd" SG_ 1461 B10_QB_Fahrtr_VR 1;
BA_ "GenSigSendType" SG_ 1461 B10_QB_Fahrtr_VR 0;
BA_ "GenSigStartValue" SG_ 1461 B10_QB_Fahrtr_VR 1;
BA_ "GenSigAutoGenDsp" SG_ 1461 B10_QB_Fahrtr_HL 1;
BA_ "GenSigAutoGenSnd" SG_ 1461 B10_QB_Fahrtr_HL 1;
BA_ "GenSigSendType" SG_ 1461 B10_QB_Fahrtr_HL 0;
BA_ "GenSigStartValue" SG_ 1461 B10_QB_Fahrtr_HL 1;
BA_ "GenSigAutoGenDsp" SG_ 1461 B10_QB_Fahrtr_HR 1;
BA_ "GenSigAutoGenSnd" SG_ 1461 B10_QB_Fahrtr_HR 1;
BA_ "GenSigSendType" SG_ 1461 B10_QB_Fahrtr_HR 0;
BA_ "GenSigStartValue" SG_ 1461 B10_QB_Fahrtr_HR 1;
BA_ "GenSigAutoGenDsp" SG_ 1461 B10_Fahrtr_VL 1;
BA_ "GenSigAutoGenSnd" SG_ 1461 B10_Fahrtr_VL 1;
BA_ "GenSigSendType" SG_ 1461 B10_Fahrtr_VL 0;
BA_ "GenSigAutoGenDsp" SG_ 1461 B10_Fahrtr_VR 1;
BA_ "GenSigAutoGenSnd" SG_ 1461 B10_Fahrtr_VR 1;
BA_ "GenSigSendType" SG_ 1461 B10_Fahrtr_VR 0;
BA_ "GenSigAutoGenDsp" SG_ 1461 B10_Fahrtr_HL 1;
BA_ "GenSigAutoGenSnd" SG_ 1461 B10_Fahrtr_HL 1;
BA_ "GenSigSendType" SG_ 1461 B10_Fahrtr_HL 0;
BA_ "GenSigAutoGenDsp" SG_ 1461 B10_Fahrtr_HR 1;
BA_ "GenSigAutoGenSnd" SG_ 1461 B10_Fahrtr_HR 1;
BA_ "GenSigSendType" SG_ 1461 B10_Fahrtr_HR 0;
BA_ "GenSigAutoGenDsp" SG_ 1393 BS2_U_BATT 1;
BA_ "GenSigAutoGenSnd" SG_ 1393 BS2_U_BATT 1;
BA_ "GenSigSendType" SG_ 1393 BS2_U_BATT 0;
BA_ "Fehlerwert" SG_ 1393 BS2_U_BATT 255;
BA_ "GenSigAutoGenDsp" SG_ 1393 BS2_Heckscheibe_aus 1;
BA_ "GenSigAutoGenSnd" SG_ 1393 BS2_Heckscheibe_aus 1;
BA_ "GenSigSendType" SG_ 1393 BS2_Heckscheibe_aus 0;
BA_ "GenSigAutoGenDsp" SG_ 1393 BS2_Frontscheibe_aus 1;
BA_ "GenSigAutoGenSnd" SG_ 1393 BS2_Frontscheibe_aus 1;
BA_ "GenSigSendType" SG_ 1393 BS2_Frontscheibe_aus 0;
BA_ "GenSigAutoGenDsp" SG_ 1393 BS2_Aussenspiegel_aus 1;
BA_ "GenSigAutoGenSnd" SG_ 1393 BS2_Aussenspiegel_aus 1;
BA_ "GenSigSendType" SG_ 1393 BS2_Aussenspiegel_aus 0;
BA_ "GenSigAutoGenDsp" SG_ 1393 BS2_Sitzheizung_aus 1;
BA_ "GenSigAutoGenSnd" SG_ 1393 BS2_Sitzheizung_aus 1;
BA_ "GenSigSendType" SG_ 1393 BS2_Sitzheizung_aus 0;
BA_ "GenSigAutoGenDsp" SG_ 1393 BS2_aus_Lenkradheizung 1;
BA_ "GenSigAutoGenSnd" SG_ 1393 BS2_aus_Lenkradheizung 1;
BA_ "GenSigSendType" SG_ 1393 BS2_aus_Lenkradheizung 0;
BA_ "GenSigAutoGenDsp" SG_ 1393 BS2_aus_Wischwasserhzg 1;
BA_ "GenSigAutoGenSnd" SG_ 1393 BS2_aus_Wischwasserhzg 1;
BA_ "GenSigSendType" SG_ 1393 BS2_aus_Wischwasserhzg 0;
BA_ "GenSigAutoGenDsp" SG_ 1393 BS2_aus_Sitzlueftung 1;
BA_ "GenSigAutoGenSnd" SG_ 1393 BS2_aus_Sitzlueftung 1;
BA_ "GenSigSendType" SG_ 1393 BS2_aus_Sitzlueftung 0;
BA_ "GenSigAutoGenDsp" SG_ 1393 BS2_Klimaanlage_aus 1;
BA_ "GenSigAutoGenSnd" SG_ 1393 BS2_Klimaanlage_aus 1;
BA_ "GenSigSendType" SG_ 1393 BS2_Klimaanlage_aus 0;
BA_ "GenSigAutoGenDsp" SG_ 1393 BS2_U_Start_BATT 1;
BA_ "GenSigAutoGenSnd" SG_ 1393 BS2_U_Start_BATT 1;
BA_ "GenSigSendType" SG_ 1393 BS2_U_Start_BATT 0;
BA_ "GenSigAutoGenDsp" SG_ 1393 BS2_Lastman_aktiv 1;
BA_ "GenSigAutoGenSnd" SG_ 1393 BS2_Lastman_aktiv 1;
BA_ "GenSigSendType" SG_ 1393 BS2_Lastman_aktiv 0;
BA_ "GenSigAutoGenDsp" SG_ 1393 BS2_Verbr_ab_aktiv 1;
BA_ "GenSigAutoGenSnd" SG_ 1393 BS2_Verbr_ab_aktiv 1;
BA_ "GenSigSendType" SG_ 1393 BS2_Verbr_ab_aktiv 0;
BA_ "GenSigAutoGenDsp" SG_ 1393 BS2_Notstart 1;
BA_ "GenSigAutoGenSnd" SG_ 1393 BS2_Notstart 1;
BA_ "GenSigSendType" SG_ 1393 BS2_Notstart 0;
BA_ "GenSigAutoGenDsp" SG_ 1393 BS2_aus_Sitzhzg_H 1;
BA_ "GenSigAutoGenSnd" SG_ 1393 BS2_aus_Sitzhzg_H 1;
BA_ "GenSigSendType" SG_ 1393 BS2_aus_Sitzhzg_H 0;
BA_ "GenSigAutoGenDsp" SG_ 1393 BS2_aus_Steckdosen 1;
BA_ "GenSigAutoGenSnd" SG_ 1393 BS2_aus_Steckdosen 1;
BA_ "GenSigSendType" SG_ 1393 BS2_aus_Steckdosen 0;
BA_ "GenSigAutoGenDsp" SG_ 1393 BS2_aus_Zusatz_Verbr 1;
BA_ "GenSigAutoGenSnd" SG_ 1393 BS2_aus_Zusatz_Verbr 1;
BA_ "GenSigSendType" SG_ 1393 BS2_aus_Zusatz_Verbr 0;
BA_ "GenSigAutoGenDsp" SG_ 1393 BS2_aus_Infotainment 1;
BA_ "GenSigAutoGenSnd" SG_ 1393 BS2_aus_Infotainment 1;
BA_ "GenSigSendType" SG_ 1393 BS2_aus_Infotainment 0;
BA_ "GenSigAutoGenDsp" SG_ 1393 BS2_Wake_Up_ACAN 1;
BA_ "GenSigAutoGenSnd" SG_ 1393 BS2_Wake_Up_ACAN 1;
BA_ "GenSigSendType" SG_ 1393 BS2_Wake_Up_ACAN 0;
BA_ "GenSigAutoGenDsp" SG_ 1393 BS2_aus_PTC_Clima 1;
BA_ "GenSigAutoGenSnd" SG_ 1393 BS2_aus_PTC_Clima 1;
BA_ "GenSigSendType" SG_ 1393 BS2_aus_PTC_Clima 0;
BA_ "GenSigAutoGenDsp" SG_ 1393 BS2_KlimaLeistRed 1;
BA_ "GenSigAutoGenSnd" SG_ 1393 BS2_KlimaLeistRed 1;
BA_ "GenSigSendType" SG_ 1393 BS2_KlimaLeistRed 0;
BA_ "GenSigAutoGenDsp" SG_ 1393 BS2_red_Heckscheibe 1;
BA_ "GenSigAutoGenSnd" SG_ 1393 BS2_red_Heckscheibe 1;
BA_ "GenSigSendType" SG_ 1393 BS2_red_Heckscheibe 0;
BA_ "GenSigAutoGenDsp" SG_ 1393 BS2_aus_Ablage_Wischer 1;
BA_ "GenSigAutoGenSnd" SG_ 1393 BS2_aus_Ablage_Wischer 1;
BA_ "GenSigSendType" SG_ 1393 BS2_aus_Ablage_Wischer 0;
BA_ "GenSigAutoGenDsp" SG_ 1393 BS2_aus_Innen_Bel 1;
BA_ "GenSigAutoGenSnd" SG_ 1393 BS2_aus_Innen_Bel 1;
BA_ "GenSigSendType" SG_ 1393 BS2_aus_Innen_Bel 0;
BA_ "GenSigAutoGenDsp" SG_ 1393 BS2_Warn_Steckdosen 1;
BA_ "GenSigAutoGenSnd" SG_ 1393 BS2_Warn_Steckdosen 1;
BA_ "GenSigSendType" SG_ 1393 BS2_Warn_Steckdosen 0;
BA_ "GenSigAutoGenDsp" SG_ 1393 BS2_Warn_Infotainment 1;
BA_ "GenSigAutoGenSnd" SG_ 1393 BS2_Warn_Infotainment 1;
BA_ "GenSigSendType" SG_ 1393 BS2_Warn_Infotainment 0;
BA_ "GenSigAutoGenDsp" SG_ 1393 BS2_Warn_Zusatz 1;
BA_ "GenSigAutoGenSnd" SG_ 1393 BS2_Warn_Zusatz 1;
BA_ "GenSigSendType" SG_ 1393 BS2_Warn_Zusatz 0;
BA_ "GenSigAutoGenDsp" SG_ 1393 BS2_Weckursache_ACAN 1;
BA_ "GenSigAutoGenSnd" SG_ 1393 BS2_Weckursache_ACAN 1;
BA_ "GenSigSendType" SG_ 1393 BS2_Weckursache_ACAN 0;
BA_ "GenSigAutoGenDsp" SG_ 1393 BS2_VB_2_Battarie 1;
BA_ "GenSigAutoGenSnd" SG_ 1393 BS2_VB_2_Battarie 1;
BA_ "GenSigSendType" SG_ 1393 BS2_VB_2_Battarie 0;
BA_ "GenSigAutoGenDsp" SG_ 1393 BS2_Zust_Start_Ltg 1;
BA_ "GenSigAutoGenSnd" SG_ 1393 BS2_Zust_Start_Ltg 1;
BA_ "GenSigSendType" SG_ 1393 BS2_Zust_Start_Ltg 0;
BA_ "GenSigAutoGenDsp" SG_ 1393 BS2_Mess_Start_Ltg 1;
BA_ "GenSigAutoGenSnd" SG_ 1393 BS2_Mess_Start_Ltg 1;
BA_ "GenSigSendType" SG_ 1393 BS2_Mess_Start_Ltg 0;
BA_ "GenSigAutoGenDsp" SG_ 1397 BS3_Klemme_S 1;
BA_ "GenSigAutoGenSnd" SG_ 1397 BS3_Klemme_S 1;
BA_ "GenSigSendType" SG_ 1397 BS3_Klemme_S 3;
BA_ "GenSigAutoGenDsp" SG_ 1397 BS3_Klemme_15 1;
BA_ "GenSigAutoGenSnd" SG_ 1397 BS3_Klemme_15 1;
BA_ "GenSigSendType" SG_ 1397 BS3_Klemme_15 3;
BA_ "GenSigFuncType" SG_ 1397 BS3_Klemme_15 6;
BA_ "GenSigAutoGenDsp" SG_ 1397 BS3_Klemme_X 1;
BA_ "GenSigAutoGenSnd" SG_ 1397 BS3_Klemme_X 1;
BA_ "GenSigSendType" SG_ 1397 BS3_Klemme_X 3;
BA_ "GenSigAutoGenDsp" SG_ 1397 BS3_Klemme_50 1;
BA_ "GenSigAutoGenSnd" SG_ 1397 BS3_Klemme_50 1;
BA_ "GenSigSendType" SG_ 1397 BS3_Klemme_50 3;
BA_ "GenSigAutoGenDsp" SG_ 1397 BS3_Klemme_P 1;
BA_ "GenSigAutoGenSnd" SG_ 1397 BS3_Klemme_P 1;
BA_ "GenSigSendType" SG_ 1397 BS3_Klemme_P 3;
BA_ "GenSigAutoGenDsp" SG_ 1397 BS3_2_Drehzahl 1;
BA_ "GenSigAutoGenSnd" SG_ 1397 BS3_2_Drehzahl 1;
BA_ "GenSigSendType" SG_ 1397 BS3_2_Drehzahl 3;
BA_ "GenSigAutoGenDsp" SG_ 1397 BS3_Klemme_15_Motorraum 1;
BA_ "GenSigAutoGenSnd" SG_ 1397 BS3_Klemme_15_Motorraum 1;
BA_ "GenSigSendType" SG_ 1397 BS3_Klemme_15_Motorraum 3;
BA_ "GenSigAutoGenDsp" SG_ 1397 BS3_Ladekontrollampe 1;
BA_ "GenSigAutoGenSnd" SG_ 1397 BS3_Ladekontrollampe 1;
BA_ "GenSigSendType" SG_ 1397 BS3_Ladekontrollampe 3;
BA_ "GenSigAutoGenDsp" SG_ 1397 BS3_Drehzahlanhebung 1;
BA_ "GenSigAutoGenSnd" SG_ 1397 BS3_Drehzahlanhebung 1;
BA_ "GenSigSendType" SG_ 1397 BS3_Drehzahlanhebung 3;
BA_ "GenSigAutoGenDsp" SG_ 1397 BS3_Bordnetzbatt 1;
BA_ "GenSigAutoGenSnd" SG_ 1397 BS3_Bordnetzbatt 1;
BA_ "GenSigSendType" SG_ 1397 BS3_Bordnetzbatt 3;
BA_ "Fehlerwert" SG_ 1397 BS3_Bordnetzbatt 3;
BA_ "GenSigAutoGenDsp" SG_ 1397 BS3_Starterbatt 1;
BA_ "GenSigAutoGenSnd" SG_ 1397 BS3_Starterbatt 1;
BA_ "GenSigSendType" SG_ 1397 BS3_Starterbatt 3;
BA_ "Fehlerwert" SG_ 1397 BS3_Starterbatt 3;
BA_ "GenSigAutoGenDsp" SG_ 1397 BS3_KD_Fehler 1;
BA_ "GenSigAutoGenSnd" SG_ 1397 BS3_KD_Fehler 1;
BA_ "GenSigSendType" SG_ 1397 BS3_KD_Fehler 3;
BA_ "Fehlerwert" SG_ 1397 BS3_KD_Fehler 1;
BA_ "GenSigAutoGenDsp" SG_ 1397 BS3_LWR_Fehler 1;
BA_ "GenSigAutoGenSnd" SG_ 1397 BS3_LWR_Fehler 1;
BA_ "GenSigSendType" SG_ 1397 BS3_LWR_Fehler 3;
BA_ "GenSigAutoGenDsp" SG_ 1397 BS3_Haubenkontakt 1;
BA_ "GenSigAutoGenSnd" SG_ 1397 BS3_Haubenkontakt 1;
BA_ "GenSigSendType" SG_ 1397 BS3_Haubenkontakt 3;
BA_ "GenSigAutoGenDsp" SG_ 1397 BS3_Coming_Home 1;
BA_ "GenSigAutoGenSnd" SG_ 1397 BS3_Coming_Home 1;
BA_ "GenSigSendType" SG_ 1397 BS3_Coming_Home 3;
BA_ "GenSigAutoGenDsp" SG_ 1397 BS3_Leaving_Home 1;
BA_ "GenSigAutoGenSnd" SG_ 1397 BS3_Leaving_Home 1;
BA_ "GenSigSendType" SG_ 1397 BS3_Leaving_Home 3;
BA_ "GenSigAutoGenDsp" SG_ 1397 BS3_K_Luefter_ein 1;
BA_ "GenSigAutoGenSnd" SG_ 1397 BS3_K_Luefter_ein 1;
BA_ "GenSigSendType" SG_ 1397 BS3_K_Luefter_ein 3;
BA_ "GenSigAutoGenDsp" SG_ 1397 BS3_Ab_Batterie 1;
BA_ "GenSigAutoGenSnd" SG_ 1397 BS3_Ab_Batterie 1;
BA_ "GenSigSendType" SG_ 1397 BS3_Ab_Batterie 3;
BA_ "GenSigAutoGenDsp" SG_ 1397 BS3_VP_Taste 1;
BA_ "GenSigAutoGenSnd" SG_ 1397 BS3_VP_Taste 1;
BA_ "GenSigSendType" SG_ 1397 BS3_VP_Taste 3;
BA_ "GenSigAutoGenDsp" SG_ 1397 BS3_Verglasung_zu 1;
BA_ "GenSigAutoGenSnd" SG_ 1397 BS3_Verglasung_zu 1;
BA_ "GenSigSendType" SG_ 1397 BS3_Verglasung_zu 3;
BA_ "GenSigAutoGenDsp" SG_ 1397 BS3_PDC_Taster 1;
BA_ "GenSigAutoGenSnd" SG_ 1397 BS3_PDC_Taster 1;
BA_ "GenSigSendType" SG_ 1397 BS3_PDC_Taster 3;
BA_ "GenSigAutoGenDsp" SG_ 1397 BS3_IRUE_Taster 1;
BA_ "GenSigAutoGenSnd" SG_ 1397 BS3_IRUE_Taster 1;
BA_ "GenSigSendType" SG_ 1397 BS3_IRUE_Taster 3;
BA_ "GenSigAutoGenDsp" SG_ 1397 BS3_VB_Coming_Home 1;
BA_ "GenSigAutoGenSnd" SG_ 1397 BS3_VB_Coming_Home 1;
BA_ "GenSigSendType" SG_ 1397 BS3_VB_Coming_Home 3;
BA_ "GenSigAutoGenDsp" SG_ 1397 BS3_VB_Tagesfahrlicht 1;
BA_ "GenSigAutoGenSnd" SG_ 1397 BS3_VB_Tagesfahrlicht 1;
BA_ "GenSigSendType" SG_ 1397 BS3_VB_Tagesfahrlicht 3;
BA_ "GenSigAutoGenDsp" SG_ 1397 BS3_VB_Fussraumleuchten 1;
BA_ "GenSigAutoGenSnd" SG_ 1397 BS3_VB_Fussraumleuchten 1;
BA_ "GenSigSendType" SG_ 1397 BS3_VB_Fussraumleuchten 3;
BA_ "GenSigAutoGenDsp" SG_ 1397 BS3_LED_Heckscheibe 1;
BA_ "GenSigAutoGenSnd" SG_ 1397 BS3_LED_Heckscheibe 1;
BA_ "GenSigSendType" SG_ 1397 BS3_LED_Heckscheibe 3;
BA_ "GenSigAutoGenDsp" SG_ 1397 BS3_LED_Frontscheibe 1;
BA_ "GenSigAutoGenSnd" SG_ 1397 BS3_LED_Frontscheibe 1;
BA_ "GenSigSendType" SG_ 1397 BS3_LED_Frontscheibe 3;
BA_ "GenSigAutoGenDsp" SG_ 1397 BS3_LED_Sitze 1;
BA_ "GenSigAutoGenSnd" SG_ 1397 BS3_LED_Sitze 1;
BA_ "GenSigSendType" SG_ 1397 BS3_LED_Sitze 3;
BA_ "GenSigAutoGenDsp" SG_ 1397 BS3_LED_Aussenspiegel 1;
BA_ "GenSigAutoGenSnd" SG_ 1397 BS3_LED_Aussenspiegel 1;
BA_ "GenSigSendType" SG_ 1397 BS3_LED_Aussenspiegel 3;
BA_ "GenSigAutoGenDsp" SG_ 1397 BS3_Starterlaubnis 1;
BA_ "GenSigAutoGenSnd" SG_ 1397 BS3_Starterlaubnis 1;
BA_ "GenSigSendType" SG_ 1397 BS3_Starterlaubnis 3;
BA_ "GenSigAutoGenDsp" SG_ 1136 BSK_Blk_links 1;
BA_ "GenSigAutoGenSnd" SG_ 1136 BSK_Blk_links 1;
BA_ "GenSigSendType" SG_ 1136 BSK_Blk_links 3;
BA_ "GenSigAutoGenDsp" SG_ 1136 BSK_Blk_rechts 1;
BA_ "GenSigAutoGenSnd" SG_ 1136 BSK_Blk_rechts 1;
BA_ "GenSigSendType" SG_ 1136 BSK_Blk_rechts 3;
BA_ "GenSigAutoGenDsp" SG_ 1136 BSK_Anhaenger 1;
BA_ "GenSigAutoGenSnd" SG_ 1136 BSK_Anhaenger 1;
BA_ "GenSigSendType" SG_ 1136 BSK_Anhaenger 3;
BA_ "GenSigAutoGenDsp" SG_ 1136 BSK_Warnblinker 1;
BA_ "GenSigAutoGenSnd" SG_ 1136 BSK_Warnblinker 1;
BA_ "GenSigSendType" SG_ 1136 BSK_Warnblinker 3;
BA_ "GenSigAutoGenDsp" SG_ 1136 BSK_DWA_Akku 1;
BA_ "GenSigAutoGenSnd" SG_ 1136 BSK_DWA_Akku 1;
BA_ "GenSigSendType" SG_ 1136 BSK_DWA_Akku 0;
BA_ "GenSigAutoGenDsp" SG_ 1136 BSK_Rueckfahrlicht 1;
BA_ "GenSigAutoGenSnd" SG_ 1136 BSK_Rueckfahrlicht 1;
BA_ "GenSigSendType" SG_ 1136 BSK_Rueckfahrlicht 3;
BA_ "GenSigAutoGenDsp" SG_ 1136 BSK_Sammelfehler_AKI 1;
BA_ "GenSigAutoGenSnd" SG_ 1136 BSK_Sammelfehler_AKI 1;
BA_ "GenSigSendType" SG_ 1136 BSK_Sammelfehler_AKI 0;
BA_ "GenSigAutoGenDsp" SG_ 1136 BSK_Ladekontrollampe 1;
BA_ "GenSigAutoGenSnd" SG_ 1136 BSK_Ladekontrollampe 1;
BA_ "GenSigSendType" SG_ 1136 BSK_Ladekontrollampe 3;
BA_ "GenSigAutoGenDsp" SG_ 1136 BSK_FT_geoeffnet 1;
BA_ "GenSigAutoGenSnd" SG_ 1136 BSK_FT_geoeffnet 1;
BA_ "GenSigSendType" SG_ 1136 BSK_FT_geoeffnet 0;
BA_ "GenSigAutoGenDsp" SG_ 1136 BSK_BT_geoeffnet 1;
BA_ "GenSigAutoGenSnd" SG_ 1136 BSK_BT_geoeffnet 1;
BA_ "GenSigSendType" SG_ 1136 BSK_BT_geoeffnet 0;
BA_ "GenSigAutoGenDsp" SG_ 1136 BSK_HL_geoeffnet 1;
BA_ "GenSigAutoGenSnd" SG_ 1136 BSK_HL_geoeffnet 1;
BA_ "GenSigSendType" SG_ 1136 BSK_HL_geoeffnet 0;
BA_ "GenSigAutoGenDsp" SG_ 1136 BSK_HR_geoeffnet 1;
BA_ "GenSigAutoGenSnd" SG_ 1136 BSK_HR_geoeffnet 1;
BA_ "GenSigSendType" SG_ 1136 BSK_HR_geoeffnet 0;
BA_ "GenSigAutoGenDsp" SG_ 1136 BSK_MH_geoeffnet 1;
BA_ "GenSigAutoGenSnd" SG_ 1136 BSK_MH_geoeffnet 1;
BA_ "GenSigSendType" SG_ 1136 BSK_MH_geoeffnet 3;
BA_ "GenSigAutoGenDsp" SG_ 1136 BSK_HD_Hauptraste 1;
BA_ "GenSigAutoGenSnd" SG_ 1136 BSK_HD_Hauptraste 1;
BA_ "GenSigSendType" SG_ 1136 BSK_HD_Hauptraste 0;
BA_ "GenSigAutoGenDsp" SG_ 1136 BSK_HD_Vorraste 1;
BA_ "GenSigAutoGenSnd" SG_ 1136 BSK_HD_Vorraste 1;
BA_ "GenSigSendType" SG_ 1136 BSK_HD_Vorraste 0;
BA_ "GenSigAutoGenDsp" SG_ 1136 BSK_Unterspannung 1;
BA_ "GenSigAutoGenSnd" SG_ 1136 BSK_Unterspannung 1;
BA_ "GenSigSendType" SG_ 1136 BSK_Unterspannung 0;
BA_ "GenSigAutoGenDsp" SG_ 1136 BSK_Display 1;
BA_ "GenSigAutoGenSnd" SG_ 1136 BSK_Display 1;
BA_ "GenSigSendType" SG_ 1136 BSK_Display 3;
BA_ "Fehlerwert" SG_ 1136 BSK_Display 127;
BA_ "GenSigAutoGenDsp" SG_ 1136 BSK_Display_def 1;
BA_ "GenSigAutoGenSnd" SG_ 1136 BSK_Display_def 1;
BA_ "GenSigSendType" SG_ 1136 BSK_Display_def 3;
BA_ "GenSigAutoGenDsp" SG_ 1136 BSK_Klemme_58t 1;
BA_ "GenSigAutoGenSnd" SG_ 1136 BSK_Klemme_58t 1;
BA_ "GenSigSendType" SG_ 1136 BSK_Klemme_58t 3;
BA_ "Fehlerwert" SG_ 1136 BSK_Klemme_58t 127;
BA_ "GenSigAutoGenDsp" SG_ 1136 BSK_Klemme_58t_def 1;
BA_ "GenSigAutoGenSnd" SG_ 1136 BSK_Klemme_58t_def 1;
BA_ "GenSigSendType" SG_ 1136 BSK_Klemme_58t_def 3;
BA_ "GenSigAutoGenDsp" SG_ 1136 BSK_Interlock 1;
BA_ "GenSigAutoGenSnd" SG_ 1136 BSK_Interlock 1;
BA_ "GenSigSendType" SG_ 1136 BSK_Interlock 0;
BA_ "GenSigAutoGenDsp" SG_ 1136 BSK_Buzzer 1;
BA_ "GenSigAutoGenSnd" SG_ 1136 BSK_Buzzer 1;
BA_ "GenSigSendType" SG_ 1136 BSK_Buzzer 0;
BA_ "GenSigAutoGenDsp" SG_ 1136 BSK_Ruecks_HL_verriegelt 1;
BA_ "GenSigAutoGenSnd" SG_ 1136 BSK_Ruecks_HL_verriegelt 1;
BA_ "GenSigSendType" SG_ 1136 BSK_Ruecks_HL_verriegelt 0;
BA_ "GenSigAutoGenDsp" SG_ 1136 BSK_Ruecks_HR_verriegelt 1;
BA_ "GenSigAutoGenSnd" SG_ 1136 BSK_Ruecks_HR_verriegelt 1;
BA_ "GenSigSendType" SG_ 1136 BSK_Ruecks_HR_verriegelt 0;
BA_ "GenSigAutoGenDsp" SG_ 1136 BSK_Def_Lampe 1;
BA_ "GenSigAutoGenSnd" SG_ 1136 BSK_Def_Lampe 1;
BA_ "GenSigSendType" SG_ 1136 BSK_Def_Lampe 0;
BA_ "GenSigAutoGenDsp" SG_ 1136 BSK_NSL_LED_Pfad 1;
BA_ "GenSigAutoGenSnd" SG_ 1136 BSK_NSL_LED_Pfad 1;
BA_ "GenSigSendType" SG_ 1136 BSK_NSL_LED_Pfad 0;
BA_ "GenSigAutoGenDsp" SG_ 1136 BSK_AFL_defekt 1;
BA_ "GenSigAutoGenSnd" SG_ 1136 BSK_AFL_defekt 1;
BA_ "GenSigSendType" SG_ 1136 BSK_AFL_defekt 0;
BA_ "GenSigSwitchedByIgnition" SG_ 1136 BSK_AFL_defekt 1;
BA_ "GenSigAutoGenDsp" SG_ 1136 BSK_BSG_defekt 1;
BA_ "GenSigAutoGenSnd" SG_ 1136 BSK_BSG_defekt 1;
BA_ "GenSigSendType" SG_ 1136 BSK_BSG_defekt 0;
BA_ "GenSigAutoGenDsp" SG_ 1136 BSK_Standlicht 1;
BA_ "GenSigAutoGenSnd" SG_ 1136 BSK_Standlicht 1;
BA_ "GenSigSendType" SG_ 1136 BSK_Standlicht 3;
BA_ "GenSigAutoGenDsp" SG_ 1136 BSK_Parklicht_links 1;
BA_ "GenSigAutoGenSnd" SG_ 1136 BSK_Parklicht_links 1;
BA_ "GenSigSendType" SG_ 1136 BSK_Parklicht_links 3;
BA_ "GenSigAutoGenDsp" SG_ 1136 BSK_Parklicht_rechts 1;
BA_ "GenSigAutoGenSnd" SG_ 1136 BSK_Parklicht_rechts 1;
BA_ "GenSigSendType" SG_ 1136 BSK_Parklicht_rechts 3;
BA_ "GenSigAutoGenDsp" SG_ 1136 BSK_Abblendlicht 1;
BA_ "GenSigAutoGenSnd" SG_ 1136 BSK_Abblendlicht 1;
BA_ "GenSigSendType" SG_ 1136 BSK_Abblendlicht 3;
BA_ "GenSigAutoGenDsp" SG_ 1136 BSK_Nebellicht 1;
BA_ "GenSigAutoGenSnd" SG_ 1136 BSK_Nebellicht 1;
BA_ "GenSigSendType" SG_ 1136 BSK_Nebellicht 3;
BA_ "GenSigAutoGenDsp" SG_ 1136 BSK_Heckscheibenhzg 1;
BA_ "GenSigAutoGenSnd" SG_ 1136 BSK_Heckscheibenhzg 1;
BA_ "GenSigSendType" SG_ 1136 BSK_Heckscheibenhzg 0;
BA_ "GenSigAutoGenDsp" SG_ 1136 BSK_Tankklappe 1;
BA_ "GenSigAutoGenSnd" SG_ 1136 BSK_Tankklappe 1;
BA_ "GenSigSendType" SG_ 1136 BSK_Tankklappe 0;
BA_ "GenSigAutoGenDsp" SG_ 1136 BSK_FFB_Bat 1;
BA_ "GenSigAutoGenSnd" SG_ 1136 BSK_FFB_Bat 1;
BA_ "GenSigSendType" SG_ 1136 BSK_FFB_Bat 0;
BA_ "GenSigAutoGenDsp" SG_ 1136 BSK_FLA_Soft_LED 1;
BA_ "GenSigAutoGenSnd" SG_ 1136 BSK_FLA_Soft_LED 1;
BA_ "GenSigSendType" SG_ 1136 BSK_FLA_Soft_LED 0;
BA_ "GenSigSwitchedByIgnition" SG_ 1136 BSK_FLA_Soft_LED 1;
BA_ "GenSigAutoGenDsp" SG_ 1136 BSK_FLA_Sensor_blockiert 1;
BA_ "GenSigAutoGenSnd" SG_ 1136 BSK_FLA_Sensor_blockiert 1;
BA_ "GenSigSendType" SG_ 1136 BSK_FLA_Sensor_blockiert 0;
BA_ "GenSigSwitchedByIgnition" SG_ 1136 BSK_FLA_Sensor_blockiert 1;
BA_ "GenSigAutoGenDsp" SG_ 1136 BSK_FLA_Defekt 1;
BA_ "GenSigAutoGenSnd" SG_ 1136 BSK_FLA_Defekt 1;
BA_ "GenSigSendType" SG_ 1136 BSK_FLA_Defekt 0;
BA_ "GenSigSwitchedByIgnition" SG_ 1136 BSK_FLA_Defekt 1;
BA_ "GenSigSendType" SG_ 1136 BCM_Remotestart_Betrieb 3;
BA_ "GenSigAutoGenDsp" SG_ 1136 BSK_Ruhespannung 1;
BA_ "GenSigAutoGenSnd" SG_ 1136 BSK_Ruhespannung 1;
BA_ "GenSigSendType" SG_ 1136 BSK_Ruhespannung 0;
BA_ "Fehlerwert" SG_ 1136 BSK_Ruhespannung 31;
BA_ "GenSigAutoGenDsp" SG_ 1136 BSK_Nebelschlusslicht 1;
BA_ "GenSigAutoGenSnd" SG_ 1136 BSK_Nebelschlusslicht 1;
BA_ "GenSigSendType" SG_ 1136 BSK_Nebelschlusslicht 3;
BA_ "GenSigAutoGenDsp" SG_ 1136 BSK_Fernlicht 1;
BA_ "GenSigAutoGenSnd" SG_ 1136 BSK_Fernlicht 1;
BA_ "GenSigSendType" SG_ 1136 BSK_Fernlicht 3;
BA_ "GenSigAutoGenDsp" SG_ 1136 BSK_Tagfahrlicht 1;
BA_ "GenSigAutoGenSnd" SG_ 1136 BSK_Tagfahrlicht 1;
BA_ "GenSigSendType" SG_ 1136 BSK_Tagfahrlicht 3;
BA_ "GenSigAutoGenDsp" SG_ 1712 Module_ID_36 1;
BA_ "GenSigAutoGenSnd" SG_ 1712 Module_ID_36 1;
BA_ "GenSigSendType" SG_ 1712 Module_ID_36 6;
BA_ "GenSigAutoGenDsp" SG_ 1712 Update_Indikator_36 1;
BA_ "GenSigAutoGenSnd" SG_ 1712 Update_Indikator_36 1;
BA_ "GenSigSendType" SG_ 1712 Update_Indikator_36 6;
BA_ "GenSigAutoGenDsp" SG_ 1712 Funktions_ID_36 1;
BA_ "GenSigAutoGenSnd" SG_ 1712 Funktions_ID_36 1;
BA_ "GenSigSendType" SG_ 1712 Funktions_ID_36 6;
BA_ "GenSigAutoGenDsp" SG_ 1712 OpCode_36 1;
BA_ "GenSigAutoGenSnd" SG_ 1712 OpCode_36 1;
BA_ "GenSigSendType" SG_ 1712 OpCode_36 6;
BA_ "GenSigAutoGenDsp" SG_ 1712 Controller_ID_36 1;
BA_ "GenSigAutoGenSnd" SG_ 1712 Controller_ID_36 1;
BA_ "GenSigSendType" SG_ 1712 Controller_ID_36 6;
BA_ "GenSigAutoGenDsp" SG_ 1712 Data_Byte_1_36 1;
BA_ "GenSigAutoGenSnd" SG_ 1712 Data_Byte_1_36 1;
BA_ "GenSigSendType" SG_ 1712 Data_Byte_1_36 6;
BA_ "GenSigAutoGenDsp" SG_ 1712 Data_Byte_2_36 1;
BA_ "GenSigAutoGenSnd" SG_ 1712 Data_Byte_2_36 1;
BA_ "GenSigSendType" SG_ 1712 Data_Byte_2_36 6;
BA_ "GenSigAutoGenDsp" SG_ 1712 Data_Byte_3_36 1;
BA_ "GenSigAutoGenSnd" SG_ 1712 Data_Byte_3_36 1;
BA_ "GenSigSendType" SG_ 1712 Data_Byte_3_36 6;
BA_ "GenSigAutoGenDsp" SG_ 1712 Data_Byte_4_36 1;
BA_ "GenSigAutoGenSnd" SG_ 1712 Data_Byte_4_36 1;
BA_ "GenSigSendType" SG_ 1712 Data_Byte_4_36 6;
BA_ "GenSigAutoGenDsp" SG_ 1712 Data_Byte_5_36 1;
BA_ "GenSigAutoGenSnd" SG_ 1712 Data_Byte_5_36 1;
BA_ "GenSigSendType" SG_ 1712 Data_Byte_5_36 6;
BA_ "GenSigAutoGenDsp" SG_ 1696 Module_ID_0 1;
BA_ "GenSigAutoGenSnd" SG_ 1696 Module_ID_0 1;
BA_ "GenSigSendType" SG_ 1696 Module_ID_0 6;
BA_ "GenSigAutoGenDsp" SG_ 1696 Update_Indikator_0 1;
BA_ "GenSigAutoGenSnd" SG_ 1696 Update_Indikator_0 1;
BA_ "GenSigSendType" SG_ 1696 Update_Indikator_0 6;
BA_ "GenSigAutoGenDsp" SG_ 1696 Funktions_ID_0 1;
BA_ "GenSigAutoGenSnd" SG_ 1696 Funktions_ID_0 1;
BA_ "GenSigSendType" SG_ 1696 Funktions_ID_0 6;
BA_ "GenSigAutoGenDsp" SG_ 1696 OpCode_0 1;
BA_ "GenSigAutoGenSnd" SG_ 1696 OpCode_0 1;
BA_ "GenSigSendType" SG_ 1696 OpCode_0 6;
BA_ "GenSigAutoGenDsp" SG_ 1696 Controller_ID_0 1;
BA_ "GenSigAutoGenSnd" SG_ 1696 Controller_ID_0 1;
BA_ "GenSigSendType" SG_ 1696 Controller_ID_0 6;
BA_ "GenSigAutoGenDsp" SG_ 1696 Data_Byte_1_0 1;
BA_ "GenSigAutoGenSnd" SG_ 1696 Data_Byte_1_0 1;
BA_ "GenSigSendType" SG_ 1696 Data_Byte_1_0 6;
BA_ "GenSigAutoGenDsp" SG_ 1696 Data_Byte_2_0 1;
BA_ "GenSigAutoGenSnd" SG_ 1696 Data_Byte_2_0 1;
BA_ "GenSigSendType" SG_ 1696 Data_Byte_2_0 6;
BA_ "GenSigAutoGenDsp" SG_ 1696 Data_Byte_3_0 1;
BA_ "GenSigAutoGenSnd" SG_ 1696 Data_Byte_3_0 1;
BA_ "GenSigSendType" SG_ 1696 Data_Byte_3_0 6;
BA_ "GenSigAutoGenDsp" SG_ 1696 Data_Byte_4_0 1;
BA_ "GenSigAutoGenSnd" SG_ 1696 Data_Byte_4_0 1;
BA_ "GenSigSendType" SG_ 1696 Data_Byte_4_0 6;
BA_ "GenSigAutoGenDsp" SG_ 1696 Data_Byte_5_0 1;
BA_ "GenSigAutoGenSnd" SG_ 1696 Data_Byte_5_0 1;
BA_ "GenSigSendType" SG_ 1696 Data_Byte_5_0 6;
BA_ "GenSigAutoGenDsp" SG_ 1713 Module_ID_37 1;
BA_ "GenSigAutoGenSnd" SG_ 1713 Module_ID_37 1;
BA_ "GenSigSendType" SG_ 1713 Module_ID_37 6;
BA_ "GenSigAutoGenDsp" SG_ 1713 Update_Indikator_37 1;
BA_ "GenSigAutoGenSnd" SG_ 1713 Update_Indikator_37 1;
BA_ "GenSigSendType" SG_ 1713 Update_Indikator_37 6;
BA_ "GenSigAutoGenDsp" SG_ 1713 Funktions_ID_37 1;
BA_ "GenSigAutoGenSnd" SG_ 1713 Funktions_ID_37 1;
BA_ "GenSigSendType" SG_ 1713 Funktions_ID_37 6;
BA_ "GenSigAutoGenDsp" SG_ 1713 OpCode_37 1;
BA_ "GenSigAutoGenSnd" SG_ 1713 OpCode_37 1;
BA_ "GenSigSendType" SG_ 1713 OpCode_37 6;
BA_ "GenSigAutoGenDsp" SG_ 1713 Controller_ID_37 1;
BA_ "GenSigAutoGenSnd" SG_ 1713 Controller_ID_37 1;
BA_ "GenSigSendType" SG_ 1713 Controller_ID_37 6;
BA_ "GenSigAutoGenDsp" SG_ 1713 Data_Byte_1_37 1;
BA_ "GenSigAutoGenSnd" SG_ 1713 Data_Byte_1_37 1;
BA_ "GenSigSendType" SG_ 1713 Data_Byte_1_37 6;
BA_ "GenSigAutoGenDsp" SG_ 1713 Data_Byte_2_37 1;
BA_ "GenSigAutoGenSnd" SG_ 1713 Data_Byte_2_37 1;
BA_ "GenSigSendType" SG_ 1713 Data_Byte_2_37 6;
BA_ "GenSigAutoGenDsp" SG_ 1713 Data_Byte_3_37 1;
BA_ "GenSigAutoGenSnd" SG_ 1713 Data_Byte_3_37 1;
BA_ "GenSigSendType" SG_ 1713 Data_Byte_3_37 6;
BA_ "GenSigAutoGenDsp" SG_ 1713 Data_Byte_4_37 1;
BA_ "GenSigAutoGenSnd" SG_ 1713 Data_Byte_4_37 1;
BA_ "GenSigSendType" SG_ 1713 Data_Byte_4_37 6;
BA_ "GenSigAutoGenDsp" SG_ 1713 Data_Byte_5_37 1;
BA_ "GenSigAutoGenSnd" SG_ 1713 Data_Byte_5_37 1;
BA_ "GenSigSendType" SG_ 1713 Data_Byte_5_37 6;
BA_ "GenSigAutoGenDsp" SG_ 1697 Module_ID_1 1;
BA_ "GenSigAutoGenSnd" SG_ 1697 Module_ID_1 1;
BA_ "GenSigSendType" SG_ 1697 Module_ID_1 6;
BA_ "GenSigAutoGenDsp" SG_ 1697 Update_Indikator_1 1;
BA_ "GenSigAutoGenSnd" SG_ 1697 Update_Indikator_1 1;
BA_ "GenSigSendType" SG_ 1697 Update_Indikator_1 6;
BA_ "GenSigAutoGenDsp" SG_ 1697 Funktions_ID_1 1;
BA_ "GenSigAutoGenSnd" SG_ 1697 Funktions_ID_1 1;
BA_ "GenSigSendType" SG_ 1697 Funktions_ID_1 6;
BA_ "GenSigAutoGenDsp" SG_ 1697 OpCode_1 1;
BA_ "GenSigAutoGenSnd" SG_ 1697 OpCode_1 1;
BA_ "GenSigSendType" SG_ 1697 OpCode_1 6;
BA_ "GenSigAutoGenDsp" SG_ 1697 Controller_ID_1 1;
BA_ "GenSigAutoGenSnd" SG_ 1697 Controller_ID_1 1;
BA_ "GenSigSendType" SG_ 1697 Controller_ID_1 6;
BA_ "GenSigAutoGenDsp" SG_ 1697 Data_Byte_1_1 1;
BA_ "GenSigAutoGenSnd" SG_ 1697 Data_Byte_1_1 1;
BA_ "GenSigSendType" SG_ 1697 Data_Byte_1_1 6;
BA_ "GenSigAutoGenDsp" SG_ 1697 Data_Byte_2_1 1;
BA_ "GenSigAutoGenSnd" SG_ 1697 Data_Byte_2_1 1;
BA_ "GenSigSendType" SG_ 1697 Data_Byte_2_1 6;
BA_ "GenSigAutoGenDsp" SG_ 1697 Data_Byte_3_1 1;
BA_ "GenSigAutoGenSnd" SG_ 1697 Data_Byte_3_1 1;
BA_ "GenSigSendType" SG_ 1697 Data_Byte_3_1 6;
BA_ "GenSigAutoGenDsp" SG_ 1697 Data_Byte_4_1 1;
BA_ "GenSigAutoGenSnd" SG_ 1697 Data_Byte_4_1 1;
BA_ "GenSigSendType" SG_ 1697 Data_Byte_4_1 6;
BA_ "GenSigAutoGenDsp" SG_ 1697 Data_Byte_5_1 1;
BA_ "GenSigAutoGenSnd" SG_ 1697 Data_Byte_5_1 1;
BA_ "GenSigSendType" SG_ 1697 Data_Byte_5_1 6;
BA_ "GenSigAutoGenDsp" SG_ 1782 Module_ID_21 1;
BA_ "GenSigAutoGenSnd" SG_ 1782 Module_ID_21 1;
BA_ "GenSigSendType" SG_ 1782 Module_ID_21 6;
BA_ "GenSigAutoGenDsp" SG_ 1782 Update_Indikator_21 1;
BA_ "GenSigAutoGenSnd" SG_ 1782 Update_Indikator_21 1;
BA_ "GenSigSendType" SG_ 1782 Update_Indikator_21 6;
BA_ "GenSigAutoGenDsp" SG_ 1782 Funktions_ID_21 1;
BA_ "GenSigAutoGenSnd" SG_ 1782 Funktions_ID_21 1;
BA_ "GenSigSendType" SG_ 1782 Funktions_ID_21 6;
BA_ "GenSigAutoGenDsp" SG_ 1782 OpCode_21 1;
BA_ "GenSigAutoGenSnd" SG_ 1782 OpCode_21 1;
BA_ "GenSigSendType" SG_ 1782 OpCode_21 6;
BA_ "GenSigAutoGenDsp" SG_ 1782 Controller_ID_21 1;
BA_ "GenSigAutoGenSnd" SG_ 1782 Controller_ID_21 1;
BA_ "GenSigSendType" SG_ 1782 Controller_ID_21 6;
BA_ "GenSigAutoGenDsp" SG_ 1782 Data_Byte_1_21 1;
BA_ "GenSigAutoGenSnd" SG_ 1782 Data_Byte_1_21 1;
BA_ "GenSigSendType" SG_ 1782 Data_Byte_1_21 6;
BA_ "GenSigAutoGenDsp" SG_ 1782 Data_Byte_2_21 1;
BA_ "GenSigAutoGenSnd" SG_ 1782 Data_Byte_2_21 1;
BA_ "GenSigSendType" SG_ 1782 Data_Byte_2_21 6;
BA_ "GenSigAutoGenDsp" SG_ 1782 Data_Byte_3_21 1;
BA_ "GenSigAutoGenSnd" SG_ 1782 Data_Byte_3_21 1;
BA_ "GenSigSendType" SG_ 1782 Data_Byte_3_21 6;
BA_ "GenSigAutoGenDsp" SG_ 1782 Data_Byte_4_21 1;
BA_ "GenSigAutoGenSnd" SG_ 1782 Data_Byte_4_21 1;
BA_ "GenSigSendType" SG_ 1782 Data_Byte_4_21 6;
BA_ "GenSigAutoGenDsp" SG_ 1782 Data_Byte_5_21 1;
BA_ "GenSigAutoGenSnd" SG_ 1782 Data_Byte_5_21 1;
BA_ "GenSigSendType" SG_ 1782 Data_Byte_5_21 6;
BA_ "GenSigAutoGenDsp" SG_ 1763 Module_ID_33 1;
BA_ "GenSigAutoGenSnd" SG_ 1763 Module_ID_33 1;
BA_ "GenSigSendType" SG_ 1763 Module_ID_33 6;
BA_ "GenSigAutoGenDsp" SG_ 1763 Update_Indikator_33 1;
BA_ "GenSigAutoGenSnd" SG_ 1763 Update_Indikator_33 1;
BA_ "GenSigSendType" SG_ 1763 Update_Indikator_33 6;
BA_ "GenSigAutoGenDsp" SG_ 1763 Funktions_ID_33 1;
BA_ "GenSigAutoGenSnd" SG_ 1763 Funktions_ID_33 1;
BA_ "GenSigSendType" SG_ 1763 Funktions_ID_33 6;
BA_ "GenSigAutoGenDsp" SG_ 1763 OpCode_33 1;
BA_ "GenSigAutoGenSnd" SG_ 1763 OpCode_33 1;
BA_ "GenSigSendType" SG_ 1763 OpCode_33 6;
BA_ "GenSigAutoGenDsp" SG_ 1763 Controller_ID_33 1;
BA_ "GenSigAutoGenSnd" SG_ 1763 Controller_ID_33 1;
BA_ "GenSigSendType" SG_ 1763 Controller_ID_33 6;
BA_ "GenSigAutoGenDsp" SG_ 1763 Data_Byte_1_33 1;
BA_ "GenSigAutoGenSnd" SG_ 1763 Data_Byte_1_33 1;
BA_ "GenSigSendType" SG_ 1763 Data_Byte_1_33 6;
BA_ "GenSigAutoGenDsp" SG_ 1763 Data_Byte_2_33 1;
BA_ "GenSigAutoGenSnd" SG_ 1763 Data_Byte_2_33 1;
BA_ "GenSigSendType" SG_ 1763 Data_Byte_2_33 6;
BA_ "GenSigAutoGenDsp" SG_ 1763 Data_Byte_3_33 1;
BA_ "GenSigAutoGenSnd" SG_ 1763 Data_Byte_3_33 1;
BA_ "GenSigSendType" SG_ 1763 Data_Byte_3_33 6;
BA_ "GenSigAutoGenDsp" SG_ 1763 Data_Byte_4_33 1;
BA_ "GenSigAutoGenSnd" SG_ 1763 Data_Byte_4_33 1;
BA_ "GenSigSendType" SG_ 1763 Data_Byte_4_33 6;
BA_ "GenSigAutoGenDsp" SG_ 1763 Data_Byte_5_33 1;
BA_ "GenSigAutoGenSnd" SG_ 1763 Data_Byte_5_33 1;
BA_ "GenSigSendType" SG_ 1763 Data_Byte_5_33 6;
BA_ "GenSigAutoGenDsp" SG_ 1764 Module_ID_34 1;
BA_ "GenSigAutoGenSnd" SG_ 1764 Module_ID_34 1;
BA_ "GenSigSendType" SG_ 1764 Module_ID_34 6;
BA_ "GenSigAutoGenDsp" SG_ 1764 Update_Indikator_34 1;
BA_ "GenSigAutoGenSnd" SG_ 1764 Update_Indikator_34 1;
BA_ "GenSigSendType" SG_ 1764 Update_Indikator_34 6;
BA_ "GenSigAutoGenDsp" SG_ 1764 Funktions_ID_34 1;
BA_ "GenSigAutoGenSnd" SG_ 1764 Funktions_ID_34 1;
BA_ "GenSigSendType" SG_ 1764 Funktions_ID_34 6;
BA_ "GenSigAutoGenDsp" SG_ 1764 OpCode_34 1;
BA_ "GenSigAutoGenSnd" SG_ 1764 OpCode_34 1;
BA_ "GenSigSendType" SG_ 1764 OpCode_34 6;
BA_ "GenSigAutoGenDsp" SG_ 1764 Controller_ID_34 1;
BA_ "GenSigAutoGenSnd" SG_ 1764 Controller_ID_34 1;
BA_ "GenSigSendType" SG_ 1764 Controller_ID_34 6;
BA_ "GenSigAutoGenDsp" SG_ 1764 Data_Byte_1_34 1;
BA_ "GenSigAutoGenSnd" SG_ 1764 Data_Byte_1_34 1;
BA_ "GenSigSendType" SG_ 1764 Data_Byte_1_34 6;
BA_ "GenSigAutoGenDsp" SG_ 1764 Data_Byte_2_34 1;
BA_ "GenSigAutoGenSnd" SG_ 1764 Data_Byte_2_34 1;
BA_ "GenSigSendType" SG_ 1764 Data_Byte_2_34 6;
BA_ "GenSigAutoGenDsp" SG_ 1764 Data_Byte_3_34 1;
BA_ "GenSigAutoGenSnd" SG_ 1764 Data_Byte_3_34 1;
BA_ "GenSigSendType" SG_ 1764 Data_Byte_3_34 6;
BA_ "GenSigAutoGenDsp" SG_ 1764 Data_Byte_4_34 1;
BA_ "GenSigAutoGenSnd" SG_ 1764 Data_Byte_4_34 1;
BA_ "GenSigSendType" SG_ 1764 Data_Byte_4_34 6;
BA_ "GenSigAutoGenDsp" SG_ 1764 Data_Byte_5_34 1;
BA_ "GenSigAutoGenSnd" SG_ 1764 Data_Byte_5_34 1;
BA_ "GenSigSendType" SG_ 1764 Data_Byte_5_34 6;
BA_ "GenSigAutoGenDsp" SG_ 1765 Module_ID_35 1;
BA_ "GenSigAutoGenSnd" SG_ 1765 Module_ID_35 1;
BA_ "GenSigSendType" SG_ 1765 Module_ID_35 6;
BA_ "GenSigAutoGenDsp" SG_ 1765 Update_Indikator_35 1;
BA_ "GenSigAutoGenSnd" SG_ 1765 Update_Indikator_35 1;
BA_ "GenSigSendType" SG_ 1765 Update_Indikator_35 6;
BA_ "GenSigAutoGenDsp" SG_ 1765 Funktions_ID_35 1;
BA_ "GenSigAutoGenSnd" SG_ 1765 Funktions_ID_35 1;
BA_ "GenSigSendType" SG_ 1765 Funktions_ID_35 6;
BA_ "GenSigAutoGenDsp" SG_ 1765 OpCode_35 1;
BA_ "GenSigAutoGenSnd" SG_ 1765 OpCode_35 1;
BA_ "GenSigSendType" SG_ 1765 OpCode_35 6;
BA_ "GenSigAutoGenDsp" SG_ 1765 Controller_ID_35 1;
BA_ "GenSigAutoGenSnd" SG_ 1765 Controller_ID_35 1;
BA_ "GenSigSendType" SG_ 1765 Controller_ID_35 6;
BA_ "GenSigAutoGenDsp" SG_ 1765 Data_Byte_1_35 1;
BA_ "GenSigAutoGenSnd" SG_ 1765 Data_Byte_1_35 1;
BA_ "GenSigSendType" SG_ 1765 Data_Byte_1_35 6;
BA_ "GenSigAutoGenDsp" SG_ 1765 Data_Byte_2_35 1;
BA_ "GenSigAutoGenSnd" SG_ 1765 Data_Byte_2_35 1;
BA_ "GenSigSendType" SG_ 1765 Data_Byte_2_35 6;
BA_ "GenSigAutoGenDsp" SG_ 1765 Data_Byte_3_35 1;
BA_ "GenSigAutoGenSnd" SG_ 1765 Data_Byte_3_35 1;
BA_ "GenSigSendType" SG_ 1765 Data_Byte_3_35 6;
BA_ "GenSigAutoGenDsp" SG_ 1765 Data_Byte_4_35 1;
BA_ "GenSigAutoGenSnd" SG_ 1765 Data_Byte_4_35 1;
BA_ "GenSigSendType" SG_ 1765 Data_Byte_4_35 6;
BA_ "GenSigAutoGenDsp" SG_ 1765 Data_Byte_5_35 1;
BA_ "GenSigAutoGenSnd" SG_ 1765 Data_Byte_5_35 1;
BA_ "GenSigSendType" SG_ 1765 Data_Byte_5_35 6;
BA_ "GenSigAutoGenDsp" SG_ 1704 Module_ID_8 1;
BA_ "GenSigAutoGenSnd" SG_ 1704 Module_ID_8 1;
BA_ "GenSigSendType" SG_ 1704 Module_ID_8 6;
BA_ "GenSigAutoGenDsp" SG_ 1704 Update_Indikator_8 1;
BA_ "GenSigAutoGenSnd" SG_ 1704 Update_Indikator_8 1;
BA_ "GenSigSendType" SG_ 1704 Update_Indikator_8 6;
BA_ "GenSigAutoGenDsp" SG_ 1704 Funktions_ID_8 1;
BA_ "GenSigAutoGenSnd" SG_ 1704 Funktions_ID_8 1;
BA_ "GenSigSendType" SG_ 1704 Funktions_ID_8 6;
BA_ "GenSigAutoGenDsp" SG_ 1704 OpCode_8 1;
BA_ "GenSigAutoGenSnd" SG_ 1704 OpCode_8 1;
BA_ "GenSigSendType" SG_ 1704 OpCode_8 6;
BA_ "GenSigAutoGenDsp" SG_ 1704 Controller_ID_8 1;
BA_ "GenSigAutoGenSnd" SG_ 1704 Controller_ID_8 1;
BA_ "GenSigSendType" SG_ 1704 Controller_ID_8 6;
BA_ "GenSigAutoGenDsp" SG_ 1704 Data_Byte_1_8 1;
BA_ "GenSigAutoGenSnd" SG_ 1704 Data_Byte_1_8 1;
BA_ "GenSigSendType" SG_ 1704 Data_Byte_1_8 6;
BA_ "GenSigAutoGenDsp" SG_ 1704 Data_Byte_2_8 1;
BA_ "GenSigAutoGenSnd" SG_ 1704 Data_Byte_2_8 1;
BA_ "GenSigSendType" SG_ 1704 Data_Byte_2_8 6;
BA_ "GenSigAutoGenDsp" SG_ 1704 Data_Byte_3_8 1;
BA_ "GenSigAutoGenSnd" SG_ 1704 Data_Byte_3_8 1;
BA_ "GenSigSendType" SG_ 1704 Data_Byte_3_8 6;
BA_ "GenSigAutoGenDsp" SG_ 1704 Data_Byte_4_8 1;
BA_ "GenSigAutoGenSnd" SG_ 1704 Data_Byte_4_8 1;
BA_ "GenSigSendType" SG_ 1704 Data_Byte_4_8 6;
BA_ "GenSigAutoGenDsp" SG_ 1704 Data_Byte_5_8 1;
BA_ "GenSigAutoGenSnd" SG_ 1704 Data_Byte_5_8 1;
BA_ "GenSigSendType" SG_ 1704 Data_Byte_5_8 6;
BA_ "GenSigAutoGenDsp" SG_ 1714 Module_ID_38 1;
BA_ "GenSigAutoGenSnd" SG_ 1714 Module_ID_38 1;
BA_ "GenSigSendType" SG_ 1714 Module_ID_38 6;
BA_ "GenSigAutoGenDsp" SG_ 1714 Update_Indikator_38 1;
BA_ "GenSigAutoGenSnd" SG_ 1714 Update_Indikator_38 1;
BA_ "GenSigSendType" SG_ 1714 Update_Indikator_38 6;
BA_ "GenSigAutoGenDsp" SG_ 1714 Funktions_ID_38 1;
BA_ "GenSigAutoGenSnd" SG_ 1714 Funktions_ID_38 1;
BA_ "GenSigSendType" SG_ 1714 Funktions_ID_38 6;
BA_ "GenSigAutoGenDsp" SG_ 1714 OpCode_38 1;
BA_ "GenSigAutoGenSnd" SG_ 1714 OpCode_38 1;
BA_ "GenSigSendType" SG_ 1714 OpCode_38 6;
BA_ "GenSigAutoGenDsp" SG_ 1714 Controller_ID_38 1;
BA_ "GenSigAutoGenSnd" SG_ 1714 Controller_ID_38 1;
BA_ "GenSigSendType" SG_ 1714 Controller_ID_38 6;
BA_ "GenSigAutoGenDsp" SG_ 1714 Data_Byte_1_38 1;
BA_ "GenSigAutoGenSnd" SG_ 1714 Data_Byte_1_38 1;
BA_ "GenSigSendType" SG_ 1714 Data_Byte_1_38 6;
BA_ "GenSigAutoGenDsp" SG_ 1714 Data_Byte_2_38 1;
BA_ "GenSigAutoGenSnd" SG_ 1714 Data_Byte_2_38 1;
BA_ "GenSigSendType" SG_ 1714 Data_Byte_2_38 6;
BA_ "GenSigAutoGenDsp" SG_ 1714 Data_Byte_3_38 1;
BA_ "GenSigAutoGenSnd" SG_ 1714 Data_Byte_3_38 1;
BA_ "GenSigSendType" SG_ 1714 Data_Byte_3_38 6;
BA_ "GenSigAutoGenDsp" SG_ 1714 Data_Byte_4_38 1;
BA_ "GenSigAutoGenSnd" SG_ 1714 Data_Byte_4_38 1;
BA_ "GenSigSendType" SG_ 1714 Data_Byte_4_38 6;
BA_ "GenSigAutoGenDsp" SG_ 1714 Data_Byte_5_38 1;
BA_ "GenSigAutoGenSnd" SG_ 1714 Data_Byte_5_38 1;
BA_ "GenSigSendType" SG_ 1714 Data_Byte_5_38 6;
BA_ "GenSigAutoGenDsp" SG_ 1698 Module_ID_2 1;
BA_ "GenSigAutoGenSnd" SG_ 1698 Module_ID_2 1;
BA_ "GenSigSendType" SG_ 1698 Module_ID_2 6;
BA_ "GenSigAutoGenDsp" SG_ 1698 Update_Indikator_2 1;
BA_ "GenSigAutoGenSnd" SG_ 1698 Update_Indikator_2 1;
BA_ "GenSigSendType" SG_ 1698 Update_Indikator_2 6;
BA_ "GenSigAutoGenDsp" SG_ 1698 Funktions_ID_2 1;
BA_ "GenSigAutoGenSnd" SG_ 1698 Funktions_ID_2 1;
BA_ "GenSigSendType" SG_ 1698 Funktions_ID_2 6;
BA_ "GenSigAutoGenDsp" SG_ 1698 OpCode_2 1;
BA_ "GenSigAutoGenSnd" SG_ 1698 OpCode_2 1;
BA_ "GenSigSendType" SG_ 1698 OpCode_2 6;
BA_ "GenSigAutoGenDsp" SG_ 1698 Controller_ID_2 1;
BA_ "GenSigAutoGenSnd" SG_ 1698 Controller_ID_2 1;
BA_ "GenSigSendType" SG_ 1698 Controller_ID_2 6;
BA_ "GenSigAutoGenDsp" SG_ 1698 Data_Byte_1_2 1;
BA_ "GenSigAutoGenSnd" SG_ 1698 Data_Byte_1_2 1;
BA_ "GenSigSendType" SG_ 1698 Data_Byte_1_2 6;
BA_ "GenSigAutoGenDsp" SG_ 1698 Data_Byte_2_2 1;
BA_ "GenSigAutoGenSnd" SG_ 1698 Data_Byte_2_2 1;
BA_ "GenSigSendType" SG_ 1698 Data_Byte_2_2 6;
BA_ "GenSigAutoGenDsp" SG_ 1698 Data_Byte_3_2 1;
BA_ "GenSigAutoGenSnd" SG_ 1698 Data_Byte_3_2 1;
BA_ "GenSigSendType" SG_ 1698 Data_Byte_3_2 6;
BA_ "GenSigAutoGenDsp" SG_ 1698 Data_Byte_4_2 1;
BA_ "GenSigAutoGenSnd" SG_ 1698 Data_Byte_4_2 1;
BA_ "GenSigSendType" SG_ 1698 Data_Byte_4_2 6;
BA_ "GenSigAutoGenDsp" SG_ 1698 Data_Byte_5_2 1;
BA_ "GenSigAutoGenSnd" SG_ 1698 Data_Byte_5_2 1;
BA_ "GenSigSendType" SG_ 1698 Data_Byte_5_2 6;
BA_ "GenSigAutoGenDsp" SG_ 1760 Module_ID_30 1;
BA_ "GenSigAutoGenSnd" SG_ 1760 Module_ID_30 1;
BA_ "GenSigSendType" SG_ 1760 Module_ID_30 6;
BA_ "GenSigAutoGenDsp" SG_ 1760 Update_Indikator_30 1;
BA_ "GenSigAutoGenSnd" SG_ 1760 Update_Indikator_30 1;
BA_ "GenSigSendType" SG_ 1760 Update_Indikator_30 6;
BA_ "GenSigAutoGenDsp" SG_ 1760 Funktions_ID_30 1;
BA_ "GenSigAutoGenSnd" SG_ 1760 Funktions_ID_30 1;
BA_ "GenSigSendType" SG_ 1760 Funktions_ID_30 6;
BA_ "GenSigAutoGenDsp" SG_ 1760 OpCode_30 1;
BA_ "GenSigAutoGenSnd" SG_ 1760 OpCode_30 1;
BA_ "GenSigSendType" SG_ 1760 OpCode_30 6;
BA_ "GenSigAutoGenDsp" SG_ 1760 Controller_ID_30 1;
BA_ "GenSigAutoGenSnd" SG_ 1760 Controller_ID_30 1;
BA_ "GenSigSendType" SG_ 1760 Controller_ID_30 6;
BA_ "GenSigAutoGenDsp" SG_ 1760 Data_Byte_1_30 1;
BA_ "GenSigAutoGenSnd" SG_ 1760 Data_Byte_1_30 1;
BA_ "GenSigSendType" SG_ 1760 Data_Byte_1_30 6;
BA_ "GenSigAutoGenDsp" SG_ 1760 Data_Byte_2_30 1;
BA_ "GenSigAutoGenSnd" SG_ 1760 Data_Byte_2_30 1;
BA_ "GenSigSendType" SG_ 1760 Data_Byte_2_30 6;
BA_ "GenSigAutoGenDsp" SG_ 1760 Data_Byte_3_30 1;
BA_ "GenSigAutoGenSnd" SG_ 1760 Data_Byte_3_30 1;
BA_ "GenSigSendType" SG_ 1760 Data_Byte_3_30 6;
BA_ "GenSigAutoGenDsp" SG_ 1760 Data_Byte_4_30 1;
BA_ "GenSigAutoGenSnd" SG_ 1760 Data_Byte_4_30 1;
BA_ "GenSigSendType" SG_ 1760 Data_Byte_4_30 6;
BA_ "GenSigAutoGenDsp" SG_ 1760 Data_Byte_5_30 1;
BA_ "GenSigAutoGenSnd" SG_ 1760 Data_Byte_5_30 1;
BA_ "GenSigSendType" SG_ 1760 Data_Byte_5_30 6;
BA_ "GenSigAutoGenDsp" SG_ 1761 Module_ID_31 1;
BA_ "GenSigAutoGenSnd" SG_ 1761 Module_ID_31 1;
BA_ "GenSigSendType" SG_ 1761 Module_ID_31 6;
BA_ "GenSigAutoGenDsp" SG_ 1761 Update_Indikator_31 1;
BA_ "GenSigAutoGenSnd" SG_ 1761 Update_Indikator_31 1;
BA_ "GenSigSendType" SG_ 1761 Update_Indikator_31 6;
BA_ "GenSigAutoGenDsp" SG_ 1761 Funktions_ID_31 1;
BA_ "GenSigAutoGenSnd" SG_ 1761 Funktions_ID_31 1;
BA_ "GenSigSendType" SG_ 1761 Funktions_ID_31 6;
BA_ "GenSigAutoGenDsp" SG_ 1761 OpCode_31 1;
BA_ "GenSigAutoGenSnd" SG_ 1761 OpCode_31 1;
BA_ "GenSigSendType" SG_ 1761 OpCode_31 6;
BA_ "GenSigAutoGenDsp" SG_ 1761 Controller_ID_31 1;
BA_ "GenSigAutoGenSnd" SG_ 1761 Controller_ID_31 1;
BA_ "GenSigSendType" SG_ 1761 Controller_ID_31 6;
BA_ "GenSigAutoGenDsp" SG_ 1761 Data_Byte_1_31 1;
BA_ "GenSigAutoGenSnd" SG_ 1761 Data_Byte_1_31 1;
BA_ "GenSigSendType" SG_ 1761 Data_Byte_1_31 6;
BA_ "GenSigAutoGenDsp" SG_ 1761 Data_Byte_2_31 1;
BA_ "GenSigAutoGenSnd" SG_ 1761 Data_Byte_2_31 1;
BA_ "GenSigSendType" SG_ 1761 Data_Byte_2_31 6;
BA_ "GenSigAutoGenDsp" SG_ 1761 Data_Byte_3_31 1;
BA_ "GenSigAutoGenSnd" SG_ 1761 Data_Byte_3_31 1;
BA_ "GenSigSendType" SG_ 1761 Data_Byte_3_31 6;
BA_ "GenSigAutoGenDsp" SG_ 1761 Data_Byte_4_31 1;
BA_ "GenSigAutoGenSnd" SG_ 1761 Data_Byte_4_31 1;
BA_ "GenSigSendType" SG_ 1761 Data_Byte_4_31 6;
BA_ "GenSigAutoGenDsp" SG_ 1761 Data_Byte_5_31 1;
BA_ "GenSigAutoGenSnd" SG_ 1761 Data_Byte_5_31 1;
BA_ "GenSigSendType" SG_ 1761 Data_Byte_5_31 6;
BA_ "GenSigAutoGenDsp" SG_ 1762 Module_ID_32 1;
BA_ "GenSigAutoGenSnd" SG_ 1762 Module_ID_32 1;
BA_ "GenSigSendType" SG_ 1762 Module_ID_32 6;
BA_ "GenSigAutoGenDsp" SG_ 1762 Update_Indikator_32 1;
BA_ "GenSigAutoGenSnd" SG_ 1762 Update_Indikator_32 1;
BA_ "GenSigSendType" SG_ 1762 Update_Indikator_32 6;
BA_ "GenSigAutoGenDsp" SG_ 1762 Funktions_ID_32 1;
BA_ "GenSigAutoGenSnd" SG_ 1762 Funktions_ID_32 1;
BA_ "GenSigSendType" SG_ 1762 Funktions_ID_32 6;
BA_ "GenSigAutoGenDsp" SG_ 1762 OpCode_32 1;
BA_ "GenSigAutoGenSnd" SG_ 1762 OpCode_32 1;
BA_ "GenSigSendType" SG_ 1762 OpCode_32 6;
BA_ "GenSigAutoGenDsp" SG_ 1762 Controller_ID_32 1;
BA_ "GenSigAutoGenSnd" SG_ 1762 Controller_ID_32 1;
BA_ "GenSigSendType" SG_ 1762 Controller_ID_32 6;
BA_ "GenSigAutoGenDsp" SG_ 1762 Data_Byte_1_32 1;
BA_ "GenSigAutoGenSnd" SG_ 1762 Data_Byte_1_32 1;
BA_ "GenSigSendType" SG_ 1762 Data_Byte_1_32 6;
BA_ "GenSigAutoGenDsp" SG_ 1762 Data_Byte_2_32 1;
BA_ "GenSigAutoGenSnd" SG_ 1762 Data_Byte_2_32 1;
BA_ "GenSigSendType" SG_ 1762 Data_Byte_2_32 6;
BA_ "GenSigAutoGenDsp" SG_ 1762 Data_Byte_3_32 1;
BA_ "GenSigAutoGenSnd" SG_ 1762 Data_Byte_3_32 1;
BA_ "GenSigSendType" SG_ 1762 Data_Byte_3_32 6;
BA_ "GenSigAutoGenDsp" SG_ 1762 Data_Byte_4_32 1;
BA_ "GenSigAutoGenSnd" SG_ 1762 Data_Byte_4_32 1;
BA_ "GenSigSendType" SG_ 1762 Data_Byte_4_32 6;
BA_ "GenSigAutoGenDsp" SG_ 1762 Data_Byte_5_32 1;
BA_ "GenSigAutoGenSnd" SG_ 1762 Data_Byte_5_32 1;
BA_ "GenSigSendType" SG_ 1762 Data_Byte_5_32 6;
BA_ "GenSigAutoGenDsp" SG_ 993 CL1_Drehzahlanhebung 1;
BA_ "GenSigAutoGenSnd" SG_ 993 CL1_Drehzahlanhebung 1;
BA_ "GenSigSendType" SG_ 993 CL1_Drehzahlanhebung 3;
BA_ "GenSigAutoGenDsp" SG_ 993 CL1_Zuheizer 1;
BA_ "GenSigAutoGenSnd" SG_ 993 CL1_Zuheizer 1;
BA_ "GenSigSendType" SG_ 993 CL1_Zuheizer 3;
BA_ "GenSigAutoGenDsp" SG_ 993 CL1_HzgHeckscheibe 1;
BA_ "GenSigAutoGenSnd" SG_ 993 CL1_HzgHeckscheibe 1;
BA_ "GenSigSendType" SG_ 993 CL1_HzgHeckscheibe 3;
BA_ "GenSigAutoGenDsp" SG_ 993 CL1_HzgFrontscheibe 1;
BA_ "GenSigAutoGenSnd" SG_ 993 CL1_HzgFrontscheibe 1;
BA_ "GenSigSendType" SG_ 993 CL1_HzgFrontscheibe 3;
BA_ "GenSigAutoGenDsp" SG_ 993 CL1_Kompressor 1;
BA_ "GenSigAutoGenSnd" SG_ 993 CL1_Kompressor 1;
BA_ "GenSigSendType" SG_ 993 CL1_Kompressor 3;
BA_ "GenSigAutoGenDsp" SG_ 993 CL1_Heizung_aus 1;
BA_ "GenSigAutoGenSnd" SG_ 993 CL1_Heizung_aus 1;
BA_ "GenSigSendType" SG_ 993 CL1_Heizung_aus 3;
BA_ "GenSigAutoGenDsp" SG_ 993 CL1_Kompressormoment_alt 1;
BA_ "GenSigAutoGenSnd" SG_ 993 CL1_Kompressormoment_alt 1;
BA_ "GenSigSendType" SG_ 993 CL1_Kompressormoment_alt 3;
BA_ "GenSigStartValue" SG_ 993 CL1_Kompressormoment_alt 1;
BA_ "GenSigAutoGenDsp" SG_ 993 CL1_Kaeltemitteldruck_alt 1;
BA_ "GenSigAutoGenSnd" SG_ 993 CL1_Kaeltemitteldruck_alt 1;
BA_ "GenSigSendType" SG_ 993 CL1_Kaeltemitteldruck_alt 3;
BA_ "GenSigStartValue" SG_ 993 CL1_Kaeltemitteldruck_alt 1;
BA_ "GenSigAutoGenDsp" SG_ 993 CL1_AussenTemp 1;
BA_ "GenSigAutoGenSnd" SG_ 993 CL1_AussenTemp 1;
BA_ "GenSigSendType" SG_ 993 CL1_AussenTemp 0;
BA_ "Fehlerwert" SG_ 993 CL1_AussenTemp 255;
BA_ "GenSigAutoGenDsp" SG_ 993 CL1_KaeltemittelDruck 1;
BA_ "GenSigAutoGenSnd" SG_ 993 CL1_KaeltemittelDruck 1;
BA_ "GenSigSendType" SG_ 993 CL1_KaeltemittelDruck 0;
BA_ "GenSigStartValue" SG_ 993 CL1_KaeltemittelDruck 255;
BA_ "Fehlerwert" SG_ 993 CL1_KaeltemittelDruck 255;
BA_ "GenSigAutoGenDsp" SG_ 993 CL1_Last_Kompressor 1;
BA_ "GenSigAutoGenSnd" SG_ 993 CL1_Last_Kompressor 1;
BA_ "GenSigSendType" SG_ 993 CL1_Last_Kompressor 0;
BA_ "Fehlerwert" SG_ 993 CL1_Last_Kompressor 255;
BA_ "GenSigAutoGenDsp" SG_ 993 CL1_Geblaeselast 1;
BA_ "GenSigAutoGenSnd" SG_ 993 CL1_Geblaeselast 1;
BA_ "GenSigSendType" SG_ 993 CL1_Geblaeselast 0;
BA_ "Fehlerwert" SG_ 993 CL1_Geblaeselast 255;
BA_ "GenSigAutoGenDsp" SG_ 993 CL1_Strg_Kluefter 1;
BA_ "GenSigAutoGenSnd" SG_ 993 CL1_Strg_Kluefter 1;
BA_ "GenSigSendType" SG_ 993 CL1_Strg_Kluefter 0;
BA_ "Fehlerwert" SG_ 993 CL1_Strg_Kluefter 255;
BA_ "GenSigAutoGenDsp" SG_ 993 CL1_Temp_in_F 1;
BA_ "GenSigAutoGenSnd" SG_ 993 CL1_Temp_in_F 1;
BA_ "GenSigSendType" SG_ 993 CL1_Temp_in_F 0;
BA_ "GenSigAutoGenDsp" SG_ 993 CL1_AC_Schalter 1;
BA_ "GenSigAutoGenSnd" SG_ 993 CL1_AC_Schalter 1;
BA_ "GenSigSendType" SG_ 993 CL1_AC_Schalter 0;
BA_ "GenSigAutoGenDsp" SG_ 993 CL1_WAPU_Zuschaltung 1;
BA_ "GenSigAutoGenSnd" SG_ 993 CL1_WAPU_Zuschaltung 1;
BA_ "GenSigSendType" SG_ 993 CL1_WAPU_Zuschaltung 0;
BA_ "GenSigAutoGenDsp" SG_ 993 CL1_Restwaerme 1;
BA_ "GenSigAutoGenSnd" SG_ 993 CL1_Restwaerme 1;
BA_ "GenSigSendType" SG_ 993 CL1_Restwaerme 0;
BA_ "GenSigAutoGenDsp" SG_ 993 CL1_PTC_Clima 1;
BA_ "GenSigAutoGenSnd" SG_ 993 CL1_PTC_Clima 1;
BA_ "GenSigSendType" SG_ 993 CL1_PTC_Clima 0;
BA_ "GenSigAutoGenDsp" SG_ 993 CL1_KD_Fehler 1;
BA_ "GenSigAutoGenSnd" SG_ 993 CL1_KD_Fehler 1;
BA_ "GenSigSendType" SG_ 993 CL1_KD_Fehler 0;
BA_ "GenSigAutoGenDsp" SG_ 993 KL_Thermomanagement 1;
BA_ "GenSigAutoGenSnd" SG_ 993 KL_Thermomanagement 1;
BA_ "GenSigSendType" SG_ 993 KL_Thermomanagement 0;
VAL_ 337 AB1_FrontCrash 1 "Front_Crash" 0 "kein_Front_Crash" ;
VAL_ 337 AB1_HeckCrash 0 "kein_Heck_Crash" 1 "Heck_Crash" ;
VAL_ 337 AB1_Crash_FT 1 "Seiten_Crash_Fahrer" 0 "kein_Seiten_Crash_Fahrer" ;
VAL_ 337 AB1_Crash_BT 0 "kein_Seiten_Crash_Beifahrer" 1 "Seiten_Crash_Beifahrer" ;
VAL_ 337 AB1_Rollover 1 "Rollover" 0 "kein_Rollover" ;
VAL_ 337 AB1_CrashStaerke 1 "Gurtstraffer_Schw_ueberschritten" 3 "US_Schw_ueberschritten" 6 "RDW_Schw_ueberschritten" 2 "US_Schw_ueberschritten" 5 "RDW_Schw_ueberschritten" 4 "RDW_Schw_ueberschritten" 0 "kein_Crash" 7 "RDW_Schw_ueberschritten" ;
VAL_ 337 AB1_AirbagLampe_ein 1 "Lampe_ein" 0 "Lampe_aus" ;
VAL_ 337 AB1_Airbag_deaktiviert 0 "aktiv" 1 "deaktiviert" ;
VAL_ 337 AB1_Beif_Airbag_deaktiviert 1 "deaktiviert" 0 "aktiv" ;
VAL_ 337 AB1_Systemfehler 1 "Systemfehler" 0 "kein_Fehler" ;
VAL_ 337 AB1_Fa_Gurt 2 "Gurt_nicht_gesteckt" 3 "Gurt_gesteckt" 0 "nicht_verfuegbar" 1 "Fehler" ;
VAL_ 337 AB1_Bf_Gurt 2 "Gurt_nicht_gesteckt" 3 "Gurt_gesteckt" 0 "nicht_verfuegbar" 1 "Fehler" ;
VAL_ 337 AB1_Diagnose 0 "nicht_in_Diagnose" 1 "in_Diagnose" ;
VAL_ 337 AB1_Stellglied 1 "im_Stellgliedtest" 0 "nicht_im_Stellgliedtest" ;
VAL_ 337 AB1_BF_Anschnall 0 "keine_Warnung" 1 "Gurtwarnung_ausloesen" ;
VAL_ 337 AB1_KD_Fehler 1 "Fehlerspeichereintrag" 0 "kein_Fehlerspeichereintrag" ;
VAL_ 1429 AG1_BL_def 0 "i_O" 1 "defekt" ;
VAL_ 1429 AG1_KD_Fehler 1 "Fehlerspeichereintrag" 0 "kein_Fehlerspeichereintrag" ;
VAL_ 1429 AG1_ANH_Erk 1 "Anhaenger_erkannt" 0 "kein_Anhaenger_erkannt" ;
VAL_ 1624 BEM_02_Abschaltstufen 1 "Stufe1" 2 "Stufe2" 0 "Stufe0" 3 "Stufe3" ;
VAL_ 1624 BEM_STH_Zielzeit 14 "Init" 15 "Fehler" ;
VAL_ 1624 BEM_MMI_Vorwarnung 0 "keine_Anzeige" 1 "MMI_Vorwarnung" ;
VAL_ 1624 BEM_Generatordiagnose 1 "Ladekontrolle_ein" 2 "Generator_def" 0 "keine_Anzeige" ;
VAL_ 1624 BEM_Red_Innengeblaese 3 "Abschaltung_Kompressor" 0 "keine_Reduzierung" 1 "Reduzierung_Stufe1" 2 "Reduzierung_Stufe2" ;
VAL_ 1624 BEM_STH_Einschaltverbot 0 "volle_Verfuegbarkeit" 1 "nicht_aktivierbar" ;
VAL_ 1624 BEM_HL_Regelung_Status 3 "Regelung_Stufe3" 1 "Regelung_Stufe1" 4 "VNA" 7 "Default" 0 "Regelung_inaktiv" 2 "Regelung_Stufe2" ;
VAL_ 1624 BEM_Ladezustand 14 "Init" 15 "Fehler" ;
VAL_ 1624 BEM_Batteriediagnose 2 "Batterie_ab_erkannt" 1 "keine_Freigabe_Start_Stopp" 3 "Batterie_schwach" 0 "keine_Anzeige" ;
VAL_ 1624 BEM_REK_aktiv 0 "keine_Reku_Freigabe" 1 "Reku_Freigabe" ;
VAL_ 1624 BEM_EMLIN_ungueltig 0 "Signale_gueltig" 1 "Signale_ungueltig" ;
VAL_ 1624 BEM_Batt_Ab 0 "verbunden" 1 "nicht_verbunden" ;
VAL_ 1624 BEM_UGenSoll 63 "Fehler" ;
VAL_ 1461 B10_QB_Wegimp_VL 0 "gueltiger_Wert" 1 "Ersatz_Init_oder_Fehlerwert" ;
VAL_ 1461 B10_QB_Wegimp_VR 0 "gueltiger_Wert" 1 "Ersatz_Init_oder_Fehlerwert" ;
VAL_ 1461 B10_QB_Wegimp_HL 0 "gueltiger_Wert" 1 "Ersatz_Init_oder_Fehlerwert" ;
VAL_ 1461 B10_QB_Wegimp_HR 0 "gueltiger_Wert" 1 "Ersatz_Init_oder_Fehlerwert" ;
VAL_ 1461 B10_Wegimp_VL 1022 "Unterspannung" 1021 "Initwert" 1023 "Sensorfehler" ;
VAL_ 1461 B10_Wegimp_VR 1022 "Unterspannung" 1023 "Sensorfehler" 1021 "Initwert" ;
VAL_ 1461 B10_Wegimp_HL 1021 "Initwert" 1022 "Unterspannung" 1023 "Sensorfehler" ;
VAL_ 1461 B10_Wegimp_HR 1022 "Unterspannung" 1023 "Sensorfehler" 1021 "Initwert" ;
VAL_ 1461 B10_QB_Fahrtr_VL 0 "gueltiger_Wert" 1 "Ersatz_Init_oder_Fehlerwert" ;
VAL_ 1461 B10_QB_Fahrtr_VR 0 "gueltiger_Wert" 1 "Ersatz_Init_oder_Fehlerwert" ;
VAL_ 1461 B10_QB_Fahrtr_HL 0 "gueltiger_Wert" 1 "Ersatz_Init_oder_Fehlerwert" ;
VAL_ 1461 B10_QB_Fahrtr_HR 0 "gueltiger_Wert" 1 "Ersatz_Init_oder_Fehlerwert" ;
VAL_ 1461 B10_Fahrtr_VL 1 "Rueckwaerts" 0 "Vorwaerts" ;
VAL_ 1461 B10_Fahrtr_VR 1 "Rueckwaerts" 0 "Vorwaerts" ;
VAL_ 1461 B10_Fahrtr_HL 1 "Rueckwaerts" 0 "Vorwaerts" ;
VAL_ 1461 B10_Fahrtr_HR 1 "Rueckwaerts" 0 "Vorwaerts" ;
VAL_ 1393 BS2_U_BATT 255 "Fehler" ;
VAL_ 1393 BS2_Heckscheibe_aus 1 "Verbraucher_abschalten" 0 "Grundzustand" ;
VAL_ 1393 BS2_Frontscheibe_aus 1 "Verbraucher_abschalten" 0 "Grundzustand" ;
VAL_ 1393 BS2_Aussenspiegel_aus 1 "Verbraucher_abschalten" 0 "Grundzustand" ;
VAL_ 1393 BS2_Sitzheizung_aus 1 "Verbraucher_abschalten" 0 "Grundzustand" ;
VAL_ 1393 BS2_aus_Lenkradheizung 1 "Verbraucher_abschalten" 0 "Grundzustand" ;
VAL_ 1393 BS2_aus_Wischwasserhzg 1 "Verbraucher_abschalten" 0 "Grundzustand" ;
VAL_ 1393 BS2_aus_Sitzlueftung 1 "Verbraucher_abschalten" 0 "Grundzustand" ;
VAL_ 1393 BS2_Klimaanlage_aus 1 "Verbraucher_abschalten" 0 "Grundzustand" ;
VAL_ 1393 BS2_Wake_Up_ACAN 0 "kein_Wecken_ACAN" 1 "Wecken_ACAN" ;
VAL_ 1393 BS2_Weckursache_ACAN 0 "kein_EKP_Vorlauf" 2 "Weckursache_StHzg" 3 "Weckursache_Tuerkontakt" ;
VAL_ 1393 BS2_VB_2_Battarie 0 "Nur_eine_Batterie" 1 "zweite_Batterie_verbaut" ;
VAL_ 1397 BS3_Klemme_S 1 "S_Kontakt_aktiv" 0 "Grundzustand" ;
VAL_ 1397 BS3_Klemme_15 0 "Grundzustand" 1 "Klemme_15_aktiv" ;
VAL_ 1397 BS3_Klemme_X 0 "Grundzustand" 1 "Klemme_X_aktiv" ;
VAL_ 1397 BS3_Klemme_50 1 "Klemme_50_aktiv" 0 "Grundzustand" ;
VAL_ 1397 BS3_Klemme_P 0 "Grundzustand" 1 "Klemme_P_aktiv" ;
VAL_ 1397 BS3_2_Drehzahl 1 "Drehzahlanheb_Stufe2_gefordert" 0 "Grundzustand" ;
VAL_ 1397 BS3_Klemme_15_Motorraum 1 "Klemme_14_aktiv" 0 "Grundzustand" ;
VAL_ 1397 BS3_Ladekontrollampe 0 "Grundzustand" 1 "Klemme_L_aktiv" ;
VAL_ 1397 BS3_Drehzahlanhebung 0 "Grundzustand" 1 "Drehzahlanheb_Stufe1_gefordert" ;
VAL_ 1397 BS3_Bordnetzbatt 1 "kritisch" 2 "entladen" 0 "iO" 3 "Fehler" ;
VAL_ 1397 BS3_Starterbatt 1 "kritisch" 2 "entladen" 0 "iO" 3 "Fehler" ;
VAL_ 1397 BS3_KD_Fehler 1 "Fehlerspeichereintrag" 0 "kein_Fehlerspeichereintrag" ;
VAL_ 1397 BS3_LWR_Fehler 0 "LWR_i_O" 1 "LWR_Fehler" ;
VAL_ 1397 BS3_Haubenkontakt 0 "Haube_geschlossen" 1 "Haube_offen" ;
VAL_ 1397 BS3_K_Luefter_ein 0 "keine_Anforderung" 1 "einschalten" ;
VAL_ 1397 BS3_Ab_Batterie 1 "Batterie_ab" 0 "Batterie_am_Bordnetz" ;
VAL_ 1397 BS3_Verglasung_zu 0 "Keine_Aktion" 1 "Verglasung_schliessen" ;
VAL_ 1397 BS3_Starterlaubnis 0 "Start_nicht_erlaubt" 1 "Start_erlaubt" ;
VAL_ 1136 BSK_Blk_links 1 "Kontrolllampe_Blk_L_ein" ;
VAL_ 1136 BSK_Blk_rechts 1 "Kontrolllampe_Blk_R_ein" ;
VAL_ 1136 BSK_Anhaenger 1 "Anhaengerblinken_ein" ;
VAL_ 1136 BSK_Warnblinker 1 "Warnblinkstatus_ein" ;
VAL_ 1136 BSK_DWA_Akku 0 "Akku_i_O" 1 "DWA_Akku_leer" ;
VAL_ 1136 BSK_Rueckfahrlicht 1 "Rueckfahrlicht_ein" ;
VAL_ 1136 BSK_Sammelfehler_AKI 0 "kein_Sammelfehler" 1 "Sammelfehler" ;
VAL_ 1136 BSK_Ladekontrollampe 0 "Grundzustand" 1 "Klemme_L_aktiv" ;
VAL_ 1136 BSK_FT_geoeffnet 0 "Tuer_geschlossen" 1 "Tuer_offen" ;
VAL_ 1136 BSK_BT_geoeffnet 0 "Tuer_geschlossen" 1 "Tuer_offen" ;
VAL_ 1136 BSK_HL_geoeffnet 0 "Tuer_geschlossen" 1 "Tuer_offen" ;
VAL_ 1136 BSK_HR_geoeffnet 0 "Tuer_geschlossen" 1 "Tuer_offen" ;
VAL_ 1136 BSK_MH_geoeffnet 0 "Haube_geschlossen" 1 "Haube_offen" ;
VAL_ 1136 BSK_HD_Hauptraste 0 "geschlossen" 1 "Hauptraste" ;
VAL_ 1136 BSK_HD_Vorraste 0 "geschlossen" 1 "Vorraste" ;
VAL_ 1136 BSK_Unterspannung 0 "OK" 1 "Unterspannung" ;
VAL_ 1136 BSK_Display 127 "Fehler" ;
VAL_ 1136 BSK_Display_def 0 "Kl_58d_i_O" 1 "Kl_58d_n_i_O" ;
VAL_ 1136 BSK_Klemme_58t 127 "Fehler" ;
VAL_ 1136 BSK_Klemme_58t_def 1 "Kl_58t_n_i_O" 0 "Kl_58t_i_O" ;
VAL_ 1136 BSK_Interlock 1 "Lampe_ein" 0 "Lampe_aus" ;
VAL_ 1136 BSK_Buzzer 0 "kein_Gong" 1 "Gong_ansteuern" ;
VAL_ 1136 BSK_Ruecks_HL_verriegelt 1 "nicht_verriegelt" 0 "verriegelt" ;
VAL_ 1136 BSK_Ruecks_HR_verriegelt 0 "verriegelt" 1 "nicht_verriegelt" ;
VAL_ 1136 BSK_Def_Lampe 0 "i_O" 1 "defekt" ;
VAL_ 1136 BSK_NSL_LED_Pfad 1 "CAN" 0 "Draht" ;
VAL_ 1136 BSK_AFL_defekt 1 "defekt" 0 "i_O" ;
VAL_ 1136 BSK_BSG_defekt 1 "defekt" 0 "i_O" ;
VAL_ 1136 BSK_Standlicht 1 "Kl58_ein" ;
VAL_ 1136 BSK_Parklicht_links 1 "Parklicht_L_ein" ;
VAL_ 1136 BSK_Parklicht_rechts 1 "Parklicht_R_ein" ;
VAL_ 1136 BSK_Abblendlicht 1 "Kl56b_ein" 0 "aus" ;
VAL_ 1136 BSK_Nebellicht 1 "Kl83a_ein" 0 "aus" ;
VAL_ 1136 BSK_Tankklappe 0 "Tankklappe_zu" 1 "Tankklappe_offen" ;
VAL_ 1136 BSK_FFB_Bat 0 "kein_Text" 1 "Text" ;
VAL_ 1136 BSK_FLA_Soft_LED 0 "inaktiv" 1 "aktiv" ;
VAL_ 1136 BSK_FLA_Sensor_blockiert 1 "Sensor_blockiert" 0 "Sensor_iO" ;
VAL_ 1136 BSK_FLA_Defekt 1 "System_defekt" 0 "System_iO" ;
VAL_ 1136 BCM_Remotestart_Betrieb 1 "RS_Betrieb" 0 "kein_RS_Betrieb" ;
VAL_ 1136 BSK_Ruhespannung 0 "Init" 31 "Fehler" ;
VAL_ 1136 BSK_Nebelschlusslicht 1 "Kl83b_ein" 0 "aus" ;
VAL_ 1136 BSK_Fernlicht 1 "Kl56a_ein" 0 "aus" ;
VAL_ 1136 BSK_Tagfahrlicht 1 "Tagfahrlicht_ein" ;
VAL_ 993 CL1_Drehzahlanhebung 1 "Anhebung" 0 "keine_Anhebung" ;
VAL_ 993 CL1_Zuheizer 1 "Ein" 0 "Aus" ;
VAL_ 993 CL1_HzgHeckscheibe 1 "Ein" 0 "Aus" ;
VAL_ 993 CL1_HzgFrontscheibe 1 "Ein" 0 "Aus" ;
VAL_ 993 CL1_Kompressor 1 "Ein" 0 "Aus" ;
VAL_ 993 CL1_Heizung_aus 0 "Heizleistung" 1 "keine_Heizleistung" ;
VAL_ 993 CL1_Kompressormoment_alt 0 "aktuell" 1 "veraltet" ;
VAL_ 993 CL1_Kaeltemitteldruck_alt 0 "aktuell" 1 "veraltet" ;
VAL_ 993 CL1_AussenTemp 255 "Fehler" ;
VAL_ 993 CL1_KaeltemittelDruck 255 "Fehler" ;
VAL_ 993 CL1_Last_Kompressor 255 "Fehler" ;
VAL_ 993 CL1_Geblaeselast 255 "Fehler" ;
VAL_ 993 CL1_Strg_Kluefter 255 "Fehler" ;
VAL_ 993 CL1_Temp_in_F 1 "Fahrenheit" 0 "Grad_C" ;
VAL_ 993 CL1_AC_Schalter 1 "ein_gedrueckt_oder_an" 0 "aus" ;
VAL_ 993 CL1_WAPU_Zuschaltung 1 "WAPU_AUS" 0 "WAPU_EIN" ;
VAL_ 993 CL1_Restwaerme 0 "nicht_aktiviert" 1 "aktiviert" ;
VAL_ 993 CL1_KD_Fehler 1 "Fehlerspeichereintrag" 0 "kein_Fehlerspeichereintrag" ;
VAL_ 993 KL_Thermomanagement 3 "volle_Freigabe_TMM" 0 "keine_Freigabe_TMM" 2 "mittlere_Freigabe_TMM" 1 "kleine_Freigabe_TMM" ;
